AUTOSAR XML (schema 4-0-3)
package /AUTOSAR_NvM/SwComponentTypes
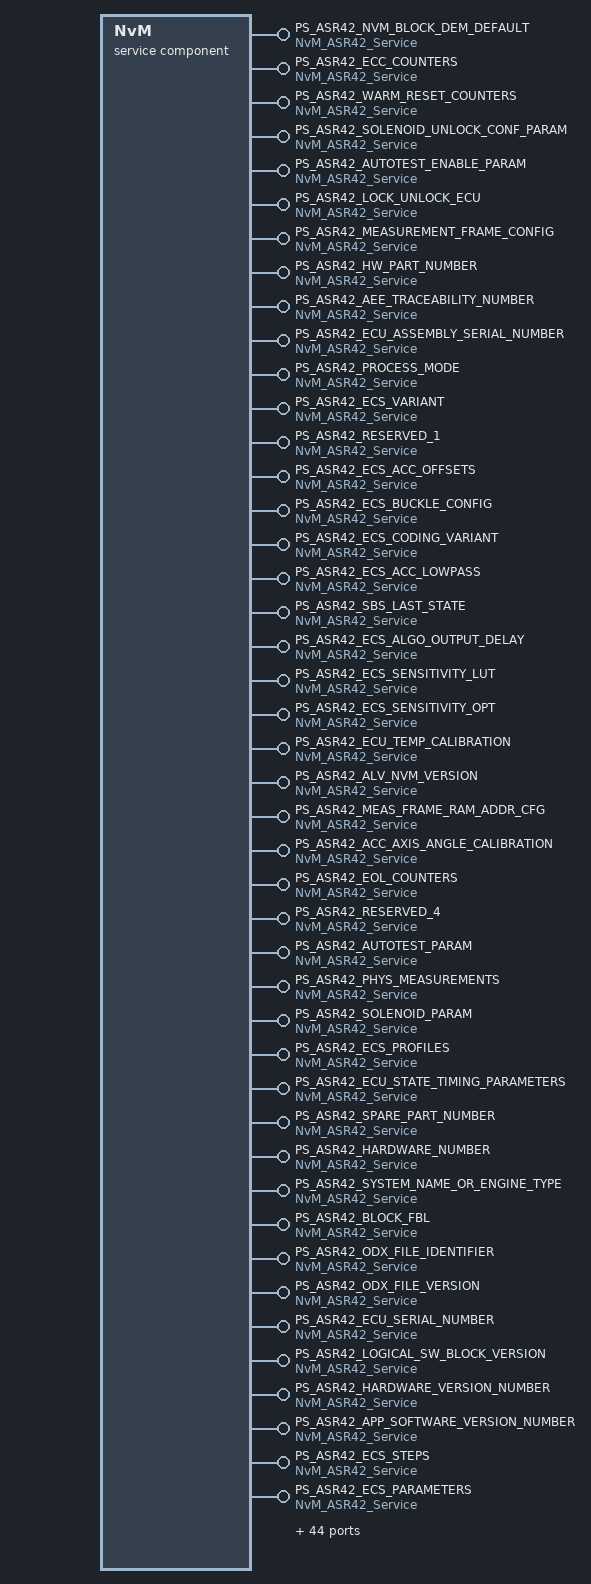
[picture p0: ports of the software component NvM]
  service sw component type NvM
    88 x provide port:
      PS_ASR42_NVM_BLOCK_DEM_DEFAULT: provided-interface=NvM_ASR42_Service
      PS_ASR42_ECC_COUNTERS: provided-interface=NvM_ASR42_Service
      PS_ASR42_WARM_RESET_COUNTERS: provided-interface=NvM_ASR42_Service
      PS_ASR42_SOLENOID_UNLOCK_CONF_PARAM: provided-interface=NvM_ASR42_Service
      PS_ASR42_AUTOTEST_ENABLE_PARAM: provided-interface=NvM_ASR42_Service
      PS_ASR42_LOCK_UNLOCK_ECU: provided-interface=NvM_ASR42_Service
      PS_ASR42_MEASUREMENT_FRAME_CONFIG: provided-interface=NvM_ASR42_Service
      PS_ASR42_HW_PART_NUMBER: provided-interface=NvM_ASR42_Service
      PS_ASR42_AEE_TRACEABILITY_NUMBER: provided-interface=NvM_ASR42_Service
      PS_ASR42_ECU_ASSEMBLY_SERIAL_NUMBER: provided-interface=NvM_ASR42_Service
      PS_ASR42_PROCESS_MODE: provided-interface=NvM_ASR42_Service
      PS_ASR42_ECS_VARIANT: provided-interface=NvM_ASR42_Service
      PS_ASR42_RESERVED_1: provided-interface=NvM_ASR42_Service
      PS_ASR42_ECS_ACC_OFFSETS: provided-interface=NvM_ASR42_Service
      PS_ASR42_ECS_BUCKLE_CONFIG: provided-interface=NvM_ASR42_Service
      PS_ASR42_ECS_CODING_VARIANT: provided-interface=NvM_ASR42_Service
      PS_ASR42_ECS_ACC_LOWPASS: provided-interface=NvM_ASR42_Service
      PS_ASR42_SBS_LAST_STATE: provided-interface=NvM_ASR42_Service
      PS_ASR42_ECS_ALGO_OUTPUT_DELAY: provided-interface=NvM_ASR42_Service
      PS_ASR42_ECS_SENSITIVITY_LUT: provided-interface=NvM_ASR42_Service
      PS_ASR42_ECS_SENSITIVITY_OPT: provided-interface=NvM_ASR42_Service
      PS_ASR42_ECU_TEMP_CALIBRATION: provided-interface=NvM_ASR42_Service
      PS_ASR42_ALV_NVM_VERSION: provided-interface=NvM_ASR42_Service
      PS_ASR42_MEAS_FRAME_RAM_ADDR_CFG: provided-interface=NvM_ASR42_Service
      PS_ASR42_ACC_AXIS_ANGLE_CALIBRATION: provided-interface=NvM_ASR42_Service
      PS_ASR42_EOL_COUNTERS: provided-interface=NvM_ASR42_Service
      PS_ASR42_RESERVED_4: provided-interface=NvM_ASR42_Service
      PS_ASR42_AUTOTEST_PARAM: provided-interface=NvM_ASR42_Service
      PS_ASR42_PHYS_MEASUREMENTS: provided-interface=NvM_ASR42_Service
      PS_ASR42_SOLENOID_PARAM: provided-interface=NvM_ASR42_Service
      PS_ASR42_ECS_PROFILES: provided-interface=NvM_ASR42_Service
      PS_ASR42_ECU_STATE_TIMING_PARAMETERS: provided-interface=NvM_ASR42_Service
      PS_ASR42_SPARE_PART_NUMBER: provided-interface=NvM_ASR42_Service
      PS_ASR42_HARDWARE_NUMBER: provided-interface=NvM_ASR42_Service
      PS_ASR42_SYSTEM_NAME_OR_ENGINE_TYPE: provided-interface=NvM_ASR42_Service
      PS_ASR42_BLOCK_FBL: provided-interface=NvM_ASR42_Service
      PS_ASR42_ODX_FILE_IDENTIFIER: provided-interface=NvM_ASR42_Service
      PS_ASR42_ODX_FILE_VERSION: provided-interface=NvM_ASR42_Service
      PS_ASR42_ECU_SERIAL_NUMBER: provided-interface=NvM_ASR42_Service
      PS_ASR42_LOGICAL_SW_BLOCK_VERSION: provided-interface=NvM_ASR42_Service
      PS_ASR42_HARDWARE_VERSION_NUMBER: provided-interface=NvM_ASR42_Service
      PS_ASR42_APP_SOFTWARE_VERSION_NUMBER: provided-interface=NvM_ASR42_Service
      PS_ASR42_ECS_STEPS: provided-interface=NvM_ASR42_Service
      PS_ASR42_ECS_PARAMETERS: provided-interface=NvM_ASR42_Service
      PS_NVM_BLOCK_DEM_DEFAULT: provided-interface=NvMService
      PS_ECC_COUNTERS: provided-interface=NvMService
      PS_WARM_RESET_COUNTERS: provided-interface=NvMService
      PS_SOLENOID_UNLOCK_CONF_PARAM: provided-interface=NvMService
      PS_AUTOTEST_ENABLE_PARAM: provided-interface=NvMService
      PS_LOCK_UNLOCK_ECU: provided-interface=NvMService
      PS_MEASUREMENT_FRAME_CONFIG: provided-interface=NvMService
      PS_HW_PART_NUMBER: provided-interface=NvMService
      PS_AEE_TRACEABILITY_NUMBER: provided-interface=NvMService
      PS_ECU_ASSEMBLY_SERIAL_NUMBER: provided-interface=NvMService
      PS_PROCESS_MODE: provided-interface=NvMService
      PS_ECS_VARIANT: provided-interface=NvMService
      PS_RESERVED_1: provided-interface=NvMService
      PS_ECS_ACC_OFFSETS: provided-interface=NvMService
      PS_ECS_BUCKLE_CONFIG: provided-interface=NvMService
      PS_ECS_CODING_VARIANT: provided-interface=NvMService
      PS_ECS_ACC_LOWPASS: provided-interface=NvMService
      PS_SBS_LAST_STATE: provided-interface=NvMService
      PS_ECS_ALGO_OUTPUT_DELAY: provided-interface=NvMService
      PS_ECS_SENSITIVITY_LUT: provided-interface=NvMService
      PS_ECS_SENSITIVITY_OPT: provided-interface=NvMService
      PS_ECU_TEMP_CALIBRATION: provided-interface=NvMService
      PS_ALV_NVM_VERSION: provided-interface=NvMService
      PS_MEAS_FRAME_RAM_ADDR_CFG: provided-interface=NvMService
      PS_ACC_AXIS_ANGLE_CALIBRATION: provided-interface=NvMService
      PS_EOL_COUNTERS: provided-interface=NvMService
      PS_RESERVED_4: provided-interface=NvMService
      PS_AUTOTEST_PARAM: provided-interface=NvMService
      PS_PHYS_MEASUREMENTS: provided-interface=NvMService
      PS_SOLENOID_PARAM: provided-interface=NvMService
      PS_ECS_PROFILES: provided-interface=NvMService
      PS_ECU_STATE_TIMING_PARAMETERS: provided-interface=NvMService
      PS_SPARE_PART_NUMBER: provided-interface=NvMService
      PS_HARDWARE_NUMBER: provided-interface=NvMService
      PS_SYSTEM_NAME_OR_ENGINE_TYPE: provided-interface=NvMService
      PS_BLOCK_FBL: provided-interface=NvMService
      PS_ODX_FILE_IDENTIFIER: provided-interface=NvMService
      PS_ODX_FILE_VERSION: provided-interface=NvMService
      PS_ECU_SERIAL_NUMBER: provided-interface=NvMService
      PS_LOGICAL_SW_BLOCK_VERSION: provided-interface=NvMService
      PS_HARDWARE_VERSION_NUMBER: provided-interface=NvMService
      PS_APP_SOFTWARE_VERSION_NUMBER: provided-interface=NvMService
      PS_ECS_STEPS: provided-interface=NvMService
      PS_ECS_PARAMETERS: provided-interface=NvMService
    behavior NvMIntBeh: handle-termination-and-restart=NO-SUPPORT
      1056 x operation invoked event:
        EV_ASR42_GetErrorStatus_NVM_BLOCK_DEM_DEFAULT: start-on-event=RE_ASR42_GetErrorStatus, operation=PS_ASR42_NVM_BLOCK_DEM_DEFAULT.GetErrorStatus
        EV_ASR42_SetDataIndex_NVM_BLOCK_DEM_DEFAULT: start-on-event=RE_ASR42_SetDataIndex, operation=PS_ASR42_NVM_BLOCK_DEM_DEFAULT.SetDataIndex
        EV_ASR42_GetDataIndex_NVM_BLOCK_DEM_DEFAULT: start-on-event=RE_ASR42_GetDataIndex, operation=PS_ASR42_NVM_BLOCK_DEM_DEFAULT.GetDataIndex
        EV_ASR42_SetRamBlockStatus_NVM_BLOCK_DEM_DEFAULT: start-on-event=RE_ASR42_SetRamBlockStatus, operation=PS_ASR42_NVM_BLOCK_DEM_DEFAULT.SetRamBlockStatus
        EV_ASR42_ReadBlock_NVM_BLOCK_DEM_DEFAULT: start-on-event=RE_ASR42_ReadBlock, operation=PS_ASR42_NVM_BLOCK_DEM_DEFAULT.ReadBlock
        EV_ASR42_ReadPRAMBlock_NVM_BLOCK_DEM_DEFAULT: start-on-event=RE_ASR42_ReadPRAMBlock, operation=PS_ASR42_NVM_BLOCK_DEM_DEFAULT.ReadPRAMBlock
        EV_ASR42_WriteBlock_NVM_BLOCK_DEM_DEFAULT: start-on-event=RE_ASR42_WriteBlock, operation=PS_ASR42_NVM_BLOCK_DEM_DEFAULT.WriteBlock
        EV_ASR42_WritePRAMBlock_NVM_BLOCK_DEM_DEFAULT: start-on-event=RE_ASR42_WritePRAMBlock, operation=PS_ASR42_NVM_BLOCK_DEM_DEFAULT.WritePRAMBlock
        EV_ASR42_RestoreBlockDefaults_NVM_BLOCK_DEM_DEFAULT: start-on-event=RE_ASR42_RestoreBlockDefaults, operation=PS_ASR42_NVM_BLOCK_DEM_DEFAULT.RestoreBlockDefaults
        EV_ASR42_RestorePRAMBlockDefaults_NVM_BLOCK_DEM_DEFAULT: start-on-event=RE_ASR42_RestorePRAMBlockDefaults, operation=PS_ASR42_NVM_BLOCK_DEM_DEFAULT.RestorePRAMBlockDefaults
        EV_ASR42_EraseBlock_NVM_BLOCK_DEM_DEFAULT: start-on-event=RE_ASR42_EraseBlock, operation=PS_ASR42_NVM_BLOCK_DEM_DEFAULT.EraseBlock
        EV_ASR42_InvalidateNvBlock_NVM_BLOCK_DEM_DEFAULT: start-on-event=RE_ASR42_InvalidateNvBlock, operation=PS_ASR42_NVM_BLOCK_DEM_DEFAULT.InvalidateNvBlock
        EV_ASR42_GetErrorStatus_ECC_COUNTERS: start-on-event=RE_ASR42_GetErrorStatus, operation=PS_ASR42_ECC_COUNTERS.GetErrorStatus
        EV_ASR42_SetDataIndex_ECC_COUNTERS: start-on-event=RE_ASR42_SetDataIndex, operation=PS_ASR42_ECC_COUNTERS.SetDataIndex
        EV_ASR42_GetDataIndex_ECC_COUNTERS: start-on-event=RE_ASR42_GetDataIndex, operation=PS_ASR42_ECC_COUNTERS.GetDataIndex
        EV_ASR42_SetRamBlockStatus_ECC_COUNTERS: start-on-event=RE_ASR42_SetRamBlockStatus, operation=PS_ASR42_ECC_COUNTERS.SetRamBlockStatus
        EV_ASR42_ReadBlock_ECC_COUNTERS: start-on-event=RE_ASR42_ReadBlock, operation=PS_ASR42_ECC_COUNTERS.ReadBlock
        EV_ASR42_ReadPRAMBlock_ECC_COUNTERS: start-on-event=RE_ASR42_ReadPRAMBlock, operation=PS_ASR42_ECC_COUNTERS.ReadPRAMBlock
        EV_ASR42_WriteBlock_ECC_COUNTERS: start-on-event=RE_ASR42_WriteBlock, operation=PS_ASR42_ECC_COUNTERS.WriteBlock
        EV_ASR42_WritePRAMBlock_ECC_COUNTERS: start-on-event=RE_ASR42_WritePRAMBlock, operation=PS_ASR42_ECC_COUNTERS.WritePRAMBlock
        EV_ASR42_RestoreBlockDefaults_ECC_COUNTERS: start-on-event=RE_ASR42_RestoreBlockDefaults, operation=PS_ASR42_ECC_COUNTERS.RestoreBlockDefaults
        EV_ASR42_RestorePRAMBlockDefaults_ECC_COUNTERS: start-on-event=RE_ASR42_RestorePRAMBlockDefaults, operation=PS_ASR42_ECC_COUNTERS.RestorePRAMBlockDefaults
        EV_ASR42_EraseBlock_ECC_COUNTERS: start-on-event=RE_ASR42_EraseBlock, operation=PS_ASR42_ECC_COUNTERS.EraseBlock
        EV_ASR42_InvalidateNvBlock_ECC_COUNTERS: start-on-event=RE_ASR42_InvalidateNvBlock, operation=PS_ASR42_ECC_COUNTERS.InvalidateNvBlock
        EV_ASR42_GetErrorStatus_WARM_RESET_COUNTERS: start-on-event=RE_ASR42_GetErrorStatus, operation=PS_ASR42_WARM_RESET_COUNTERS.GetErrorStatus
        EV_ASR42_SetDataIndex_WARM_RESET_COUNTERS: start-on-event=RE_ASR42_SetDataIndex, operation=PS_ASR42_WARM_RESET_COUNTERS.SetDataIndex
        EV_ASR42_GetDataIndex_WARM_RESET_COUNTERS: start-on-event=RE_ASR42_GetDataIndex, operation=PS_ASR42_WARM_RESET_COUNTERS.GetDataIndex
        EV_ASR42_SetRamBlockStatus_WARM_RESET_COUNTERS: start-on-event=RE_ASR42_SetRamBlockStatus, operation=PS_ASR42_WARM_RESET_COUNTERS.SetRamBlockStatus
        EV_ASR42_ReadBlock_WARM_RESET_COUNTERS: start-on-event=RE_ASR42_ReadBlock, operation=PS_ASR42_WARM_RESET_COUNTERS.ReadBlock
        EV_ASR42_ReadPRAMBlock_WARM_RESET_COUNTERS: start-on-event=RE_ASR42_ReadPRAMBlock, operation=PS_ASR42_WARM_RESET_COUNTERS.ReadPRAMBlock
        EV_ASR42_WriteBlock_WARM_RESET_COUNTERS: start-on-event=RE_ASR42_WriteBlock, operation=PS_ASR42_WARM_RESET_COUNTERS.WriteBlock
        EV_ASR42_WritePRAMBlock_WARM_RESET_COUNTERS: start-on-event=RE_ASR42_WritePRAMBlock, operation=PS_ASR42_WARM_RESET_COUNTERS.WritePRAMBlock
        EV_ASR42_RestoreBlockDefaults_WARM_RESET_COUNTERS: start-on-event=RE_ASR42_RestoreBlockDefaults, operation=PS_ASR42_WARM_RESET_COUNTERS.RestoreBlockDefaults
        EV_ASR42_RestorePRAMBlockDefaults_WARM_RESET_COUNTERS: start-on-event=RE_ASR42_RestorePRAMBlockDefaults, operation=PS_ASR42_WARM_RESET_COUNTERS.RestorePRAMBlockDefaults
        EV_ASR42_EraseBlock_WARM_RESET_COUNTERS: start-on-event=RE_ASR42_EraseBlock, operation=PS_ASR42_WARM_RESET_COUNTERS.EraseBlock
        EV_ASR42_InvalidateNvBlock_WARM_RESET_COUNTERS: start-on-event=RE_ASR42_InvalidateNvBlock, operation=PS_ASR42_WARM_RESET_COUNTERS.InvalidateNvBlock
        EV_ASR42_GetErrorStatus_SOLENOID_UNLOCK_CONF_PARAM: start-on-event=RE_ASR42_GetErrorStatus, operation=PS_ASR42_SOLENOID_UNLOCK_CONF_PARAM.GetErrorStatus
        EV_ASR42_SetDataIndex_SOLENOID_UNLOCK_CONF_PARAM: start-on-event=RE_ASR42_SetDataIndex, operation=PS_ASR42_SOLENOID_UNLOCK_CONF_PARAM.SetDataIndex
        EV_ASR42_GetDataIndex_SOLENOID_UNLOCK_CONF_PARAM: start-on-event=RE_ASR42_GetDataIndex, operation=PS_ASR42_SOLENOID_UNLOCK_CONF_PARAM.GetDataIndex
        EV_ASR42_SetRamBlockStatus_SOLENOID_UNLOCK_CONF_PARAM: start-on-event=RE_ASR42_SetRamBlockStatus, operation=PS_ASR42_SOLENOID_UNLOCK_CONF_PARAM.SetRamBlockStatus
        EV_ASR42_ReadBlock_SOLENOID_UNLOCK_CONF_PARAM: start-on-event=RE_ASR42_ReadBlock, operation=PS_ASR42_SOLENOID_UNLOCK_CONF_PARAM.ReadBlock
        EV_ASR42_ReadPRAMBlock_SOLENOID_UNLOCK_CONF_PARAM: start-on-event=RE_ASR42_ReadPRAMBlock, operation=PS_ASR42_SOLENOID_UNLOCK_CONF_PARAM.ReadPRAMBlock
        EV_ASR42_WriteBlock_SOLENOID_UNLOCK_CONF_PARAM: start-on-event=RE_ASR42_WriteBlock, operation=PS_ASR42_SOLENOID_UNLOCK_CONF_PARAM.WriteBlock
        EV_ASR42_WritePRAMBlock_SOLENOID_UNLOCK_CONF_PARAM: start-on-event=RE_ASR42_WritePRAMBlock, operation=PS_ASR42_SOLENOID_UNLOCK_CONF_PARAM.WritePRAMBlock
        EV_ASR42_RestoreBlockDefaults_SOLENOID_UNLOCK_CONF_PARAM: start-on-event=RE_ASR42_RestoreBlockDefaults, operation=PS_ASR42_SOLENOID_UNLOCK_CONF_PARAM.RestoreBlockDefaults
        EV_ASR42_RestorePRAMBlockDefaults_SOLENOID_UNLOCK_CONF_PARAM: start-on-event=RE_ASR42_RestorePRAMBlockDefaults, operation=PS_ASR42_SOLENOID_UNLOCK_CONF_PARAM.RestorePRAMBlockDefaults
        EV_ASR42_EraseBlock_SOLENOID_UNLOCK_CONF_PARAM: start-on-event=RE_ASR42_EraseBlock, operation=PS_ASR42_SOLENOID_UNLOCK_CONF_PARAM.EraseBlock
        EV_ASR42_InvalidateNvBlock_SOLENOID_UNLOCK_CONF_PARAM: start-on-event=RE_ASR42_InvalidateNvBlock, operation=PS_ASR42_SOLENOID_UNLOCK_CONF_PARAM.InvalidateNvBlock
        EV_ASR42_GetErrorStatus_AUTOTEST_ENABLE_PARAM: start-on-event=RE_ASR42_GetErrorStatus, operation=PS_ASR42_AUTOTEST_ENABLE_PARAM.GetErrorStatus
        EV_ASR42_SetDataIndex_AUTOTEST_ENABLE_PARAM: start-on-event=RE_ASR42_SetDataIndex, operation=PS_ASR42_AUTOTEST_ENABLE_PARAM.SetDataIndex
        EV_ASR42_GetDataIndex_AUTOTEST_ENABLE_PARAM: start-on-event=RE_ASR42_GetDataIndex, operation=PS_ASR42_AUTOTEST_ENABLE_PARAM.GetDataIndex
        EV_ASR42_SetRamBlockStatus_AUTOTEST_ENABLE_PARAM: start-on-event=RE_ASR42_SetRamBlockStatus, operation=PS_ASR42_AUTOTEST_ENABLE_PARAM.SetRamBlockStatus
        EV_ASR42_ReadBlock_AUTOTEST_ENABLE_PARAM: start-on-event=RE_ASR42_ReadBlock, operation=PS_ASR42_AUTOTEST_ENABLE_PARAM.ReadBlock
        EV_ASR42_ReadPRAMBlock_AUTOTEST_ENABLE_PARAM: start-on-event=RE_ASR42_ReadPRAMBlock, operation=PS_ASR42_AUTOTEST_ENABLE_PARAM.ReadPRAMBlock
        EV_ASR42_WriteBlock_AUTOTEST_ENABLE_PARAM: start-on-event=RE_ASR42_WriteBlock, operation=PS_ASR42_AUTOTEST_ENABLE_PARAM.WriteBlock
        EV_ASR42_WritePRAMBlock_AUTOTEST_ENABLE_PARAM: start-on-event=RE_ASR42_WritePRAMBlock, operation=PS_ASR42_AUTOTEST_ENABLE_PARAM.WritePRAMBlock
        EV_ASR42_RestoreBlockDefaults_AUTOTEST_ENABLE_PARAM: start-on-event=RE_ASR42_RestoreBlockDefaults, operation=PS_ASR42_AUTOTEST_ENABLE_PARAM.RestoreBlockDefaults
        EV_ASR42_RestorePRAMBlockDefaults_AUTOTEST_ENABLE_PARAM: start-on-event=RE_ASR42_RestorePRAMBlockDefaults, operation=PS_ASR42_AUTOTEST_ENABLE_PARAM.RestorePRAMBlockDefaults
        EV_ASR42_EraseBlock_AUTOTEST_ENABLE_PARAM: start-on-event=RE_ASR42_EraseBlock, operation=PS_ASR42_AUTOTEST_ENABLE_PARAM.EraseBlock
        EV_ASR42_InvalidateNvBlock_AUTOTEST_ENABLE_PARAM: start-on-event=RE_ASR42_InvalidateNvBlock, operation=PS_ASR42_AUTOTEST_ENABLE_PARAM.InvalidateNvBlock
        EV_ASR42_GetErrorStatus_LOCK_UNLOCK_ECU: start-on-event=RE_ASR42_GetErrorStatus, operation=PS_ASR42_LOCK_UNLOCK_ECU.GetErrorStatus
        EV_ASR42_SetDataIndex_LOCK_UNLOCK_ECU: start-on-event=RE_ASR42_SetDataIndex, operation=PS_ASR42_LOCK_UNLOCK_ECU.SetDataIndex
        EV_ASR42_GetDataIndex_LOCK_UNLOCK_ECU: start-on-event=RE_ASR42_GetDataIndex, operation=PS_ASR42_LOCK_UNLOCK_ECU.GetDataIndex
        EV_ASR42_SetRamBlockStatus_LOCK_UNLOCK_ECU: start-on-event=RE_ASR42_SetRamBlockStatus, operation=PS_ASR42_LOCK_UNLOCK_ECU.SetRamBlockStatus
        EV_ASR42_ReadBlock_LOCK_UNLOCK_ECU: start-on-event=RE_ASR42_ReadBlock, operation=PS_ASR42_LOCK_UNLOCK_ECU.ReadBlock
        EV_ASR42_ReadPRAMBlock_LOCK_UNLOCK_ECU: start-on-event=RE_ASR42_ReadPRAMBlock, operation=PS_ASR42_LOCK_UNLOCK_ECU.ReadPRAMBlock
        EV_ASR42_WriteBlock_LOCK_UNLOCK_ECU: start-on-event=RE_ASR42_WriteBlock, operation=PS_ASR42_LOCK_UNLOCK_ECU.WriteBlock
        EV_ASR42_WritePRAMBlock_LOCK_UNLOCK_ECU: start-on-event=RE_ASR42_WritePRAMBlock, operation=PS_ASR42_LOCK_UNLOCK_ECU.WritePRAMBlock
        EV_ASR42_RestoreBlockDefaults_LOCK_UNLOCK_ECU: start-on-event=RE_ASR42_RestoreBlockDefaults, operation=PS_ASR42_LOCK_UNLOCK_ECU.RestoreBlockDefaults
        EV_ASR42_RestorePRAMBlockDefaults_LOCK_UNLOCK_ECU: start-on-event=RE_ASR42_RestorePRAMBlockDefaults, operation=PS_ASR42_LOCK_UNLOCK_ECU.RestorePRAMBlockDefaults
        EV_ASR42_EraseBlock_LOCK_UNLOCK_ECU: start-on-event=RE_ASR42_EraseBlock, operation=PS_ASR42_LOCK_UNLOCK_ECU.EraseBlock
        EV_ASR42_InvalidateNvBlock_LOCK_UNLOCK_ECU: start-on-event=RE_ASR42_InvalidateNvBlock, operation=PS_ASR42_LOCK_UNLOCK_ECU.InvalidateNvBlock
        EV_ASR42_GetErrorStatus_MEASUREMENT_FRAME_CONFIG: start-on-event=RE_ASR42_GetErrorStatus, operation=PS_ASR42_MEASUREMENT_FRAME_CONFIG.GetErrorStatus
        EV_ASR42_SetDataIndex_MEASUREMENT_FRAME_CONFIG: start-on-event=RE_ASR42_SetDataIndex, operation=PS_ASR42_MEASUREMENT_FRAME_CONFIG.SetDataIndex
        EV_ASR42_GetDataIndex_MEASUREMENT_FRAME_CONFIG: start-on-event=RE_ASR42_GetDataIndex, operation=PS_ASR42_MEASUREMENT_FRAME_CONFIG.GetDataIndex
        EV_ASR42_SetRamBlockStatus_MEASUREMENT_FRAME_CONFIG: start-on-event=RE_ASR42_SetRamBlockStatus, operation=PS_ASR42_MEASUREMENT_FRAME_CONFIG.SetRamBlockStatus
        EV_ASR42_ReadBlock_MEASUREMENT_FRAME_CONFIG: start-on-event=RE_ASR42_ReadBlock, operation=PS_ASR42_MEASUREMENT_FRAME_CONFIG.ReadBlock
        EV_ASR42_ReadPRAMBlock_MEASUREMENT_FRAME_CONFIG: start-on-event=RE_ASR42_ReadPRAMBlock, operation=PS_ASR42_MEASUREMENT_FRAME_CONFIG.ReadPRAMBlock
        EV_ASR42_WriteBlock_MEASUREMENT_FRAME_CONFIG: start-on-event=RE_ASR42_WriteBlock, operation=PS_ASR42_MEASUREMENT_FRAME_CONFIG.WriteBlock
        EV_ASR42_WritePRAMBlock_MEASUREMENT_FRAME_CONFIG: start-on-event=RE_ASR42_WritePRAMBlock, operation=PS_ASR42_MEASUREMENT_FRAME_CONFIG.WritePRAMBlock
        EV_ASR42_RestoreBlockDefaults_MEASUREMENT_FRAME_CONFIG: start-on-event=RE_ASR42_RestoreBlockDefaults, operation=PS_ASR42_MEASUREMENT_FRAME_CONFIG.RestoreBlockDefaults
        EV_ASR42_RestorePRAMBlockDefaults_MEASUREMENT_FRAME_CONFIG: start-on-event=RE_ASR42_RestorePRAMBlockDefaults, operation=PS_ASR42_MEASUREMENT_FRAME_CONFIG.RestorePRAMBlockDefaults
        EV_ASR42_EraseBlock_MEASUREMENT_FRAME_CONFIG: start-on-event=RE_ASR42_EraseBlock, operation=PS_ASR42_MEASUREMENT_FRAME_CONFIG.EraseBlock
        EV_ASR42_InvalidateNvBlock_MEASUREMENT_FRAME_CONFIG: start-on-event=RE_ASR42_InvalidateNvBlock, operation=PS_ASR42_MEASUREMENT_FRAME_CONFIG.InvalidateNvBlock
        EV_ASR42_GetErrorStatus_HW_PART_NUMBER: start-on-event=RE_ASR42_GetErrorStatus, operation=PS_ASR42_HW_PART_NUMBER.GetErrorStatus
        EV_ASR42_SetDataIndex_HW_PART_NUMBER: start-on-event=RE_ASR42_SetDataIndex, operation=PS_ASR42_HW_PART_NUMBER.SetDataIndex
        EV_ASR42_GetDataIndex_HW_PART_NUMBER: start-on-event=RE_ASR42_GetDataIndex, operation=PS_ASR42_HW_PART_NUMBER.GetDataIndex
        EV_ASR42_SetRamBlockStatus_HW_PART_NUMBER: start-on-event=RE_ASR42_SetRamBlockStatus, operation=PS_ASR42_HW_PART_NUMBER.SetRamBlockStatus
        EV_ASR42_ReadBlock_HW_PART_NUMBER: start-on-event=RE_ASR42_ReadBlock, operation=PS_ASR42_HW_PART_NUMBER.ReadBlock
        EV_ASR42_ReadPRAMBlock_HW_PART_NUMBER: start-on-event=RE_ASR42_ReadPRAMBlock, operation=PS_ASR42_HW_PART_NUMBER.ReadPRAMBlock
        EV_ASR42_WriteBlock_HW_PART_NUMBER: start-on-event=RE_ASR42_WriteBlock, operation=PS_ASR42_HW_PART_NUMBER.WriteBlock
        EV_ASR42_WritePRAMBlock_HW_PART_NUMBER: start-on-event=RE_ASR42_WritePRAMBlock, operation=PS_ASR42_HW_PART_NUMBER.WritePRAMBlock
        EV_ASR42_RestoreBlockDefaults_HW_PART_NUMBER: start-on-event=RE_ASR42_RestoreBlockDefaults, operation=PS_ASR42_HW_PART_NUMBER.RestoreBlockDefaults
        EV_ASR42_RestorePRAMBlockDefaults_HW_PART_NUMBER: start-on-event=RE_ASR42_RestorePRAMBlockDefaults, operation=PS_ASR42_HW_PART_NUMBER.RestorePRAMBlockDefaults
        EV_ASR42_EraseBlock_HW_PART_NUMBER: start-on-event=RE_ASR42_EraseBlock, operation=PS_ASR42_HW_PART_NUMBER.EraseBlock
        EV_ASR42_InvalidateNvBlock_HW_PART_NUMBER: start-on-event=RE_ASR42_InvalidateNvBlock, operation=PS_ASR42_HW_PART_NUMBER.InvalidateNvBlock
        EV_ASR42_GetErrorStatus_AEE_TRACEABILITY_NUMBER: start-on-event=RE_ASR42_GetErrorStatus, operation=PS_ASR42_AEE_TRACEABILITY_NUMBER.GetErrorStatus
        EV_ASR42_SetDataIndex_AEE_TRACEABILITY_NUMBER: start-on-event=RE_ASR42_SetDataIndex, operation=PS_ASR42_AEE_TRACEABILITY_NUMBER.SetDataIndex
        EV_ASR42_GetDataIndex_AEE_TRACEABILITY_NUMBER: start-on-event=RE_ASR42_GetDataIndex, operation=PS_ASR42_AEE_TRACEABILITY_NUMBER.GetDataIndex
        EV_ASR42_SetRamBlockStatus_AEE_TRACEABILITY_NUMBER: start-on-event=RE_ASR42_SetRamBlockStatus, operation=PS_ASR42_AEE_TRACEABILITY_NUMBER.SetRamBlockStatus
        EV_ASR42_ReadBlock_AEE_TRACEABILITY_NUMBER: start-on-event=RE_ASR42_ReadBlock, operation=PS_ASR42_AEE_TRACEABILITY_NUMBER.ReadBlock
        EV_ASR42_ReadPRAMBlock_AEE_TRACEABILITY_NUMBER: start-on-event=RE_ASR42_ReadPRAMBlock, operation=PS_ASR42_AEE_TRACEABILITY_NUMBER.ReadPRAMBlock
        EV_ASR42_WriteBlock_AEE_TRACEABILITY_NUMBER: start-on-event=RE_ASR42_WriteBlock, operation=PS_ASR42_AEE_TRACEABILITY_NUMBER.WriteBlock
        EV_ASR42_WritePRAMBlock_AEE_TRACEABILITY_NUMBER: start-on-event=RE_ASR42_WritePRAMBlock, operation=PS_ASR42_AEE_TRACEABILITY_NUMBER.WritePRAMBlock
        EV_ASR42_RestoreBlockDefaults_AEE_TRACEABILITY_NUMBER: start-on-event=RE_ASR42_RestoreBlockDefaults, operation=PS_ASR42_AEE_TRACEABILITY_NUMBER.RestoreBlockDefaults
        EV_ASR42_RestorePRAMBlockDefaults_AEE_TRACEABILITY_NUMBER: start-on-event=RE_ASR42_RestorePRAMBlockDefaults, operation=PS_ASR42_AEE_TRACEABILITY_NUMBER.RestorePRAMBlockDefaults
        EV_ASR42_EraseBlock_AEE_TRACEABILITY_NUMBER: start-on-event=RE_ASR42_EraseBlock, operation=PS_ASR42_AEE_TRACEABILITY_NUMBER.EraseBlock
        EV_ASR42_InvalidateNvBlock_AEE_TRACEABILITY_NUMBER: start-on-event=RE_ASR42_InvalidateNvBlock, operation=PS_ASR42_AEE_TRACEABILITY_NUMBER.InvalidateNvBlock
        EV_ASR42_GetErrorStatus_ECU_ASSEMBLY_SERIAL_NUMBER: start-on-event=RE_ASR42_GetErrorStatus, operation=PS_ASR42_ECU_ASSEMBLY_SERIAL_NUMBER.GetErrorStatus
        EV_ASR42_SetDataIndex_ECU_ASSEMBLY_SERIAL_NUMBER: start-on-event=RE_ASR42_SetDataIndex, operation=PS_ASR42_ECU_ASSEMBLY_SERIAL_NUMBER.SetDataIndex
        EV_ASR42_GetDataIndex_ECU_ASSEMBLY_SERIAL_NUMBER: start-on-event=RE_ASR42_GetDataIndex, operation=PS_ASR42_ECU_ASSEMBLY_SERIAL_NUMBER.GetDataIndex
        EV_ASR42_SetRamBlockStatus_ECU_ASSEMBLY_SERIAL_NUMBER: start-on-event=RE_ASR42_SetRamBlockStatus, operation=PS_ASR42_ECU_ASSEMBLY_SERIAL_NUMBER.SetRamBlockStatus
        EV_ASR42_ReadBlock_ECU_ASSEMBLY_SERIAL_NUMBER: start-on-event=RE_ASR42_ReadBlock, operation=PS_ASR42_ECU_ASSEMBLY_SERIAL_NUMBER.ReadBlock
        EV_ASR42_ReadPRAMBlock_ECU_ASSEMBLY_SERIAL_NUMBER: start-on-event=RE_ASR42_ReadPRAMBlock, operation=PS_ASR42_ECU_ASSEMBLY_SERIAL_NUMBER.ReadPRAMBlock
        EV_ASR42_WriteBlock_ECU_ASSEMBLY_SERIAL_NUMBER: start-on-event=RE_ASR42_WriteBlock, operation=PS_ASR42_ECU_ASSEMBLY_SERIAL_NUMBER.WriteBlock
        EV_ASR42_WritePRAMBlock_ECU_ASSEMBLY_SERIAL_NUMBER: start-on-event=RE_ASR42_WritePRAMBlock, operation=PS_ASR42_ECU_ASSEMBLY_SERIAL_NUMBER.WritePRAMBlock
        EV_ASR42_RestoreBlockDefaults_ECU_ASSEMBLY_SERIAL_NUMBER: start-on-event=RE_ASR42_RestoreBlockDefaults, operation=PS_ASR42_ECU_ASSEMBLY_SERIAL_NUMBER.RestoreBlockDefaults
        EV_ASR42_RestorePRAMBlockDefaults_ECU_ASSEMBLY_SERIAL_NUMBER: start-on-event=RE_ASR42_RestorePRAMBlockDefaults, operation=PS_ASR42_ECU_ASSEMBLY_SERIAL_NUMBER.RestorePRAMBlockDefaults
        EV_ASR42_EraseBlock_ECU_ASSEMBLY_SERIAL_NUMBER: start-on-event=RE_ASR42_EraseBlock, operation=PS_ASR42_ECU_ASSEMBLY_SERIAL_NUMBER.EraseBlock
        EV_ASR42_InvalidateNvBlock_ECU_ASSEMBLY_SERIAL_NUMBER: start-on-event=RE_ASR42_InvalidateNvBlock, operation=PS_ASR42_ECU_ASSEMBLY_SERIAL_NUMBER.InvalidateNvBlock
        EV_ASR42_GetErrorStatus_PROCESS_MODE: start-on-event=RE_ASR42_GetErrorStatus, operation=PS_ASR42_PROCESS_MODE.GetErrorStatus
        EV_ASR42_SetDataIndex_PROCESS_MODE: start-on-event=RE_ASR42_SetDataIndex, operation=PS_ASR42_PROCESS_MODE.SetDataIndex
        EV_ASR42_GetDataIndex_PROCESS_MODE: start-on-event=RE_ASR42_GetDataIndex, operation=PS_ASR42_PROCESS_MODE.GetDataIndex
        EV_ASR42_SetRamBlockStatus_PROCESS_MODE: start-on-event=RE_ASR42_SetRamBlockStatus, operation=PS_ASR42_PROCESS_MODE.SetRamBlockStatus
        EV_ASR42_ReadBlock_PROCESS_MODE: start-on-event=RE_ASR42_ReadBlock, operation=PS_ASR42_PROCESS_MODE.ReadBlock
        EV_ASR42_ReadPRAMBlock_PROCESS_MODE: start-on-event=RE_ASR42_ReadPRAMBlock, operation=PS_ASR42_PROCESS_MODE.ReadPRAMBlock
        EV_ASR42_WriteBlock_PROCESS_MODE: start-on-event=RE_ASR42_WriteBlock, operation=PS_ASR42_PROCESS_MODE.WriteBlock
        EV_ASR42_WritePRAMBlock_PROCESS_MODE: start-on-event=RE_ASR42_WritePRAMBlock, operation=PS_ASR42_PROCESS_MODE.WritePRAMBlock
        EV_ASR42_RestoreBlockDefaults_PROCESS_MODE: start-on-event=RE_ASR42_RestoreBlockDefaults, operation=PS_ASR42_PROCESS_MODE.RestoreBlockDefaults
        EV_ASR42_RestorePRAMBlockDefaults_PROCESS_MODE: start-on-event=RE_ASR42_RestorePRAMBlockDefaults, operation=PS_ASR42_PROCESS_MODE.RestorePRAMBlockDefaults
        EV_ASR42_EraseBlock_PROCESS_MODE: start-on-event=RE_ASR42_EraseBlock, operation=PS_ASR42_PROCESS_MODE.EraseBlock
        EV_ASR42_InvalidateNvBlock_PROCESS_MODE: start-on-event=RE_ASR42_InvalidateNvBlock, operation=PS_ASR42_PROCESS_MODE.InvalidateNvBlock
        EV_ASR42_GetErrorStatus_ECS_VARIANT: start-on-event=RE_ASR42_GetErrorStatus, operation=PS_ASR42_ECS_VARIANT.GetErrorStatus
        EV_ASR42_SetDataIndex_ECS_VARIANT: start-on-event=RE_ASR42_SetDataIndex, operation=PS_ASR42_ECS_VARIANT.SetDataIndex
        EV_ASR42_GetDataIndex_ECS_VARIANT: start-on-event=RE_ASR42_GetDataIndex, operation=PS_ASR42_ECS_VARIANT.GetDataIndex
        EV_ASR42_SetRamBlockStatus_ECS_VARIANT: start-on-event=RE_ASR42_SetRamBlockStatus, operation=PS_ASR42_ECS_VARIANT.SetRamBlockStatus
        EV_ASR42_ReadBlock_ECS_VARIANT: start-on-event=RE_ASR42_ReadBlock, operation=PS_ASR42_ECS_VARIANT.ReadBlock
        EV_ASR42_ReadPRAMBlock_ECS_VARIANT: start-on-event=RE_ASR42_ReadPRAMBlock, operation=PS_ASR42_ECS_VARIANT.ReadPRAMBlock
        EV_ASR42_WriteBlock_ECS_VARIANT: start-on-event=RE_ASR42_WriteBlock, operation=PS_ASR42_ECS_VARIANT.WriteBlock
        EV_ASR42_WritePRAMBlock_ECS_VARIANT: start-on-event=RE_ASR42_WritePRAMBlock, operation=PS_ASR42_ECS_VARIANT.WritePRAMBlock
        EV_ASR42_RestoreBlockDefaults_ECS_VARIANT: start-on-event=RE_ASR42_RestoreBlockDefaults, operation=PS_ASR42_ECS_VARIANT.RestoreBlockDefaults
        EV_ASR42_RestorePRAMBlockDefaults_ECS_VARIANT: start-on-event=RE_ASR42_RestorePRAMBlockDefaults, operation=PS_ASR42_ECS_VARIANT.RestorePRAMBlockDefaults
        EV_ASR42_EraseBlock_ECS_VARIANT: start-on-event=RE_ASR42_EraseBlock, operation=PS_ASR42_ECS_VARIANT.EraseBlock
        EV_ASR42_InvalidateNvBlock_ECS_VARIANT: start-on-event=RE_ASR42_InvalidateNvBlock, operation=PS_ASR42_ECS_VARIANT.InvalidateNvBlock
        EV_ASR42_GetErrorStatus_RESERVED_1: start-on-event=RE_ASR42_GetErrorStatus, operation=PS_ASR42_RESERVED_1.GetErrorStatus
        EV_ASR42_SetDataIndex_RESERVED_1: start-on-event=RE_ASR42_SetDataIndex, operation=PS_ASR42_RESERVED_1.SetDataIndex
        EV_ASR42_GetDataIndex_RESERVED_1: start-on-event=RE_ASR42_GetDataIndex, operation=PS_ASR42_RESERVED_1.GetDataIndex
        EV_ASR42_SetRamBlockStatus_RESERVED_1: start-on-event=RE_ASR42_SetRamBlockStatus, operation=PS_ASR42_RESERVED_1.SetRamBlockStatus
        EV_ASR42_ReadBlock_RESERVED_1: start-on-event=RE_ASR42_ReadBlock, operation=PS_ASR42_RESERVED_1.ReadBlock
        EV_ASR42_ReadPRAMBlock_RESERVED_1: start-on-event=RE_ASR42_ReadPRAMBlock, operation=PS_ASR42_RESERVED_1.ReadPRAMBlock
        EV_ASR42_WriteBlock_RESERVED_1: start-on-event=RE_ASR42_WriteBlock, operation=PS_ASR42_RESERVED_1.WriteBlock
        EV_ASR42_WritePRAMBlock_RESERVED_1: start-on-event=RE_ASR42_WritePRAMBlock, operation=PS_ASR42_RESERVED_1.WritePRAMBlock
        EV_ASR42_RestoreBlockDefaults_RESERVED_1: start-on-event=RE_ASR42_RestoreBlockDefaults, operation=PS_ASR42_RESERVED_1.RestoreBlockDefaults
        EV_ASR42_RestorePRAMBlockDefaults_RESERVED_1: start-on-event=RE_ASR42_RestorePRAMBlockDefaults, operation=PS_ASR42_RESERVED_1.RestorePRAMBlockDefaults
        EV_ASR42_EraseBlock_RESERVED_1: start-on-event=RE_ASR42_EraseBlock, operation=PS_ASR42_RESERVED_1.EraseBlock
        EV_ASR42_InvalidateNvBlock_RESERVED_1: start-on-event=RE_ASR42_InvalidateNvBlock, operation=PS_ASR42_RESERVED_1.InvalidateNvBlock
        EV_ASR42_GetErrorStatus_ECS_ACC_OFFSETS: start-on-event=RE_ASR42_GetErrorStatus, operation=PS_ASR42_ECS_ACC_OFFSETS.GetErrorStatus
        EV_ASR42_SetDataIndex_ECS_ACC_OFFSETS: start-on-event=RE_ASR42_SetDataIndex, operation=PS_ASR42_ECS_ACC_OFFSETS.SetDataIndex
        EV_ASR42_GetDataIndex_ECS_ACC_OFFSETS: start-on-event=RE_ASR42_GetDataIndex, operation=PS_ASR42_ECS_ACC_OFFSETS.GetDataIndex
        EV_ASR42_SetRamBlockStatus_ECS_ACC_OFFSETS: start-on-event=RE_ASR42_SetRamBlockStatus, operation=PS_ASR42_ECS_ACC_OFFSETS.SetRamBlockStatus
        EV_ASR42_ReadBlock_ECS_ACC_OFFSETS: start-on-event=RE_ASR42_ReadBlock, operation=PS_ASR42_ECS_ACC_OFFSETS.ReadBlock
        EV_ASR42_ReadPRAMBlock_ECS_ACC_OFFSETS: start-on-event=RE_ASR42_ReadPRAMBlock, operation=PS_ASR42_ECS_ACC_OFFSETS.ReadPRAMBlock
        EV_ASR42_WriteBlock_ECS_ACC_OFFSETS: start-on-event=RE_ASR42_WriteBlock, operation=PS_ASR42_ECS_ACC_OFFSETS.WriteBlock
        EV_ASR42_WritePRAMBlock_ECS_ACC_OFFSETS: start-on-event=RE_ASR42_WritePRAMBlock, operation=PS_ASR42_ECS_ACC_OFFSETS.WritePRAMBlock
        EV_ASR42_RestoreBlockDefaults_ECS_ACC_OFFSETS: start-on-event=RE_ASR42_RestoreBlockDefaults, operation=PS_ASR42_ECS_ACC_OFFSETS.RestoreBlockDefaults
        EV_ASR42_RestorePRAMBlockDefaults_ECS_ACC_OFFSETS: start-on-event=RE_ASR42_RestorePRAMBlockDefaults, operation=PS_ASR42_ECS_ACC_OFFSETS.RestorePRAMBlockDefaults
        EV_ASR42_EraseBlock_ECS_ACC_OFFSETS: start-on-event=RE_ASR42_EraseBlock, operation=PS_ASR42_ECS_ACC_OFFSETS.EraseBlock
        EV_ASR42_InvalidateNvBlock_ECS_ACC_OFFSETS: start-on-event=RE_ASR42_InvalidateNvBlock, operation=PS_ASR42_ECS_ACC_OFFSETS.InvalidateNvBlock
        EV_ASR42_GetErrorStatus_ECS_BUCKLE_CONFIG: start-on-event=RE_ASR42_GetErrorStatus, operation=PS_ASR42_ECS_BUCKLE_CONFIG.GetErrorStatus
        EV_ASR42_SetDataIndex_ECS_BUCKLE_CONFIG: start-on-event=RE_ASR42_SetDataIndex, operation=PS_ASR42_ECS_BUCKLE_CONFIG.SetDataIndex
        EV_ASR42_GetDataIndex_ECS_BUCKLE_CONFIG: start-on-event=RE_ASR42_GetDataIndex, operation=PS_ASR42_ECS_BUCKLE_CONFIG.GetDataIndex
        EV_ASR42_SetRamBlockStatus_ECS_BUCKLE_CONFIG: start-on-event=RE_ASR42_SetRamBlockStatus, operation=PS_ASR42_ECS_BUCKLE_CONFIG.SetRamBlockStatus
        EV_ASR42_ReadBlock_ECS_BUCKLE_CONFIG: start-on-event=RE_ASR42_ReadBlock, operation=PS_ASR42_ECS_BUCKLE_CONFIG.ReadBlock
        EV_ASR42_ReadPRAMBlock_ECS_BUCKLE_CONFIG: start-on-event=RE_ASR42_ReadPRAMBlock, operation=PS_ASR42_ECS_BUCKLE_CONFIG.ReadPRAMBlock
        EV_ASR42_WriteBlock_ECS_BUCKLE_CONFIG: start-on-event=RE_ASR42_WriteBlock, operation=PS_ASR42_ECS_BUCKLE_CONFIG.WriteBlock
        EV_ASR42_WritePRAMBlock_ECS_BUCKLE_CONFIG: start-on-event=RE_ASR42_WritePRAMBlock, operation=PS_ASR42_ECS_BUCKLE_CONFIG.WritePRAMBlock
        EV_ASR42_RestoreBlockDefaults_ECS_BUCKLE_CONFIG: start-on-event=RE_ASR42_RestoreBlockDefaults, operation=PS_ASR42_ECS_BUCKLE_CONFIG.RestoreBlockDefaults
        EV_ASR42_RestorePRAMBlockDefaults_ECS_BUCKLE_CONFIG: start-on-event=RE_ASR42_RestorePRAMBlockDefaults, operation=PS_ASR42_ECS_BUCKLE_CONFIG.RestorePRAMBlockDefaults
        EV_ASR42_EraseBlock_ECS_BUCKLE_CONFIG: start-on-event=RE_ASR42_EraseBlock, operation=PS_ASR42_ECS_BUCKLE_CONFIG.EraseBlock
        EV_ASR42_InvalidateNvBlock_ECS_BUCKLE_CONFIG: start-on-event=RE_ASR42_InvalidateNvBlock, operation=PS_ASR42_ECS_BUCKLE_CONFIG.InvalidateNvBlock
        EV_ASR42_GetErrorStatus_ECS_CODING_VARIANT: start-on-event=RE_ASR42_GetErrorStatus, operation=PS_ASR42_ECS_CODING_VARIANT.GetErrorStatus
        EV_ASR42_SetDataIndex_ECS_CODING_VARIANT: start-on-event=RE_ASR42_SetDataIndex, operation=PS_ASR42_ECS_CODING_VARIANT.SetDataIndex
        EV_ASR42_GetDataIndex_ECS_CODING_VARIANT: start-on-event=RE_ASR42_GetDataIndex, operation=PS_ASR42_ECS_CODING_VARIANT.GetDataIndex
        EV_ASR42_SetRamBlockStatus_ECS_CODING_VARIANT: start-on-event=RE_ASR42_SetRamBlockStatus, operation=PS_ASR42_ECS_CODING_VARIANT.SetRamBlockStatus
        EV_ASR42_ReadBlock_ECS_CODING_VARIANT: start-on-event=RE_ASR42_ReadBlock, operation=PS_ASR42_ECS_CODING_VARIANT.ReadBlock
        EV_ASR42_ReadPRAMBlock_ECS_CODING_VARIANT: start-on-event=RE_ASR42_ReadPRAMBlock, operation=PS_ASR42_ECS_CODING_VARIANT.ReadPRAMBlock
        EV_ASR42_WriteBlock_ECS_CODING_VARIANT: start-on-event=RE_ASR42_WriteBlock, operation=PS_ASR42_ECS_CODING_VARIANT.WriteBlock
        EV_ASR42_WritePRAMBlock_ECS_CODING_VARIANT: start-on-event=RE_ASR42_WritePRAMBlock, operation=PS_ASR42_ECS_CODING_VARIANT.WritePRAMBlock
        EV_ASR42_RestoreBlockDefaults_ECS_CODING_VARIANT: start-on-event=RE_ASR42_RestoreBlockDefaults, operation=PS_ASR42_ECS_CODING_VARIANT.RestoreBlockDefaults
        EV_ASR42_RestorePRAMBlockDefaults_ECS_CODING_VARIANT: start-on-event=RE_ASR42_RestorePRAMBlockDefaults, operation=PS_ASR42_ECS_CODING_VARIANT.RestorePRAMBlockDefaults
        EV_ASR42_EraseBlock_ECS_CODING_VARIANT: start-on-event=RE_ASR42_EraseBlock, operation=PS_ASR42_ECS_CODING_VARIANT.EraseBlock
        EV_ASR42_InvalidateNvBlock_ECS_CODING_VARIANT: start-on-event=RE_ASR42_InvalidateNvBlock, operation=PS_ASR42_ECS_CODING_VARIANT.InvalidateNvBlock
        EV_ASR42_GetErrorStatus_ECS_ACC_LOWPASS: start-on-event=RE_ASR42_GetErrorStatus, operation=PS_ASR42_ECS_ACC_LOWPASS.GetErrorStatus
        EV_ASR42_SetDataIndex_ECS_ACC_LOWPASS: start-on-event=RE_ASR42_SetDataIndex, operation=PS_ASR42_ECS_ACC_LOWPASS.SetDataIndex
        EV_ASR42_GetDataIndex_ECS_ACC_LOWPASS: start-on-event=RE_ASR42_GetDataIndex, operation=PS_ASR42_ECS_ACC_LOWPASS.GetDataIndex
        EV_ASR42_SetRamBlockStatus_ECS_ACC_LOWPASS: start-on-event=RE_ASR42_SetRamBlockStatus, operation=PS_ASR42_ECS_ACC_LOWPASS.SetRamBlockStatus
        EV_ASR42_ReadBlock_ECS_ACC_LOWPASS: start-on-event=RE_ASR42_ReadBlock, operation=PS_ASR42_ECS_ACC_LOWPASS.ReadBlock
        EV_ASR42_ReadPRAMBlock_ECS_ACC_LOWPASS: start-on-event=RE_ASR42_ReadPRAMBlock, operation=PS_ASR42_ECS_ACC_LOWPASS.ReadPRAMBlock
        EV_ASR42_WriteBlock_ECS_ACC_LOWPASS: start-on-event=RE_ASR42_WriteBlock, operation=PS_ASR42_ECS_ACC_LOWPASS.WriteBlock
        EV_ASR42_WritePRAMBlock_ECS_ACC_LOWPASS: start-on-event=RE_ASR42_WritePRAMBlock, operation=PS_ASR42_ECS_ACC_LOWPASS.WritePRAMBlock
        EV_ASR42_RestoreBlockDefaults_ECS_ACC_LOWPASS: start-on-event=RE_ASR42_RestoreBlockDefaults, operation=PS_ASR42_ECS_ACC_LOWPASS.RestoreBlockDefaults
        EV_ASR42_RestorePRAMBlockDefaults_ECS_ACC_LOWPASS: start-on-event=RE_ASR42_RestorePRAMBlockDefaults, operation=PS_ASR42_ECS_ACC_LOWPASS.RestorePRAMBlockDefaults
        EV_ASR42_EraseBlock_ECS_ACC_LOWPASS: start-on-event=RE_ASR42_EraseBlock, operation=PS_ASR42_ECS_ACC_LOWPASS.EraseBlock
        EV_ASR42_InvalidateNvBlock_ECS_ACC_LOWPASS: start-on-event=RE_ASR42_InvalidateNvBlock, operation=PS_ASR42_ECS_ACC_LOWPASS.InvalidateNvBlock
        EV_ASR42_GetErrorStatus_SBS_LAST_STATE: start-on-event=RE_ASR42_GetErrorStatus, operation=PS_ASR42_SBS_LAST_STATE.GetErrorStatus
        EV_ASR42_SetDataIndex_SBS_LAST_STATE: start-on-event=RE_ASR42_SetDataIndex, operation=PS_ASR42_SBS_LAST_STATE.SetDataIndex
        EV_ASR42_GetDataIndex_SBS_LAST_STATE: start-on-event=RE_ASR42_GetDataIndex, operation=PS_ASR42_SBS_LAST_STATE.GetDataIndex
        EV_ASR42_SetRamBlockStatus_SBS_LAST_STATE: start-on-event=RE_ASR42_SetRamBlockStatus, operation=PS_ASR42_SBS_LAST_STATE.SetRamBlockStatus
        EV_ASR42_ReadBlock_SBS_LAST_STATE: start-on-event=RE_ASR42_ReadBlock, operation=PS_ASR42_SBS_LAST_STATE.ReadBlock
        EV_ASR42_ReadPRAMBlock_SBS_LAST_STATE: start-on-event=RE_ASR42_ReadPRAMBlock, operation=PS_ASR42_SBS_LAST_STATE.ReadPRAMBlock
        EV_ASR42_WriteBlock_SBS_LAST_STATE: start-on-event=RE_ASR42_WriteBlock, operation=PS_ASR42_SBS_LAST_STATE.WriteBlock
        EV_ASR42_WritePRAMBlock_SBS_LAST_STATE: start-on-event=RE_ASR42_WritePRAMBlock, operation=PS_ASR42_SBS_LAST_STATE.WritePRAMBlock
        EV_ASR42_RestoreBlockDefaults_SBS_LAST_STATE: start-on-event=RE_ASR42_RestoreBlockDefaults, operation=PS_ASR42_SBS_LAST_STATE.RestoreBlockDefaults
        EV_ASR42_RestorePRAMBlockDefaults_SBS_LAST_STATE: start-on-event=RE_ASR42_RestorePRAMBlockDefaults, operation=PS_ASR42_SBS_LAST_STATE.RestorePRAMBlockDefaults
        EV_ASR42_EraseBlock_SBS_LAST_STATE: start-on-event=RE_ASR42_EraseBlock, operation=PS_ASR42_SBS_LAST_STATE.EraseBlock
        EV_ASR42_InvalidateNvBlock_SBS_LAST_STATE: start-on-event=RE_ASR42_InvalidateNvBlock, operation=PS_ASR42_SBS_LAST_STATE.InvalidateNvBlock
        EV_ASR42_GetErrorStatus_ECS_ALGO_OUTPUT_DELAY: start-on-event=RE_ASR42_GetErrorStatus, operation=PS_ASR42_ECS_ALGO_OUTPUT_DELAY.GetErrorStatus
        EV_ASR42_SetDataIndex_ECS_ALGO_OUTPUT_DELAY: start-on-event=RE_ASR42_SetDataIndex, operation=PS_ASR42_ECS_ALGO_OUTPUT_DELAY.SetDataIndex
        EV_ASR42_GetDataIndex_ECS_ALGO_OUTPUT_DELAY: start-on-event=RE_ASR42_GetDataIndex, operation=PS_ASR42_ECS_ALGO_OUTPUT_DELAY.GetDataIndex
        EV_ASR42_SetRamBlockStatus_ECS_ALGO_OUTPUT_DELAY: start-on-event=RE_ASR42_SetRamBlockStatus, operation=PS_ASR42_ECS_ALGO_OUTPUT_DELAY.SetRamBlockStatus
        EV_ASR42_ReadBlock_ECS_ALGO_OUTPUT_DELAY: start-on-event=RE_ASR42_ReadBlock, operation=PS_ASR42_ECS_ALGO_OUTPUT_DELAY.ReadBlock
        EV_ASR42_ReadPRAMBlock_ECS_ALGO_OUTPUT_DELAY: start-on-event=RE_ASR42_ReadPRAMBlock, operation=PS_ASR42_ECS_ALGO_OUTPUT_DELAY.ReadPRAMBlock
        EV_ASR42_WriteBlock_ECS_ALGO_OUTPUT_DELAY: start-on-event=RE_ASR42_WriteBlock, operation=PS_ASR42_ECS_ALGO_OUTPUT_DELAY.WriteBlock
        EV_ASR42_WritePRAMBlock_ECS_ALGO_OUTPUT_DELAY: start-on-event=RE_ASR42_WritePRAMBlock, operation=PS_ASR42_ECS_ALGO_OUTPUT_DELAY.WritePRAMBlock
        EV_ASR42_RestoreBlockDefaults_ECS_ALGO_OUTPUT_DELAY: start-on-event=RE_ASR42_RestoreBlockDefaults, operation=PS_ASR42_ECS_ALGO_OUTPUT_DELAY.RestoreBlockDefaults
        EV_ASR42_RestorePRAMBlockDefaults_ECS_ALGO_OUTPUT_DELAY: start-on-event=RE_ASR42_RestorePRAMBlockDefaults, operation=PS_ASR42_ECS_ALGO_OUTPUT_DELAY.RestorePRAMBlockDefaults
        EV_ASR42_EraseBlock_ECS_ALGO_OUTPUT_DELAY: start-on-event=RE_ASR42_EraseBlock, operation=PS_ASR42_ECS_ALGO_OUTPUT_DELAY.EraseBlock
        EV_ASR42_InvalidateNvBlock_ECS_ALGO_OUTPUT_DELAY: start-on-event=RE_ASR42_InvalidateNvBlock, operation=PS_ASR42_ECS_ALGO_OUTPUT_DELAY.InvalidateNvBlock
        EV_ASR42_GetErrorStatus_ECS_SENSITIVITY_LUT: start-on-event=RE_ASR42_GetErrorStatus, operation=PS_ASR42_ECS_SENSITIVITY_LUT.GetErrorStatus
        EV_ASR42_SetDataIndex_ECS_SENSITIVITY_LUT: start-on-event=RE_ASR42_SetDataIndex, operation=PS_ASR42_ECS_SENSITIVITY_LUT.SetDataIndex
        EV_ASR42_GetDataIndex_ECS_SENSITIVITY_LUT: start-on-event=RE_ASR42_GetDataIndex, operation=PS_ASR42_ECS_SENSITIVITY_LUT.GetDataIndex
        EV_ASR42_SetRamBlockStatus_ECS_SENSITIVITY_LUT: start-on-event=RE_ASR42_SetRamBlockStatus, operation=PS_ASR42_ECS_SENSITIVITY_LUT.SetRamBlockStatus
        EV_ASR42_ReadBlock_ECS_SENSITIVITY_LUT: start-on-event=RE_ASR42_ReadBlock, operation=PS_ASR42_ECS_SENSITIVITY_LUT.ReadBlock
        EV_ASR42_ReadPRAMBlock_ECS_SENSITIVITY_LUT: start-on-event=RE_ASR42_ReadPRAMBlock, operation=PS_ASR42_ECS_SENSITIVITY_LUT.ReadPRAMBlock
        EV_ASR42_WriteBlock_ECS_SENSITIVITY_LUT: start-on-event=RE_ASR42_WriteBlock, operation=PS_ASR42_ECS_SENSITIVITY_LUT.WriteBlock
        EV_ASR42_WritePRAMBlock_ECS_SENSITIVITY_LUT: start-on-event=RE_ASR42_WritePRAMBlock, operation=PS_ASR42_ECS_SENSITIVITY_LUT.WritePRAMBlock
        EV_ASR42_RestoreBlockDefaults_ECS_SENSITIVITY_LUT: start-on-event=RE_ASR42_RestoreBlockDefaults, operation=PS_ASR42_ECS_SENSITIVITY_LUT.RestoreBlockDefaults
        EV_ASR42_RestorePRAMBlockDefaults_ECS_SENSITIVITY_LUT: start-on-event=RE_ASR42_RestorePRAMBlockDefaults, operation=PS_ASR42_ECS_SENSITIVITY_LUT.RestorePRAMBlockDefaults
        EV_ASR42_EraseBlock_ECS_SENSITIVITY_LUT: start-on-event=RE_ASR42_EraseBlock, operation=PS_ASR42_ECS_SENSITIVITY_LUT.EraseBlock
        EV_ASR42_InvalidateNvBlock_ECS_SENSITIVITY_LUT: start-on-event=RE_ASR42_InvalidateNvBlock, operation=PS_ASR42_ECS_SENSITIVITY_LUT.InvalidateNvBlock
        EV_ASR42_GetErrorStatus_ECS_SENSITIVITY_OPT: start-on-event=RE_ASR42_GetErrorStatus, operation=PS_ASR42_ECS_SENSITIVITY_OPT.GetErrorStatus
        EV_ASR42_SetDataIndex_ECS_SENSITIVITY_OPT: start-on-event=RE_ASR42_SetDataIndex, operation=PS_ASR42_ECS_SENSITIVITY_OPT.SetDataIndex
        EV_ASR42_GetDataIndex_ECS_SENSITIVITY_OPT: start-on-event=RE_ASR42_GetDataIndex, operation=PS_ASR42_ECS_SENSITIVITY_OPT.GetDataIndex
        EV_ASR42_SetRamBlockStatus_ECS_SENSITIVITY_OPT: start-on-event=RE_ASR42_SetRamBlockStatus, operation=PS_ASR42_ECS_SENSITIVITY_OPT.SetRamBlockStatus
        EV_ASR42_ReadBlock_ECS_SENSITIVITY_OPT: start-on-event=RE_ASR42_ReadBlock, operation=PS_ASR42_ECS_SENSITIVITY_OPT.ReadBlock
        EV_ASR42_ReadPRAMBlock_ECS_SENSITIVITY_OPT: start-on-event=RE_ASR42_ReadPRAMBlock, operation=PS_ASR42_ECS_SENSITIVITY_OPT.ReadPRAMBlock
        EV_ASR42_WriteBlock_ECS_SENSITIVITY_OPT: start-on-event=RE_ASR42_WriteBlock, operation=PS_ASR42_ECS_SENSITIVITY_OPT.WriteBlock
        EV_ASR42_WritePRAMBlock_ECS_SENSITIVITY_OPT: start-on-event=RE_ASR42_WritePRAMBlock, operation=PS_ASR42_ECS_SENSITIVITY_OPT.WritePRAMBlock
        EV_ASR42_RestoreBlockDefaults_ECS_SENSITIVITY_OPT: start-on-event=RE_ASR42_RestoreBlockDefaults, operation=PS_ASR42_ECS_SENSITIVITY_OPT.RestoreBlockDefaults
        EV_ASR42_RestorePRAMBlockDefaults_ECS_SENSITIVITY_OPT: start-on-event=RE_ASR42_RestorePRAMBlockDefaults, operation=PS_ASR42_ECS_SENSITIVITY_OPT.RestorePRAMBlockDefaults
        EV_ASR42_EraseBlock_ECS_SENSITIVITY_OPT: start-on-event=RE_ASR42_EraseBlock, operation=PS_ASR42_ECS_SENSITIVITY_OPT.EraseBlock
        EV_ASR42_InvalidateNvBlock_ECS_SENSITIVITY_OPT: start-on-event=RE_ASR42_InvalidateNvBlock, operation=PS_ASR42_ECS_SENSITIVITY_OPT.InvalidateNvBlock
        EV_ASR42_GetErrorStatus_ECU_TEMP_CALIBRATION: start-on-event=RE_ASR42_GetErrorStatus, operation=PS_ASR42_ECU_TEMP_CALIBRATION.GetErrorStatus
        EV_ASR42_SetDataIndex_ECU_TEMP_CALIBRATION: start-on-event=RE_ASR42_SetDataIndex, operation=PS_ASR42_ECU_TEMP_CALIBRATION.SetDataIndex
        EV_ASR42_GetDataIndex_ECU_TEMP_CALIBRATION: start-on-event=RE_ASR42_GetDataIndex, operation=PS_ASR42_ECU_TEMP_CALIBRATION.GetDataIndex
        EV_ASR42_SetRamBlockStatus_ECU_TEMP_CALIBRATION: start-on-event=RE_ASR42_SetRamBlockStatus, operation=PS_ASR42_ECU_TEMP_CALIBRATION.SetRamBlockStatus
        EV_ASR42_ReadBlock_ECU_TEMP_CALIBRATION: start-on-event=RE_ASR42_ReadBlock, operation=PS_ASR42_ECU_TEMP_CALIBRATION.ReadBlock
        EV_ASR42_ReadPRAMBlock_ECU_TEMP_CALIBRATION: start-on-event=RE_ASR42_ReadPRAMBlock, operation=PS_ASR42_ECU_TEMP_CALIBRATION.ReadPRAMBlock
        EV_ASR42_WriteBlock_ECU_TEMP_CALIBRATION: start-on-event=RE_ASR42_WriteBlock, operation=PS_ASR42_ECU_TEMP_CALIBRATION.WriteBlock
        EV_ASR42_WritePRAMBlock_ECU_TEMP_CALIBRATION: start-on-event=RE_ASR42_WritePRAMBlock, operation=PS_ASR42_ECU_TEMP_CALIBRATION.WritePRAMBlock
        EV_ASR42_RestoreBlockDefaults_ECU_TEMP_CALIBRATION: start-on-event=RE_ASR42_RestoreBlockDefaults, operation=PS_ASR42_ECU_TEMP_CALIBRATION.RestoreBlockDefaults
        EV_ASR42_RestorePRAMBlockDefaults_ECU_TEMP_CALIBRATION: start-on-event=RE_ASR42_RestorePRAMBlockDefaults, operation=PS_ASR42_ECU_TEMP_CALIBRATION.RestorePRAMBlockDefaults
        EV_ASR42_EraseBlock_ECU_TEMP_CALIBRATION: start-on-event=RE_ASR42_EraseBlock, operation=PS_ASR42_ECU_TEMP_CALIBRATION.EraseBlock
        EV_ASR42_InvalidateNvBlock_ECU_TEMP_CALIBRATION: start-on-event=RE_ASR42_InvalidateNvBlock, operation=PS_ASR42_ECU_TEMP_CALIBRATION.InvalidateNvBlock
        EV_ASR42_GetErrorStatus_ALV_NVM_VERSION: start-on-event=RE_ASR42_GetErrorStatus, operation=PS_ASR42_ALV_NVM_VERSION.GetErrorStatus
        EV_ASR42_SetDataIndex_ALV_NVM_VERSION: start-on-event=RE_ASR42_SetDataIndex, operation=PS_ASR42_ALV_NVM_VERSION.SetDataIndex
        EV_ASR42_GetDataIndex_ALV_NVM_VERSION: start-on-event=RE_ASR42_GetDataIndex, operation=PS_ASR42_ALV_NVM_VERSION.GetDataIndex
        EV_ASR42_SetRamBlockStatus_ALV_NVM_VERSION: start-on-event=RE_ASR42_SetRamBlockStatus, operation=PS_ASR42_ALV_NVM_VERSION.SetRamBlockStatus
        EV_ASR42_ReadBlock_ALV_NVM_VERSION: start-on-event=RE_ASR42_ReadBlock, operation=PS_ASR42_ALV_NVM_VERSION.ReadBlock
        EV_ASR42_ReadPRAMBlock_ALV_NVM_VERSION: start-on-event=RE_ASR42_ReadPRAMBlock, operation=PS_ASR42_ALV_NVM_VERSION.ReadPRAMBlock
        EV_ASR42_WriteBlock_ALV_NVM_VERSION: start-on-event=RE_ASR42_WriteBlock, operation=PS_ASR42_ALV_NVM_VERSION.WriteBlock
        EV_ASR42_WritePRAMBlock_ALV_NVM_VERSION: start-on-event=RE_ASR42_WritePRAMBlock, operation=PS_ASR42_ALV_NVM_VERSION.WritePRAMBlock
        EV_ASR42_RestoreBlockDefaults_ALV_NVM_VERSION: start-on-event=RE_ASR42_RestoreBlockDefaults, operation=PS_ASR42_ALV_NVM_VERSION.RestoreBlockDefaults
        EV_ASR42_RestorePRAMBlockDefaults_ALV_NVM_VERSION: start-on-event=RE_ASR42_RestorePRAMBlockDefaults, operation=PS_ASR42_ALV_NVM_VERSION.RestorePRAMBlockDefaults
        EV_ASR42_EraseBlock_ALV_NVM_VERSION: start-on-event=RE_ASR42_EraseBlock, operation=PS_ASR42_ALV_NVM_VERSION.EraseBlock
        EV_ASR42_InvalidateNvBlock_ALV_NVM_VERSION: start-on-event=RE_ASR42_InvalidateNvBlock, operation=PS_ASR42_ALV_NVM_VERSION.InvalidateNvBlock
        EV_ASR42_GetErrorStatus_MEAS_FRAME_RAM_ADDR_CFG: start-on-event=RE_ASR42_GetErrorStatus, operation=PS_ASR42_MEAS_FRAME_RAM_ADDR_CFG.GetErrorStatus
        EV_ASR42_SetDataIndex_MEAS_FRAME_RAM_ADDR_CFG: start-on-event=RE_ASR42_SetDataIndex, operation=PS_ASR42_MEAS_FRAME_RAM_ADDR_CFG.SetDataIndex
        EV_ASR42_GetDataIndex_MEAS_FRAME_RAM_ADDR_CFG: start-on-event=RE_ASR42_GetDataIndex, operation=PS_ASR42_MEAS_FRAME_RAM_ADDR_CFG.GetDataIndex
        EV_ASR42_SetRamBlockStatus_MEAS_FRAME_RAM_ADDR_CFG: start-on-event=RE_ASR42_SetRamBlockStatus, operation=PS_ASR42_MEAS_FRAME_RAM_ADDR_CFG.SetRamBlockStatus
        EV_ASR42_ReadBlock_MEAS_FRAME_RAM_ADDR_CFG: start-on-event=RE_ASR42_ReadBlock, operation=PS_ASR42_MEAS_FRAME_RAM_ADDR_CFG.ReadBlock
        EV_ASR42_ReadPRAMBlock_MEAS_FRAME_RAM_ADDR_CFG: start-on-event=RE_ASR42_ReadPRAMBlock, operation=PS_ASR42_MEAS_FRAME_RAM_ADDR_CFG.ReadPRAMBlock
        EV_ASR42_WriteBlock_MEAS_FRAME_RAM_ADDR_CFG: start-on-event=RE_ASR42_WriteBlock, operation=PS_ASR42_MEAS_FRAME_RAM_ADDR_CFG.WriteBlock
        EV_ASR42_WritePRAMBlock_MEAS_FRAME_RAM_ADDR_CFG: start-on-event=RE_ASR42_WritePRAMBlock, operation=PS_ASR42_MEAS_FRAME_RAM_ADDR_CFG.WritePRAMBlock
        EV_ASR42_RestoreBlockDefaults_MEAS_FRAME_RAM_ADDR_CFG: start-on-event=RE_ASR42_RestoreBlockDefaults, operation=PS_ASR42_MEAS_FRAME_RAM_ADDR_CFG.RestoreBlockDefaults
        EV_ASR42_RestorePRAMBlockDefaults_MEAS_FRAME_RAM_ADDR_CFG: start-on-event=RE_ASR42_RestorePRAMBlockDefaults, operation=PS_ASR42_MEAS_FRAME_RAM_ADDR_CFG.RestorePRAMBlockDefaults
        EV_ASR42_EraseBlock_MEAS_FRAME_RAM_ADDR_CFG: start-on-event=RE_ASR42_EraseBlock, operation=PS_ASR42_MEAS_FRAME_RAM_ADDR_CFG.EraseBlock
        EV_ASR42_InvalidateNvBlock_MEAS_FRAME_RAM_ADDR_CFG: start-on-event=RE_ASR42_InvalidateNvBlock, operation=PS_ASR42_MEAS_FRAME_RAM_ADDR_CFG.InvalidateNvBlock
        EV_ASR42_GetErrorStatus_ACC_AXIS_ANGLE_CALIBRATION: start-on-event=RE_ASR42_GetErrorStatus, operation=PS_ASR42_ACC_AXIS_ANGLE_CALIBRATION.GetErrorStatus
        EV_ASR42_SetDataIndex_ACC_AXIS_ANGLE_CALIBRATION: start-on-event=RE_ASR42_SetDataIndex, operation=PS_ASR42_ACC_AXIS_ANGLE_CALIBRATION.SetDataIndex
        EV_ASR42_GetDataIndex_ACC_AXIS_ANGLE_CALIBRATION: start-on-event=RE_ASR42_GetDataIndex, operation=PS_ASR42_ACC_AXIS_ANGLE_CALIBRATION.GetDataIndex
        EV_ASR42_SetRamBlockStatus_ACC_AXIS_ANGLE_CALIBRATION: start-on-event=RE_ASR42_SetRamBlockStatus, operation=PS_ASR42_ACC_AXIS_ANGLE_CALIBRATION.SetRamBlockStatus
        EV_ASR42_ReadBlock_ACC_AXIS_ANGLE_CALIBRATION: start-on-event=RE_ASR42_ReadBlock, operation=PS_ASR42_ACC_AXIS_ANGLE_CALIBRATION.ReadBlock
        EV_ASR42_ReadPRAMBlock_ACC_AXIS_ANGLE_CALIBRATION: start-on-event=RE_ASR42_ReadPRAMBlock, operation=PS_ASR42_ACC_AXIS_ANGLE_CALIBRATION.ReadPRAMBlock
        EV_ASR42_WriteBlock_ACC_AXIS_ANGLE_CALIBRATION: start-on-event=RE_ASR42_WriteBlock, operation=PS_ASR42_ACC_AXIS_ANGLE_CALIBRATION.WriteBlock
        EV_ASR42_WritePRAMBlock_ACC_AXIS_ANGLE_CALIBRATION: start-on-event=RE_ASR42_WritePRAMBlock, operation=PS_ASR42_ACC_AXIS_ANGLE_CALIBRATION.WritePRAMBlock
        EV_ASR42_RestoreBlockDefaults_ACC_AXIS_ANGLE_CALIBRATION: start-on-event=RE_ASR42_RestoreBlockDefaults, operation=PS_ASR42_ACC_AXIS_ANGLE_CALIBRATION.RestoreBlockDefaults
        EV_ASR42_RestorePRAMBlockDefaults_ACC_AXIS_ANGLE_CALIBRATION: start-on-event=RE_ASR42_RestorePRAMBlockDefaults, operation=PS_ASR42_ACC_AXIS_ANGLE_CALIBRATION.RestorePRAMBlockDefaults
        EV_ASR42_EraseBlock_ACC_AXIS_ANGLE_CALIBRATION: start-on-event=RE_ASR42_EraseBlock, operation=PS_ASR42_ACC_AXIS_ANGLE_CALIBRATION.EraseBlock
        EV_ASR42_InvalidateNvBlock_ACC_AXIS_ANGLE_CALIBRATION: start-on-event=RE_ASR42_InvalidateNvBlock, operation=PS_ASR42_ACC_AXIS_ANGLE_CALIBRATION.InvalidateNvBlock
        EV_ASR42_GetErrorStatus_EOL_COUNTERS: start-on-event=RE_ASR42_GetErrorStatus, operation=PS_ASR42_EOL_COUNTERS.GetErrorStatus
        EV_ASR42_SetDataIndex_EOL_COUNTERS: start-on-event=RE_ASR42_SetDataIndex, operation=PS_ASR42_EOL_COUNTERS.SetDataIndex
        EV_ASR42_GetDataIndex_EOL_COUNTERS: start-on-event=RE_ASR42_GetDataIndex, operation=PS_ASR42_EOL_COUNTERS.GetDataIndex
        EV_ASR42_SetRamBlockStatus_EOL_COUNTERS: start-on-event=RE_ASR42_SetRamBlockStatus, operation=PS_ASR42_EOL_COUNTERS.SetRamBlockStatus
        EV_ASR42_ReadBlock_EOL_COUNTERS: start-on-event=RE_ASR42_ReadBlock, operation=PS_ASR42_EOL_COUNTERS.ReadBlock
        EV_ASR42_ReadPRAMBlock_EOL_COUNTERS: start-on-event=RE_ASR42_ReadPRAMBlock, operation=PS_ASR42_EOL_COUNTERS.ReadPRAMBlock
        EV_ASR42_WriteBlock_EOL_COUNTERS: start-on-event=RE_ASR42_WriteBlock, operation=PS_ASR42_EOL_COUNTERS.WriteBlock
        EV_ASR42_WritePRAMBlock_EOL_COUNTERS: start-on-event=RE_ASR42_WritePRAMBlock, operation=PS_ASR42_EOL_COUNTERS.WritePRAMBlock
        EV_ASR42_RestoreBlockDefaults_EOL_COUNTERS: start-on-event=RE_ASR42_RestoreBlockDefaults, operation=PS_ASR42_EOL_COUNTERS.RestoreBlockDefaults
        EV_ASR42_RestorePRAMBlockDefaults_EOL_COUNTERS: start-on-event=RE_ASR42_RestorePRAMBlockDefaults, operation=PS_ASR42_EOL_COUNTERS.RestorePRAMBlockDefaults
        EV_ASR42_EraseBlock_EOL_COUNTERS: start-on-event=RE_ASR42_EraseBlock, operation=PS_ASR42_EOL_COUNTERS.EraseBlock
        EV_ASR42_InvalidateNvBlock_EOL_COUNTERS: start-on-event=RE_ASR42_InvalidateNvBlock, operation=PS_ASR42_EOL_COUNTERS.InvalidateNvBlock
        EV_ASR42_GetErrorStatus_RESERVED_4: start-on-event=RE_ASR42_GetErrorStatus, operation=PS_ASR42_RESERVED_4.GetErrorStatus
        EV_ASR42_SetDataIndex_RESERVED_4: start-on-event=RE_ASR42_SetDataIndex, operation=PS_ASR42_RESERVED_4.SetDataIndex
        EV_ASR42_GetDataIndex_RESERVED_4: start-on-event=RE_ASR42_GetDataIndex, operation=PS_ASR42_RESERVED_4.GetDataIndex
        EV_ASR42_SetRamBlockStatus_RESERVED_4: start-on-event=RE_ASR42_SetRamBlockStatus, operation=PS_ASR42_RESERVED_4.SetRamBlockStatus
        EV_ASR42_ReadBlock_RESERVED_4: start-on-event=RE_ASR42_ReadBlock, operation=PS_ASR42_RESERVED_4.ReadBlock
        EV_ASR42_ReadPRAMBlock_RESERVED_4: start-on-event=RE_ASR42_ReadPRAMBlock, operation=PS_ASR42_RESERVED_4.ReadPRAMBlock
        EV_ASR42_WriteBlock_RESERVED_4: start-on-event=RE_ASR42_WriteBlock, operation=PS_ASR42_RESERVED_4.WriteBlock
        EV_ASR42_WritePRAMBlock_RESERVED_4: start-on-event=RE_ASR42_WritePRAMBlock, operation=PS_ASR42_RESERVED_4.WritePRAMBlock
        EV_ASR42_RestoreBlockDefaults_RESERVED_4: start-on-event=RE_ASR42_RestoreBlockDefaults, operation=PS_ASR42_RESERVED_4.RestoreBlockDefaults
        EV_ASR42_RestorePRAMBlockDefaults_RESERVED_4: start-on-event=RE_ASR42_RestorePRAMBlockDefaults, operation=PS_ASR42_RESERVED_4.RestorePRAMBlockDefaults
        EV_ASR42_EraseBlock_RESERVED_4: start-on-event=RE_ASR42_EraseBlock, operation=PS_ASR42_RESERVED_4.EraseBlock
        EV_ASR42_InvalidateNvBlock_RESERVED_4: start-on-event=RE_ASR42_InvalidateNvBlock, operation=PS_ASR42_RESERVED_4.InvalidateNvBlock
        EV_ASR42_GetErrorStatus_AUTOTEST_PARAM: start-on-event=RE_ASR42_GetErrorStatus, operation=PS_ASR42_AUTOTEST_PARAM.GetErrorStatus
        EV_ASR42_SetDataIndex_AUTOTEST_PARAM: start-on-event=RE_ASR42_SetDataIndex, operation=PS_ASR42_AUTOTEST_PARAM.SetDataIndex
        EV_ASR42_GetDataIndex_AUTOTEST_PARAM: start-on-event=RE_ASR42_GetDataIndex, operation=PS_ASR42_AUTOTEST_PARAM.GetDataIndex
        EV_ASR42_SetRamBlockStatus_AUTOTEST_PARAM: start-on-event=RE_ASR42_SetRamBlockStatus, operation=PS_ASR42_AUTOTEST_PARAM.SetRamBlockStatus
        EV_ASR42_ReadBlock_AUTOTEST_PARAM: start-on-event=RE_ASR42_ReadBlock, operation=PS_ASR42_AUTOTEST_PARAM.ReadBlock
        EV_ASR42_ReadPRAMBlock_AUTOTEST_PARAM: start-on-event=RE_ASR42_ReadPRAMBlock, operation=PS_ASR42_AUTOTEST_PARAM.ReadPRAMBlock
        EV_ASR42_WriteBlock_AUTOTEST_PARAM: start-on-event=RE_ASR42_WriteBlock, operation=PS_ASR42_AUTOTEST_PARAM.WriteBlock
        EV_ASR42_WritePRAMBlock_AUTOTEST_PARAM: start-on-event=RE_ASR42_WritePRAMBlock, operation=PS_ASR42_AUTOTEST_PARAM.WritePRAMBlock
        EV_ASR42_RestoreBlockDefaults_AUTOTEST_PARAM: start-on-event=RE_ASR42_RestoreBlockDefaults, operation=PS_ASR42_AUTOTEST_PARAM.RestoreBlockDefaults
        EV_ASR42_RestorePRAMBlockDefaults_AUTOTEST_PARAM: start-on-event=RE_ASR42_RestorePRAMBlockDefaults, operation=PS_ASR42_AUTOTEST_PARAM.RestorePRAMBlockDefaults
        EV_ASR42_EraseBlock_AUTOTEST_PARAM: start-on-event=RE_ASR42_EraseBlock, operation=PS_ASR42_AUTOTEST_PARAM.EraseBlock
        EV_ASR42_InvalidateNvBlock_AUTOTEST_PARAM: start-on-event=RE_ASR42_InvalidateNvBlock, operation=PS_ASR42_AUTOTEST_PARAM.InvalidateNvBlock
        EV_ASR42_GetErrorStatus_PHYS_MEASUREMENTS: start-on-event=RE_ASR42_GetErrorStatus, operation=PS_ASR42_PHYS_MEASUREMENTS.GetErrorStatus
        EV_ASR42_SetDataIndex_PHYS_MEASUREMENTS: start-on-event=RE_ASR42_SetDataIndex, operation=PS_ASR42_PHYS_MEASUREMENTS.SetDataIndex
        EV_ASR42_GetDataIndex_PHYS_MEASUREMENTS: start-on-event=RE_ASR42_GetDataIndex, operation=PS_ASR42_PHYS_MEASUREMENTS.GetDataIndex
        EV_ASR42_SetRamBlockStatus_PHYS_MEASUREMENTS: start-on-event=RE_ASR42_SetRamBlockStatus, operation=PS_ASR42_PHYS_MEASUREMENTS.SetRamBlockStatus
        EV_ASR42_ReadBlock_PHYS_MEASUREMENTS: start-on-event=RE_ASR42_ReadBlock, operation=PS_ASR42_PHYS_MEASUREMENTS.ReadBlock
        EV_ASR42_ReadPRAMBlock_PHYS_MEASUREMENTS: start-on-event=RE_ASR42_ReadPRAMBlock, operation=PS_ASR42_PHYS_MEASUREMENTS.ReadPRAMBlock
        EV_ASR42_WriteBlock_PHYS_MEASUREMENTS: start-on-event=RE_ASR42_WriteBlock, operation=PS_ASR42_PHYS_MEASUREMENTS.WriteBlock
        EV_ASR42_WritePRAMBlock_PHYS_MEASUREMENTS: start-on-event=RE_ASR42_WritePRAMBlock, operation=PS_ASR42_PHYS_MEASUREMENTS.WritePRAMBlock
        EV_ASR42_RestoreBlockDefaults_PHYS_MEASUREMENTS: start-on-event=RE_ASR42_RestoreBlockDefaults, operation=PS_ASR42_PHYS_MEASUREMENTS.RestoreBlockDefaults
        EV_ASR42_RestorePRAMBlockDefaults_PHYS_MEASUREMENTS: start-on-event=RE_ASR42_RestorePRAMBlockDefaults, operation=PS_ASR42_PHYS_MEASUREMENTS.RestorePRAMBlockDefaults
        EV_ASR42_EraseBlock_PHYS_MEASUREMENTS: start-on-event=RE_ASR42_EraseBlock, operation=PS_ASR42_PHYS_MEASUREMENTS.EraseBlock
        EV_ASR42_InvalidateNvBlock_PHYS_MEASUREMENTS: start-on-event=RE_ASR42_InvalidateNvBlock, operation=PS_ASR42_PHYS_MEASUREMENTS.InvalidateNvBlock
        EV_ASR42_GetErrorStatus_SOLENOID_PARAM: start-on-event=RE_ASR42_GetErrorStatus, operation=PS_ASR42_SOLENOID_PARAM.GetErrorStatus
        EV_ASR42_SetDataIndex_SOLENOID_PARAM: start-on-event=RE_ASR42_SetDataIndex, operation=PS_ASR42_SOLENOID_PARAM.SetDataIndex
        EV_ASR42_GetDataIndex_SOLENOID_PARAM: start-on-event=RE_ASR42_GetDataIndex, operation=PS_ASR42_SOLENOID_PARAM.GetDataIndex
        EV_ASR42_SetRamBlockStatus_SOLENOID_PARAM: start-on-event=RE_ASR42_SetRamBlockStatus, operation=PS_ASR42_SOLENOID_PARAM.SetRamBlockStatus
        EV_ASR42_ReadBlock_SOLENOID_PARAM: start-on-event=RE_ASR42_ReadBlock, operation=PS_ASR42_SOLENOID_PARAM.ReadBlock
        EV_ASR42_ReadPRAMBlock_SOLENOID_PARAM: start-on-event=RE_ASR42_ReadPRAMBlock, operation=PS_ASR42_SOLENOID_PARAM.ReadPRAMBlock
        EV_ASR42_WriteBlock_SOLENOID_PARAM: start-on-event=RE_ASR42_WriteBlock, operation=PS_ASR42_SOLENOID_PARAM.WriteBlock
        EV_ASR42_WritePRAMBlock_SOLENOID_PARAM: start-on-event=RE_ASR42_WritePRAMBlock, operation=PS_ASR42_SOLENOID_PARAM.WritePRAMBlock
        EV_ASR42_RestoreBlockDefaults_SOLENOID_PARAM: start-on-event=RE_ASR42_RestoreBlockDefaults, operation=PS_ASR42_SOLENOID_PARAM.RestoreBlockDefaults
        EV_ASR42_RestorePRAMBlockDefaults_SOLENOID_PARAM: start-on-event=RE_ASR42_RestorePRAMBlockDefaults, operation=PS_ASR42_SOLENOID_PARAM.RestorePRAMBlockDefaults
        EV_ASR42_EraseBlock_SOLENOID_PARAM: start-on-event=RE_ASR42_EraseBlock, operation=PS_ASR42_SOLENOID_PARAM.EraseBlock
        EV_ASR42_InvalidateNvBlock_SOLENOID_PARAM: start-on-event=RE_ASR42_InvalidateNvBlock, operation=PS_ASR42_SOLENOID_PARAM.InvalidateNvBlock
        EV_ASR42_GetErrorStatus_ECS_PROFILES: start-on-event=RE_ASR42_GetErrorStatus, operation=PS_ASR42_ECS_PROFILES.GetErrorStatus
        EV_ASR42_SetDataIndex_ECS_PROFILES: start-on-event=RE_ASR42_SetDataIndex, operation=PS_ASR42_ECS_PROFILES.SetDataIndex
        EV_ASR42_GetDataIndex_ECS_PROFILES: start-on-event=RE_ASR42_GetDataIndex, operation=PS_ASR42_ECS_PROFILES.GetDataIndex
        EV_ASR42_SetRamBlockStatus_ECS_PROFILES: start-on-event=RE_ASR42_SetRamBlockStatus, operation=PS_ASR42_ECS_PROFILES.SetRamBlockStatus
        EV_ASR42_ReadBlock_ECS_PROFILES: start-on-event=RE_ASR42_ReadBlock, operation=PS_ASR42_ECS_PROFILES.ReadBlock
        EV_ASR42_ReadPRAMBlock_ECS_PROFILES: start-on-event=RE_ASR42_ReadPRAMBlock, operation=PS_ASR42_ECS_PROFILES.ReadPRAMBlock
        EV_ASR42_WriteBlock_ECS_PROFILES: start-on-event=RE_ASR42_WriteBlock, operation=PS_ASR42_ECS_PROFILES.WriteBlock
        EV_ASR42_WritePRAMBlock_ECS_PROFILES: start-on-event=RE_ASR42_WritePRAMBlock, operation=PS_ASR42_ECS_PROFILES.WritePRAMBlock
        EV_ASR42_RestoreBlockDefaults_ECS_PROFILES: start-on-event=RE_ASR42_RestoreBlockDefaults, operation=PS_ASR42_ECS_PROFILES.RestoreBlockDefaults
        EV_ASR42_RestorePRAMBlockDefaults_ECS_PROFILES: start-on-event=RE_ASR42_RestorePRAMBlockDefaults, operation=PS_ASR42_ECS_PROFILES.RestorePRAMBlockDefaults
        EV_ASR42_EraseBlock_ECS_PROFILES: start-on-event=RE_ASR42_EraseBlock, operation=PS_ASR42_ECS_PROFILES.EraseBlock
        EV_ASR42_InvalidateNvBlock_ECS_PROFILES: start-on-event=RE_ASR42_InvalidateNvBlock, operation=PS_ASR42_ECS_PROFILES.InvalidateNvBlock
        EV_ASR42_GetErrorStatus_ECU_STATE_TIMING_PARAMETERS: start-on-event=RE_ASR42_GetErrorStatus, operation=PS_ASR42_ECU_STATE_TIMING_PARAMETERS.GetErrorStatus
        EV_ASR42_SetDataIndex_ECU_STATE_TIMING_PARAMETERS: start-on-event=RE_ASR42_SetDataIndex, operation=PS_ASR42_ECU_STATE_TIMING_PARAMETERS.SetDataIndex
        EV_ASR42_GetDataIndex_ECU_STATE_TIMING_PARAMETERS: start-on-event=RE_ASR42_GetDataIndex, operation=PS_ASR42_ECU_STATE_TIMING_PARAMETERS.GetDataIndex
        EV_ASR42_SetRamBlockStatus_ECU_STATE_TIMING_PARAMETERS: start-on-event=RE_ASR42_SetRamBlockStatus, operation=PS_ASR42_ECU_STATE_TIMING_PARAMETERS.SetRamBlockStatus
        EV_ASR42_ReadBlock_ECU_STATE_TIMING_PARAMETERS: start-on-event=RE_ASR42_ReadBlock, operation=PS_ASR42_ECU_STATE_TIMING_PARAMETERS.ReadBlock
        EV_ASR42_ReadPRAMBlock_ECU_STATE_TIMING_PARAMETERS: start-on-event=RE_ASR42_ReadPRAMBlock, operation=PS_ASR42_ECU_STATE_TIMING_PARAMETERS.ReadPRAMBlock
        EV_ASR42_WriteBlock_ECU_STATE_TIMING_PARAMETERS: start-on-event=RE_ASR42_WriteBlock, operation=PS_ASR42_ECU_STATE_TIMING_PARAMETERS.WriteBlock
        EV_ASR42_WritePRAMBlock_ECU_STATE_TIMING_PARAMETERS: start-on-event=RE_ASR42_WritePRAMBlock, operation=PS_ASR42_ECU_STATE_TIMING_PARAMETERS.WritePRAMBlock
        EV_ASR42_RestoreBlockDefaults_ECU_STATE_TIMING_PARAMETERS: start-on-event=RE_ASR42_RestoreBlockDefaults, operation=PS_ASR42_ECU_STATE_TIMING_PARAMETERS.RestoreBlockDefaults
        EV_ASR42_RestorePRAMBlockDefaults_ECU_STATE_TIMING_PARAMETERS: start-on-event=RE_ASR42_RestorePRAMBlockDefaults, operation=PS_ASR42_ECU_STATE_TIMING_PARAMETERS.RestorePRAMBlockDefaults
        EV_ASR42_EraseBlock_ECU_STATE_TIMING_PARAMETERS: start-on-event=RE_ASR42_EraseBlock, operation=PS_ASR42_ECU_STATE_TIMING_PARAMETERS.EraseBlock
        EV_ASR42_InvalidateNvBlock_ECU_STATE_TIMING_PARAMETERS: start-on-event=RE_ASR42_InvalidateNvBlock, operation=PS_ASR42_ECU_STATE_TIMING_PARAMETERS.InvalidateNvBlock
        EV_ASR42_GetErrorStatus_SPARE_PART_NUMBER: start-on-event=RE_ASR42_GetErrorStatus, operation=PS_ASR42_SPARE_PART_NUMBER.GetErrorStatus
        EV_ASR42_SetDataIndex_SPARE_PART_NUMBER: start-on-event=RE_ASR42_SetDataIndex, operation=PS_ASR42_SPARE_PART_NUMBER.SetDataIndex
        EV_ASR42_GetDataIndex_SPARE_PART_NUMBER: start-on-event=RE_ASR42_GetDataIndex, operation=PS_ASR42_SPARE_PART_NUMBER.GetDataIndex
        EV_ASR42_SetRamBlockStatus_SPARE_PART_NUMBER: start-on-event=RE_ASR42_SetRamBlockStatus, operation=PS_ASR42_SPARE_PART_NUMBER.SetRamBlockStatus
        EV_ASR42_ReadBlock_SPARE_PART_NUMBER: start-on-event=RE_ASR42_ReadBlock, operation=PS_ASR42_SPARE_PART_NUMBER.ReadBlock
        EV_ASR42_ReadPRAMBlock_SPARE_PART_NUMBER: start-on-event=RE_ASR42_ReadPRAMBlock, operation=PS_ASR42_SPARE_PART_NUMBER.ReadPRAMBlock
        EV_ASR42_WriteBlock_SPARE_PART_NUMBER: start-on-event=RE_ASR42_WriteBlock, operation=PS_ASR42_SPARE_PART_NUMBER.WriteBlock
        EV_ASR42_WritePRAMBlock_SPARE_PART_NUMBER: start-on-event=RE_ASR42_WritePRAMBlock, operation=PS_ASR42_SPARE_PART_NUMBER.WritePRAMBlock
        EV_ASR42_RestoreBlockDefaults_SPARE_PART_NUMBER: start-on-event=RE_ASR42_RestoreBlockDefaults, operation=PS_ASR42_SPARE_PART_NUMBER.RestoreBlockDefaults
        EV_ASR42_RestorePRAMBlockDefaults_SPARE_PART_NUMBER: start-on-event=RE_ASR42_RestorePRAMBlockDefaults, operation=PS_ASR42_SPARE_PART_NUMBER.RestorePRAMBlockDefaults
        EV_ASR42_EraseBlock_SPARE_PART_NUMBER: start-on-event=RE_ASR42_EraseBlock, operation=PS_ASR42_SPARE_PART_NUMBER.EraseBlock
        EV_ASR42_InvalidateNvBlock_SPARE_PART_NUMBER: start-on-event=RE_ASR42_InvalidateNvBlock, operation=PS_ASR42_SPARE_PART_NUMBER.InvalidateNvBlock
        EV_ASR42_GetErrorStatus_HARDWARE_NUMBER: start-on-event=RE_ASR42_GetErrorStatus, operation=PS_ASR42_HARDWARE_NUMBER.GetErrorStatus
        EV_ASR42_SetDataIndex_HARDWARE_NUMBER: start-on-event=RE_ASR42_SetDataIndex, operation=PS_ASR42_HARDWARE_NUMBER.SetDataIndex
        EV_ASR42_GetDataIndex_HARDWARE_NUMBER: start-on-event=RE_ASR42_GetDataIndex, operation=PS_ASR42_HARDWARE_NUMBER.GetDataIndex
        EV_ASR42_SetRamBlockStatus_HARDWARE_NUMBER: start-on-event=RE_ASR42_SetRamBlockStatus, operation=PS_ASR42_HARDWARE_NUMBER.SetRamBlockStatus
        EV_ASR42_ReadBlock_HARDWARE_NUMBER: start-on-event=RE_ASR42_ReadBlock, operation=PS_ASR42_HARDWARE_NUMBER.ReadBlock
        EV_ASR42_ReadPRAMBlock_HARDWARE_NUMBER: start-on-event=RE_ASR42_ReadPRAMBlock, operation=PS_ASR42_HARDWARE_NUMBER.ReadPRAMBlock
        EV_ASR42_WriteBlock_HARDWARE_NUMBER: start-on-event=RE_ASR42_WriteBlock, operation=PS_ASR42_HARDWARE_NUMBER.WriteBlock
        EV_ASR42_WritePRAMBlock_HARDWARE_NUMBER: start-on-event=RE_ASR42_WritePRAMBlock, operation=PS_ASR42_HARDWARE_NUMBER.WritePRAMBlock
        EV_ASR42_RestoreBlockDefaults_HARDWARE_NUMBER: start-on-event=RE_ASR42_RestoreBlockDefaults, operation=PS_ASR42_HARDWARE_NUMBER.RestoreBlockDefaults
        EV_ASR42_RestorePRAMBlockDefaults_HARDWARE_NUMBER: start-on-event=RE_ASR42_RestorePRAMBlockDefaults, operation=PS_ASR42_HARDWARE_NUMBER.RestorePRAMBlockDefaults
        EV_ASR42_EraseBlock_HARDWARE_NUMBER: start-on-event=RE_ASR42_EraseBlock, operation=PS_ASR42_HARDWARE_NUMBER.EraseBlock
        EV_ASR42_InvalidateNvBlock_HARDWARE_NUMBER: start-on-event=RE_ASR42_InvalidateNvBlock, operation=PS_ASR42_HARDWARE_NUMBER.InvalidateNvBlock
        EV_ASR42_GetErrorStatus_SYSTEM_NAME_OR_ENGINE_TYPE: start-on-event=RE_ASR42_GetErrorStatus, operation=PS_ASR42_SYSTEM_NAME_OR_ENGINE_TYPE.GetErrorStatus
        EV_ASR42_SetDataIndex_SYSTEM_NAME_OR_ENGINE_TYPE: start-on-event=RE_ASR42_SetDataIndex, operation=PS_ASR42_SYSTEM_NAME_OR_ENGINE_TYPE.SetDataIndex
        EV_ASR42_GetDataIndex_SYSTEM_NAME_OR_ENGINE_TYPE: start-on-event=RE_ASR42_GetDataIndex, operation=PS_ASR42_SYSTEM_NAME_OR_ENGINE_TYPE.GetDataIndex
        EV_ASR42_SetRamBlockStatus_SYSTEM_NAME_OR_ENGINE_TYPE: start-on-event=RE_ASR42_SetRamBlockStatus, operation=PS_ASR42_SYSTEM_NAME_OR_ENGINE_TYPE.SetRamBlockStatus
        EV_ASR42_ReadBlock_SYSTEM_NAME_OR_ENGINE_TYPE: start-on-event=RE_ASR42_ReadBlock, operation=PS_ASR42_SYSTEM_NAME_OR_ENGINE_TYPE.ReadBlock
        EV_ASR42_ReadPRAMBlock_SYSTEM_NAME_OR_ENGINE_TYPE: start-on-event=RE_ASR42_ReadPRAMBlock, operation=PS_ASR42_SYSTEM_NAME_OR_ENGINE_TYPE.ReadPRAMBlock
        EV_ASR42_WriteBlock_SYSTEM_NAME_OR_ENGINE_TYPE: start-on-event=RE_ASR42_WriteBlock, operation=PS_ASR42_SYSTEM_NAME_OR_ENGINE_TYPE.WriteBlock
        EV_ASR42_WritePRAMBlock_SYSTEM_NAME_OR_ENGINE_TYPE: start-on-event=RE_ASR42_WritePRAMBlock, operation=PS_ASR42_SYSTEM_NAME_OR_ENGINE_TYPE.WritePRAMBlock
        EV_ASR42_RestoreBlockDefaults_SYSTEM_NAME_OR_ENGINE_TYPE: start-on-event=RE_ASR42_RestoreBlockDefaults, operation=PS_ASR42_SYSTEM_NAME_OR_ENGINE_TYPE.RestoreBlockDefaults
        EV_ASR42_RestorePRAMBlockDefaults_SYSTEM_NAME_OR_ENGINE_TYPE: start-on-event=RE_ASR42_RestorePRAMBlockDefaults, operation=PS_ASR42_SYSTEM_NAME_OR_ENGINE_TYPE.RestorePRAMBlockDefaults
        EV_ASR42_EraseBlock_SYSTEM_NAME_OR_ENGINE_TYPE: start-on-event=RE_ASR42_EraseBlock, operation=PS_ASR42_SYSTEM_NAME_OR_ENGINE_TYPE.EraseBlock
        EV_ASR42_InvalidateNvBlock_SYSTEM_NAME_OR_ENGINE_TYPE: start-on-event=RE_ASR42_InvalidateNvBlock, operation=PS_ASR42_SYSTEM_NAME_OR_ENGINE_TYPE.InvalidateNvBlock
        EV_ASR42_GetErrorStatus_BLOCK_FBL: start-on-event=RE_ASR42_GetErrorStatus, operation=PS_ASR42_BLOCK_FBL.GetErrorStatus
        EV_ASR42_SetDataIndex_BLOCK_FBL: start-on-event=RE_ASR42_SetDataIndex, operation=PS_ASR42_BLOCK_FBL.SetDataIndex
        EV_ASR42_GetDataIndex_BLOCK_FBL: start-on-event=RE_ASR42_GetDataIndex, operation=PS_ASR42_BLOCK_FBL.GetDataIndex
        EV_ASR42_SetRamBlockStatus_BLOCK_FBL: start-on-event=RE_ASR42_SetRamBlockStatus, operation=PS_ASR42_BLOCK_FBL.SetRamBlockStatus
        EV_ASR42_ReadBlock_BLOCK_FBL: start-on-event=RE_ASR42_ReadBlock, operation=PS_ASR42_BLOCK_FBL.ReadBlock
        EV_ASR42_ReadPRAMBlock_BLOCK_FBL: start-on-event=RE_ASR42_ReadPRAMBlock, operation=PS_ASR42_BLOCK_FBL.ReadPRAMBlock
        EV_ASR42_WriteBlock_BLOCK_FBL: start-on-event=RE_ASR42_WriteBlock, operation=PS_ASR42_BLOCK_FBL.WriteBlock
        EV_ASR42_WritePRAMBlock_BLOCK_FBL: start-on-event=RE_ASR42_WritePRAMBlock, operation=PS_ASR42_BLOCK_FBL.WritePRAMBlock
        EV_ASR42_RestoreBlockDefaults_BLOCK_FBL: start-on-event=RE_ASR42_RestoreBlockDefaults, operation=PS_ASR42_BLOCK_FBL.RestoreBlockDefaults
        EV_ASR42_RestorePRAMBlockDefaults_BLOCK_FBL: start-on-event=RE_ASR42_RestorePRAMBlockDefaults, operation=PS_ASR42_BLOCK_FBL.RestorePRAMBlockDefaults
        EV_ASR42_EraseBlock_BLOCK_FBL: start-on-event=RE_ASR42_EraseBlock, operation=PS_ASR42_BLOCK_FBL.EraseBlock
        EV_ASR42_InvalidateNvBlock_BLOCK_FBL: start-on-event=RE_ASR42_InvalidateNvBlock, operation=PS_ASR42_BLOCK_FBL.InvalidateNvBlock
        EV_ASR42_GetErrorStatus_ODX_FILE_IDENTIFIER: start-on-event=RE_ASR42_GetErrorStatus, operation=PS_ASR42_ODX_FILE_IDENTIFIER.GetErrorStatus
        EV_ASR42_SetDataIndex_ODX_FILE_IDENTIFIER: start-on-event=RE_ASR42_SetDataIndex, operation=PS_ASR42_ODX_FILE_IDENTIFIER.SetDataIndex
        EV_ASR42_GetDataIndex_ODX_FILE_IDENTIFIER: start-on-event=RE_ASR42_GetDataIndex, operation=PS_ASR42_ODX_FILE_IDENTIFIER.GetDataIndex
        EV_ASR42_SetRamBlockStatus_ODX_FILE_IDENTIFIER: start-on-event=RE_ASR42_SetRamBlockStatus, operation=PS_ASR42_ODX_FILE_IDENTIFIER.SetRamBlockStatus
        EV_ASR42_ReadBlock_ODX_FILE_IDENTIFIER: start-on-event=RE_ASR42_ReadBlock, operation=PS_ASR42_ODX_FILE_IDENTIFIER.ReadBlock
        EV_ASR42_ReadPRAMBlock_ODX_FILE_IDENTIFIER: start-on-event=RE_ASR42_ReadPRAMBlock, operation=PS_ASR42_ODX_FILE_IDENTIFIER.ReadPRAMBlock
        EV_ASR42_WriteBlock_ODX_FILE_IDENTIFIER: start-on-event=RE_ASR42_WriteBlock, operation=PS_ASR42_ODX_FILE_IDENTIFIER.WriteBlock
        EV_ASR42_WritePRAMBlock_ODX_FILE_IDENTIFIER: start-on-event=RE_ASR42_WritePRAMBlock, operation=PS_ASR42_ODX_FILE_IDENTIFIER.WritePRAMBlock
        EV_ASR42_RestoreBlockDefaults_ODX_FILE_IDENTIFIER: start-on-event=RE_ASR42_RestoreBlockDefaults, operation=PS_ASR42_ODX_FILE_IDENTIFIER.RestoreBlockDefaults
        EV_ASR42_RestorePRAMBlockDefaults_ODX_FILE_IDENTIFIER: start-on-event=RE_ASR42_RestorePRAMBlockDefaults, operation=PS_ASR42_ODX_FILE_IDENTIFIER.RestorePRAMBlockDefaults
        EV_ASR42_EraseBlock_ODX_FILE_IDENTIFIER: start-on-event=RE_ASR42_EraseBlock, operation=PS_ASR42_ODX_FILE_IDENTIFIER.EraseBlock
        EV_ASR42_InvalidateNvBlock_ODX_FILE_IDENTIFIER: start-on-event=RE_ASR42_InvalidateNvBlock, operation=PS_ASR42_ODX_FILE_IDENTIFIER.InvalidateNvBlock
        EV_ASR42_GetErrorStatus_ODX_FILE_VERSION: start-on-event=RE_ASR42_GetErrorStatus, operation=PS_ASR42_ODX_FILE_VERSION.GetErrorStatus
        EV_ASR42_SetDataIndex_ODX_FILE_VERSION: start-on-event=RE_ASR42_SetDataIndex, operation=PS_ASR42_ODX_FILE_VERSION.SetDataIndex
        EV_ASR42_GetDataIndex_ODX_FILE_VERSION: start-on-event=RE_ASR42_GetDataIndex, operation=PS_ASR42_ODX_FILE_VERSION.GetDataIndex
        EV_ASR42_SetRamBlockStatus_ODX_FILE_VERSION: start-on-event=RE_ASR42_SetRamBlockStatus, operation=PS_ASR42_ODX_FILE_VERSION.SetRamBlockStatus
        EV_ASR42_ReadBlock_ODX_FILE_VERSION: start-on-event=RE_ASR42_ReadBlock, operation=PS_ASR42_ODX_FILE_VERSION.ReadBlock
        EV_ASR42_ReadPRAMBlock_ODX_FILE_VERSION: start-on-event=RE_ASR42_ReadPRAMBlock, operation=PS_ASR42_ODX_FILE_VERSION.ReadPRAMBlock
        EV_ASR42_WriteBlock_ODX_FILE_VERSION: start-on-event=RE_ASR42_WriteBlock, operation=PS_ASR42_ODX_FILE_VERSION.WriteBlock
        EV_ASR42_WritePRAMBlock_ODX_FILE_VERSION: start-on-event=RE_ASR42_WritePRAMBlock, operation=PS_ASR42_ODX_FILE_VERSION.WritePRAMBlock
        EV_ASR42_RestoreBlockDefaults_ODX_FILE_VERSION: start-on-event=RE_ASR42_RestoreBlockDefaults, operation=PS_ASR42_ODX_FILE_VERSION.RestoreBlockDefaults
        EV_ASR42_RestorePRAMBlockDefaults_ODX_FILE_VERSION: start-on-event=RE_ASR42_RestorePRAMBlockDefaults, operation=PS_ASR42_ODX_FILE_VERSION.RestorePRAMBlockDefaults
        EV_ASR42_EraseBlock_ODX_FILE_VERSION: start-on-event=RE_ASR42_EraseBlock, operation=PS_ASR42_ODX_FILE_VERSION.EraseBlock
        EV_ASR42_InvalidateNvBlock_ODX_FILE_VERSION: start-on-event=RE_ASR42_InvalidateNvBlock, operation=PS_ASR42_ODX_FILE_VERSION.InvalidateNvBlock
        EV_ASR42_GetErrorStatus_ECU_SERIAL_NUMBER: start-on-event=RE_ASR42_GetErrorStatus, operation=PS_ASR42_ECU_SERIAL_NUMBER.GetErrorStatus
        EV_ASR42_SetDataIndex_ECU_SERIAL_NUMBER: start-on-event=RE_ASR42_SetDataIndex, operation=PS_ASR42_ECU_SERIAL_NUMBER.SetDataIndex
        EV_ASR42_GetDataIndex_ECU_SERIAL_NUMBER: start-on-event=RE_ASR42_GetDataIndex, operation=PS_ASR42_ECU_SERIAL_NUMBER.GetDataIndex
        EV_ASR42_SetRamBlockStatus_ECU_SERIAL_NUMBER: start-on-event=RE_ASR42_SetRamBlockStatus, operation=PS_ASR42_ECU_SERIAL_NUMBER.SetRamBlockStatus
        EV_ASR42_ReadBlock_ECU_SERIAL_NUMBER: start-on-event=RE_ASR42_ReadBlock, operation=PS_ASR42_ECU_SERIAL_NUMBER.ReadBlock
        EV_ASR42_ReadPRAMBlock_ECU_SERIAL_NUMBER: start-on-event=RE_ASR42_ReadPRAMBlock, operation=PS_ASR42_ECU_SERIAL_NUMBER.ReadPRAMBlock
        EV_ASR42_WriteBlock_ECU_SERIAL_NUMBER: start-on-event=RE_ASR42_WriteBlock, operation=PS_ASR42_ECU_SERIAL_NUMBER.WriteBlock
        EV_ASR42_WritePRAMBlock_ECU_SERIAL_NUMBER: start-on-event=RE_ASR42_WritePRAMBlock, operation=PS_ASR42_ECU_SERIAL_NUMBER.WritePRAMBlock
        EV_ASR42_RestoreBlockDefaults_ECU_SERIAL_NUMBER: start-on-event=RE_ASR42_RestoreBlockDefaults, operation=PS_ASR42_ECU_SERIAL_NUMBER.RestoreBlockDefaults
        EV_ASR42_RestorePRAMBlockDefaults_ECU_SERIAL_NUMBER: start-on-event=RE_ASR42_RestorePRAMBlockDefaults, operation=PS_ASR42_ECU_SERIAL_NUMBER.RestorePRAMBlockDefaults
        EV_ASR42_EraseBlock_ECU_SERIAL_NUMBER: start-on-event=RE_ASR42_EraseBlock, operation=PS_ASR42_ECU_SERIAL_NUMBER.EraseBlock
        EV_ASR42_InvalidateNvBlock_ECU_SERIAL_NUMBER: start-on-event=RE_ASR42_InvalidateNvBlock, operation=PS_ASR42_ECU_SERIAL_NUMBER.InvalidateNvBlock
        EV_ASR42_GetErrorStatus_LOGICAL_SW_BLOCK_VERSION: start-on-event=RE_ASR42_GetErrorStatus, operation=PS_ASR42_LOGICAL_SW_BLOCK_VERSION.GetErrorStatus
        EV_ASR42_SetDataIndex_LOGICAL_SW_BLOCK_VERSION: start-on-event=RE_ASR42_SetDataIndex, operation=PS_ASR42_LOGICAL_SW_BLOCK_VERSION.SetDataIndex
        EV_ASR42_GetDataIndex_LOGICAL_SW_BLOCK_VERSION: start-on-event=RE_ASR42_GetDataIndex, operation=PS_ASR42_LOGICAL_SW_BLOCK_VERSION.GetDataIndex
        EV_ASR42_SetRamBlockStatus_LOGICAL_SW_BLOCK_VERSION: start-on-event=RE_ASR42_SetRamBlockStatus, operation=PS_ASR42_LOGICAL_SW_BLOCK_VERSION.SetRamBlockStatus
        EV_ASR42_ReadBlock_LOGICAL_SW_BLOCK_VERSION: start-on-event=RE_ASR42_ReadBlock, operation=PS_ASR42_LOGICAL_SW_BLOCK_VERSION.ReadBlock
        EV_ASR42_ReadPRAMBlock_LOGICAL_SW_BLOCK_VERSION: start-on-event=RE_ASR42_ReadPRAMBlock, operation=PS_ASR42_LOGICAL_SW_BLOCK_VERSION.ReadPRAMBlock
        EV_ASR42_WriteBlock_LOGICAL_SW_BLOCK_VERSION: start-on-event=RE_ASR42_WriteBlock, operation=PS_ASR42_LOGICAL_SW_BLOCK_VERSION.WriteBlock
        EV_ASR42_WritePRAMBlock_LOGICAL_SW_BLOCK_VERSION: start-on-event=RE_ASR42_WritePRAMBlock, operation=PS_ASR42_LOGICAL_SW_BLOCK_VERSION.WritePRAMBlock
        EV_ASR42_RestoreBlockDefaults_LOGICAL_SW_BLOCK_VERSION: start-on-event=RE_ASR42_RestoreBlockDefaults, operation=PS_ASR42_LOGICAL_SW_BLOCK_VERSION.RestoreBlockDefaults
        EV_ASR42_RestorePRAMBlockDefaults_LOGICAL_SW_BLOCK_VERSION: start-on-event=RE_ASR42_RestorePRAMBlockDefaults, operation=PS_ASR42_LOGICAL_SW_BLOCK_VERSION.RestorePRAMBlockDefaults
        EV_ASR42_EraseBlock_LOGICAL_SW_BLOCK_VERSION: start-on-event=RE_ASR42_EraseBlock, operation=PS_ASR42_LOGICAL_SW_BLOCK_VERSION.EraseBlock
        EV_ASR42_InvalidateNvBlock_LOGICAL_SW_BLOCK_VERSION: start-on-event=RE_ASR42_InvalidateNvBlock, operation=PS_ASR42_LOGICAL_SW_BLOCK_VERSION.InvalidateNvBlock
        EV_ASR42_GetErrorStatus_HARDWARE_VERSION_NUMBER: start-on-event=RE_ASR42_GetErrorStatus, operation=PS_ASR42_HARDWARE_VERSION_NUMBER.GetErrorStatus
        EV_ASR42_SetDataIndex_HARDWARE_VERSION_NUMBER: start-on-event=RE_ASR42_SetDataIndex, operation=PS_ASR42_HARDWARE_VERSION_NUMBER.SetDataIndex
        EV_ASR42_GetDataIndex_HARDWARE_VERSION_NUMBER: start-on-event=RE_ASR42_GetDataIndex, operation=PS_ASR42_HARDWARE_VERSION_NUMBER.GetDataIndex
        EV_ASR42_SetRamBlockStatus_HARDWARE_VERSION_NUMBER: start-on-event=RE_ASR42_SetRamBlockStatus, operation=PS_ASR42_HARDWARE_VERSION_NUMBER.SetRamBlockStatus
        EV_ASR42_ReadBlock_HARDWARE_VERSION_NUMBER: start-on-event=RE_ASR42_ReadBlock, operation=PS_ASR42_HARDWARE_VERSION_NUMBER.ReadBlock
        EV_ASR42_ReadPRAMBlock_HARDWARE_VERSION_NUMBER: start-on-event=RE_ASR42_ReadPRAMBlock, operation=PS_ASR42_HARDWARE_VERSION_NUMBER.ReadPRAMBlock
        EV_ASR42_WriteBlock_HARDWARE_VERSION_NUMBER: start-on-event=RE_ASR42_WriteBlock, operation=PS_ASR42_HARDWARE_VERSION_NUMBER.WriteBlock
        EV_ASR42_WritePRAMBlock_HARDWARE_VERSION_NUMBER: start-on-event=RE_ASR42_WritePRAMBlock, operation=PS_ASR42_HARDWARE_VERSION_NUMBER.WritePRAMBlock
        EV_ASR42_RestoreBlockDefaults_HARDWARE_VERSION_NUMBER: start-on-event=RE_ASR42_RestoreBlockDefaults, operation=PS_ASR42_HARDWARE_VERSION_NUMBER.RestoreBlockDefaults
        EV_ASR42_RestorePRAMBlockDefaults_HARDWARE_VERSION_NUMBER: start-on-event=RE_ASR42_RestorePRAMBlockDefaults, operation=PS_ASR42_HARDWARE_VERSION_NUMBER.RestorePRAMBlockDefaults
        EV_ASR42_EraseBlock_HARDWARE_VERSION_NUMBER: start-on-event=RE_ASR42_EraseBlock, operation=PS_ASR42_HARDWARE_VERSION_NUMBER.EraseBlock
        EV_ASR42_InvalidateNvBlock_HARDWARE_VERSION_NUMBER: start-on-event=RE_ASR42_InvalidateNvBlock, operation=PS_ASR42_HARDWARE_VERSION_NUMBER.InvalidateNvBlock
        EV_ASR42_GetErrorStatus_APP_SOFTWARE_VERSION_NUMBER: start-on-event=RE_ASR42_GetErrorStatus, operation=PS_ASR42_APP_SOFTWARE_VERSION_NUMBER.GetErrorStatus
        EV_ASR42_SetDataIndex_APP_SOFTWARE_VERSION_NUMBER: start-on-event=RE_ASR42_SetDataIndex, operation=PS_ASR42_APP_SOFTWARE_VERSION_NUMBER.SetDataIndex
        EV_ASR42_GetDataIndex_APP_SOFTWARE_VERSION_NUMBER: start-on-event=RE_ASR42_GetDataIndex, operation=PS_ASR42_APP_SOFTWARE_VERSION_NUMBER.GetDataIndex
        EV_ASR42_SetRamBlockStatus_APP_SOFTWARE_VERSION_NUMBER: start-on-event=RE_ASR42_SetRamBlockStatus, operation=PS_ASR42_APP_SOFTWARE_VERSION_NUMBER.SetRamBlockStatus
        EV_ASR42_ReadBlock_APP_SOFTWARE_VERSION_NUMBER: start-on-event=RE_ASR42_ReadBlock, operation=PS_ASR42_APP_SOFTWARE_VERSION_NUMBER.ReadBlock
        EV_ASR42_ReadPRAMBlock_APP_SOFTWARE_VERSION_NUMBER: start-on-event=RE_ASR42_ReadPRAMBlock, operation=PS_ASR42_APP_SOFTWARE_VERSION_NUMBER.ReadPRAMBlock
        EV_ASR42_WriteBlock_APP_SOFTWARE_VERSION_NUMBER: start-on-event=RE_ASR42_WriteBlock, operation=PS_ASR42_APP_SOFTWARE_VERSION_NUMBER.WriteBlock
        EV_ASR42_WritePRAMBlock_APP_SOFTWARE_VERSION_NUMBER: start-on-event=RE_ASR42_WritePRAMBlock, operation=PS_ASR42_APP_SOFTWARE_VERSION_NUMBER.WritePRAMBlock
        EV_ASR42_RestoreBlockDefaults_APP_SOFTWARE_VERSION_NUMBER: start-on-event=RE_ASR42_RestoreBlockDefaults, operation=PS_ASR42_APP_SOFTWARE_VERSION_NUMBER.RestoreBlockDefaults
        EV_ASR42_RestorePRAMBlockDefaults_APP_SOFTWARE_VERSION_NUMBER: start-on-event=RE_ASR42_RestorePRAMBlockDefaults, operation=PS_ASR42_APP_SOFTWARE_VERSION_NUMBER.RestorePRAMBlockDefaults
        EV_ASR42_EraseBlock_APP_SOFTWARE_VERSION_NUMBER: start-on-event=RE_ASR42_EraseBlock, operation=PS_ASR42_APP_SOFTWARE_VERSION_NUMBER.EraseBlock
        EV_ASR42_InvalidateNvBlock_APP_SOFTWARE_VERSION_NUMBER: start-on-event=RE_ASR42_InvalidateNvBlock, operation=PS_ASR42_APP_SOFTWARE_VERSION_NUMBER.InvalidateNvBlock
        EV_ASR42_GetErrorStatus_ECS_STEPS: start-on-event=RE_ASR42_GetErrorStatus, operation=PS_ASR42_ECS_STEPS.GetErrorStatus
        EV_ASR42_SetDataIndex_ECS_STEPS: start-on-event=RE_ASR42_SetDataIndex, operation=PS_ASR42_ECS_STEPS.SetDataIndex
        EV_ASR42_GetDataIndex_ECS_STEPS: start-on-event=RE_ASR42_GetDataIndex, operation=PS_ASR42_ECS_STEPS.GetDataIndex
        EV_ASR42_SetRamBlockStatus_ECS_STEPS: start-on-event=RE_ASR42_SetRamBlockStatus, operation=PS_ASR42_ECS_STEPS.SetRamBlockStatus
        EV_ASR42_ReadBlock_ECS_STEPS: start-on-event=RE_ASR42_ReadBlock, operation=PS_ASR42_ECS_STEPS.ReadBlock
        EV_ASR42_ReadPRAMBlock_ECS_STEPS: start-on-event=RE_ASR42_ReadPRAMBlock, operation=PS_ASR42_ECS_STEPS.ReadPRAMBlock
        EV_ASR42_WriteBlock_ECS_STEPS: start-on-event=RE_ASR42_WriteBlock, operation=PS_ASR42_ECS_STEPS.WriteBlock
        EV_ASR42_WritePRAMBlock_ECS_STEPS: start-on-event=RE_ASR42_WritePRAMBlock, operation=PS_ASR42_ECS_STEPS.WritePRAMBlock
        EV_ASR42_RestoreBlockDefaults_ECS_STEPS: start-on-event=RE_ASR42_RestoreBlockDefaults, operation=PS_ASR42_ECS_STEPS.RestoreBlockDefaults
        EV_ASR42_RestorePRAMBlockDefaults_ECS_STEPS: start-on-event=RE_ASR42_RestorePRAMBlockDefaults, operation=PS_ASR42_ECS_STEPS.RestorePRAMBlockDefaults
        EV_ASR42_EraseBlock_ECS_STEPS: start-on-event=RE_ASR42_EraseBlock, operation=PS_ASR42_ECS_STEPS.EraseBlock
        EV_ASR42_InvalidateNvBlock_ECS_STEPS: start-on-event=RE_ASR42_InvalidateNvBlock, operation=PS_ASR42_ECS_STEPS.InvalidateNvBlock
        EV_ASR42_GetErrorStatus_ECS_PARAMETERS: start-on-event=RE_ASR42_GetErrorStatus, operation=PS_ASR42_ECS_PARAMETERS.GetErrorStatus
        EV_ASR42_SetDataIndex_ECS_PARAMETERS: start-on-event=RE_ASR42_SetDataIndex, operation=PS_ASR42_ECS_PARAMETERS.SetDataIndex
        EV_ASR42_GetDataIndex_ECS_PARAMETERS: start-on-event=RE_ASR42_GetDataIndex, operation=PS_ASR42_ECS_PARAMETERS.GetDataIndex
        EV_ASR42_SetRamBlockStatus_ECS_PARAMETERS: start-on-event=RE_ASR42_SetRamBlockStatus, operation=PS_ASR42_ECS_PARAMETERS.SetRamBlockStatus
        EV_ASR42_ReadBlock_ECS_PARAMETERS: start-on-event=RE_ASR42_ReadBlock, operation=PS_ASR42_ECS_PARAMETERS.ReadBlock
        EV_ASR42_ReadPRAMBlock_ECS_PARAMETERS: start-on-event=RE_ASR42_ReadPRAMBlock, operation=PS_ASR42_ECS_PARAMETERS.ReadPRAMBlock
        EV_ASR42_WriteBlock_ECS_PARAMETERS: start-on-event=RE_ASR42_WriteBlock, operation=PS_ASR42_ECS_PARAMETERS.WriteBlock
        EV_ASR42_WritePRAMBlock_ECS_PARAMETERS: start-on-event=RE_ASR42_WritePRAMBlock, operation=PS_ASR42_ECS_PARAMETERS.WritePRAMBlock
        EV_ASR42_RestoreBlockDefaults_ECS_PARAMETERS: start-on-event=RE_ASR42_RestoreBlockDefaults, operation=PS_ASR42_ECS_PARAMETERS.RestoreBlockDefaults
        EV_ASR42_RestorePRAMBlockDefaults_ECS_PARAMETERS: start-on-event=RE_ASR42_RestorePRAMBlockDefaults, operation=PS_ASR42_ECS_PARAMETERS.RestorePRAMBlockDefaults
        EV_ASR42_EraseBlock_ECS_PARAMETERS: start-on-event=RE_ASR42_EraseBlock, operation=PS_ASR42_ECS_PARAMETERS.EraseBlock
        EV_ASR42_InvalidateNvBlock_ECS_PARAMETERS: start-on-event=RE_ASR42_InvalidateNvBlock, operation=PS_ASR42_ECS_PARAMETERS.InvalidateNvBlock
        EV_GetErrorStatus_NVM_BLOCK_DEM_DEFAULT: start-on-event=RE_GetErrorStatus, operation=PS_NVM_BLOCK_DEM_DEFAULT.GetErrorStatus
        EV_SetDataIndex_NVM_BLOCK_DEM_DEFAULT: start-on-event=RE_SetDataIndex, operation=PS_NVM_BLOCK_DEM_DEFAULT.SetDataIndex
        EV_GetDataIndex_NVM_BLOCK_DEM_DEFAULT: start-on-event=RE_GetDataIndex, operation=PS_NVM_BLOCK_DEM_DEFAULT.GetDataIndex
        EV_SetRamBlockStatus_NVM_BLOCK_DEM_DEFAULT: start-on-event=RE_SetRamBlockStatus, operation=PS_NVM_BLOCK_DEM_DEFAULT.SetRamBlockStatus
        EV_ReadBlock_NVM_BLOCK_DEM_DEFAULT: start-on-event=RE_ReadBlock, operation=PS_NVM_BLOCK_DEM_DEFAULT.ReadBlock
        EV_ReadPRAMBlock_NVM_BLOCK_DEM_DEFAULT: start-on-event=RE_ReadPRAMBlock, operation=PS_NVM_BLOCK_DEM_DEFAULT.ReadPRAMBlock
        EV_WriteBlock_NVM_BLOCK_DEM_DEFAULT: start-on-event=RE_WriteBlock, operation=PS_NVM_BLOCK_DEM_DEFAULT.WriteBlock
        EV_WritePRAMBlock_NVM_BLOCK_DEM_DEFAULT: start-on-event=RE_WritePRAMBlock, operation=PS_NVM_BLOCK_DEM_DEFAULT.WritePRAMBlock
        EV_RestoreBlockDefaults_NVM_BLOCK_DEM_DEFAULT: start-on-event=RE_RestoreBlockDefaults, operation=PS_NVM_BLOCK_DEM_DEFAULT.RestoreBlockDefaults
        EV_RestorePRAMBlockDefaults_NVM_BLOCK_DEM_DEFAULT: start-on-event=RE_RestorePRAMBlockDefaults, operation=PS_NVM_BLOCK_DEM_DEFAULT.RestorePRAMBlockDefaults
        EV_EraseBlock_NVM_BLOCK_DEM_DEFAULT: start-on-event=RE_EraseBlock, operation=PS_NVM_BLOCK_DEM_DEFAULT.EraseBlock
        EV_InvalidateNvBlock_NVM_BLOCK_DEM_DEFAULT: start-on-event=RE_InvalidateNvBlock, operation=PS_NVM_BLOCK_DEM_DEFAULT.InvalidateNvBlock
        EV_GetErrorStatus_ECC_COUNTERS: start-on-event=RE_GetErrorStatus, operation=PS_ECC_COUNTERS.GetErrorStatus
        EV_SetDataIndex_ECC_COUNTERS: start-on-event=RE_SetDataIndex, operation=PS_ECC_COUNTERS.SetDataIndex
        EV_GetDataIndex_ECC_COUNTERS: start-on-event=RE_GetDataIndex, operation=PS_ECC_COUNTERS.GetDataIndex
        EV_SetRamBlockStatus_ECC_COUNTERS: start-on-event=RE_SetRamBlockStatus, operation=PS_ECC_COUNTERS.SetRamBlockStatus
        EV_ReadBlock_ECC_COUNTERS: start-on-event=RE_ReadBlock, operation=PS_ECC_COUNTERS.ReadBlock
        EV_ReadPRAMBlock_ECC_COUNTERS: start-on-event=RE_ReadPRAMBlock, operation=PS_ECC_COUNTERS.ReadPRAMBlock
        EV_WriteBlock_ECC_COUNTERS: start-on-event=RE_WriteBlock, operation=PS_ECC_COUNTERS.WriteBlock
        EV_WritePRAMBlock_ECC_COUNTERS: start-on-event=RE_WritePRAMBlock, operation=PS_ECC_COUNTERS.WritePRAMBlock
        EV_RestoreBlockDefaults_ECC_COUNTERS: start-on-event=RE_RestoreBlockDefaults, operation=PS_ECC_COUNTERS.RestoreBlockDefaults
        EV_RestorePRAMBlockDefaults_ECC_COUNTERS: start-on-event=RE_RestorePRAMBlockDefaults, operation=PS_ECC_COUNTERS.RestorePRAMBlockDefaults
        EV_EraseBlock_ECC_COUNTERS: start-on-event=RE_EraseBlock, operation=PS_ECC_COUNTERS.EraseBlock
        EV_InvalidateNvBlock_ECC_COUNTERS: start-on-event=RE_InvalidateNvBlock, operation=PS_ECC_COUNTERS.InvalidateNvBlock
        EV_GetErrorStatus_WARM_RESET_COUNTERS: start-on-event=RE_GetErrorStatus, operation=PS_WARM_RESET_COUNTERS.GetErrorStatus
        EV_SetDataIndex_WARM_RESET_COUNTERS: start-on-event=RE_SetDataIndex, operation=PS_WARM_RESET_COUNTERS.SetDataIndex
        EV_GetDataIndex_WARM_RESET_COUNTERS: start-on-event=RE_GetDataIndex, operation=PS_WARM_RESET_COUNTERS.GetDataIndex
        EV_SetRamBlockStatus_WARM_RESET_COUNTERS: start-on-event=RE_SetRamBlockStatus, operation=PS_WARM_RESET_COUNTERS.SetRamBlockStatus
        EV_ReadBlock_WARM_RESET_COUNTERS: start-on-event=RE_ReadBlock, operation=PS_WARM_RESET_COUNTERS.ReadBlock
        EV_ReadPRAMBlock_WARM_RESET_COUNTERS: start-on-event=RE_ReadPRAMBlock, operation=PS_WARM_RESET_COUNTERS.ReadPRAMBlock
        EV_WriteBlock_WARM_RESET_COUNTERS: start-on-event=RE_WriteBlock, operation=PS_WARM_RESET_COUNTERS.WriteBlock
        EV_WritePRAMBlock_WARM_RESET_COUNTERS: start-on-event=RE_WritePRAMBlock, operation=PS_WARM_RESET_COUNTERS.WritePRAMBlock
        EV_RestoreBlockDefaults_WARM_RESET_COUNTERS: start-on-event=RE_RestoreBlockDefaults, operation=PS_WARM_RESET_COUNTERS.RestoreBlockDefaults
        EV_RestorePRAMBlockDefaults_WARM_RESET_COUNTERS: start-on-event=RE_RestorePRAMBlockDefaults, operation=PS_WARM_RESET_COUNTERS.RestorePRAMBlockDefaults
        EV_EraseBlock_WARM_RESET_COUNTERS: start-on-event=RE_EraseBlock, operation=PS_WARM_RESET_COUNTERS.EraseBlock
        EV_InvalidateNvBlock_WARM_RESET_COUNTERS: start-on-event=RE_InvalidateNvBlock, operation=PS_WARM_RESET_COUNTERS.InvalidateNvBlock
        EV_GetErrorStatus_SOLENOID_UNLOCK_CONF_PARAM: start-on-event=RE_GetErrorStatus, operation=PS_SOLENOID_UNLOCK_CONF_PARAM.GetErrorStatus
        EV_SetDataIndex_SOLENOID_UNLOCK_CONF_PARAM: start-on-event=RE_SetDataIndex, operation=PS_SOLENOID_UNLOCK_CONF_PARAM.SetDataIndex
        EV_GetDataIndex_SOLENOID_UNLOCK_CONF_PARAM: start-on-event=RE_GetDataIndex, operation=PS_SOLENOID_UNLOCK_CONF_PARAM.GetDataIndex
        EV_SetRamBlockStatus_SOLENOID_UNLOCK_CONF_PARAM: start-on-event=RE_SetRamBlockStatus, operation=PS_SOLENOID_UNLOCK_CONF_PARAM.SetRamBlockStatus
        EV_ReadBlock_SOLENOID_UNLOCK_CONF_PARAM: start-on-event=RE_ReadBlock, operation=PS_SOLENOID_UNLOCK_CONF_PARAM.ReadBlock
        EV_ReadPRAMBlock_SOLENOID_UNLOCK_CONF_PARAM: start-on-event=RE_ReadPRAMBlock, operation=PS_SOLENOID_UNLOCK_CONF_PARAM.ReadPRAMBlock
        EV_WriteBlock_SOLENOID_UNLOCK_CONF_PARAM: start-on-event=RE_WriteBlock, operation=PS_SOLENOID_UNLOCK_CONF_PARAM.WriteBlock
        EV_WritePRAMBlock_SOLENOID_UNLOCK_CONF_PARAM: start-on-event=RE_WritePRAMBlock, operation=PS_SOLENOID_UNLOCK_CONF_PARAM.WritePRAMBlock
        EV_RestoreBlockDefaults_SOLENOID_UNLOCK_CONF_PARAM: start-on-event=RE_RestoreBlockDefaults, operation=PS_SOLENOID_UNLOCK_CONF_PARAM.RestoreBlockDefaults
        EV_RestorePRAMBlockDefaults_SOLENOID_UNLOCK_CONF_PARAM: start-on-event=RE_RestorePRAMBlockDefaults, operation=PS_SOLENOID_UNLOCK_CONF_PARAM.RestorePRAMBlockDefaults
        EV_EraseBlock_SOLENOID_UNLOCK_CONF_PARAM: start-on-event=RE_EraseBlock, operation=PS_SOLENOID_UNLOCK_CONF_PARAM.EraseBlock
        EV_InvalidateNvBlock_SOLENOID_UNLOCK_CONF_PARAM: start-on-event=RE_InvalidateNvBlock, operation=PS_SOLENOID_UNLOCK_CONF_PARAM.InvalidateNvBlock
        EV_GetErrorStatus_AUTOTEST_ENABLE_PARAM: start-on-event=RE_GetErrorStatus, operation=PS_AUTOTEST_ENABLE_PARAM.GetErrorStatus
        EV_SetDataIndex_AUTOTEST_ENABLE_PARAM: start-on-event=RE_SetDataIndex, operation=PS_AUTOTEST_ENABLE_PARAM.SetDataIndex
        EV_GetDataIndex_AUTOTEST_ENABLE_PARAM: start-on-event=RE_GetDataIndex, operation=PS_AUTOTEST_ENABLE_PARAM.GetDataIndex
        EV_SetRamBlockStatus_AUTOTEST_ENABLE_PARAM: start-on-event=RE_SetRamBlockStatus, operation=PS_AUTOTEST_ENABLE_PARAM.SetRamBlockStatus
        EV_ReadBlock_AUTOTEST_ENABLE_PARAM: start-on-event=RE_ReadBlock, operation=PS_AUTOTEST_ENABLE_PARAM.ReadBlock
        EV_ReadPRAMBlock_AUTOTEST_ENABLE_PARAM: start-on-event=RE_ReadPRAMBlock, operation=PS_AUTOTEST_ENABLE_PARAM.ReadPRAMBlock
        EV_WriteBlock_AUTOTEST_ENABLE_PARAM: start-on-event=RE_WriteBlock, operation=PS_AUTOTEST_ENABLE_PARAM.WriteBlock
        EV_WritePRAMBlock_AUTOTEST_ENABLE_PARAM: start-on-event=RE_WritePRAMBlock, operation=PS_AUTOTEST_ENABLE_PARAM.WritePRAMBlock
        EV_RestoreBlockDefaults_AUTOTEST_ENABLE_PARAM: start-on-event=RE_RestoreBlockDefaults, operation=PS_AUTOTEST_ENABLE_PARAM.RestoreBlockDefaults
        EV_RestorePRAMBlockDefaults_AUTOTEST_ENABLE_PARAM: start-on-event=RE_RestorePRAMBlockDefaults, operation=PS_AUTOTEST_ENABLE_PARAM.RestorePRAMBlockDefaults
        EV_EraseBlock_AUTOTEST_ENABLE_PARAM: start-on-event=RE_EraseBlock, operation=PS_AUTOTEST_ENABLE_PARAM.EraseBlock
        EV_InvalidateNvBlock_AUTOTEST_ENABLE_PARAM: start-on-event=RE_InvalidateNvBlock, operation=PS_AUTOTEST_ENABLE_PARAM.InvalidateNvBlock
        EV_GetErrorStatus_LOCK_UNLOCK_ECU: start-on-event=RE_GetErrorStatus, operation=PS_LOCK_UNLOCK_ECU.GetErrorStatus
        EV_SetDataIndex_LOCK_UNLOCK_ECU: start-on-event=RE_SetDataIndex, operation=PS_LOCK_UNLOCK_ECU.SetDataIndex
        EV_GetDataIndex_LOCK_UNLOCK_ECU: start-on-event=RE_GetDataIndex, operation=PS_LOCK_UNLOCK_ECU.GetDataIndex
        EV_SetRamBlockStatus_LOCK_UNLOCK_ECU: start-on-event=RE_SetRamBlockStatus, operation=PS_LOCK_UNLOCK_ECU.SetRamBlockStatus
        EV_ReadBlock_LOCK_UNLOCK_ECU: start-on-event=RE_ReadBlock, operation=PS_LOCK_UNLOCK_ECU.ReadBlock
        EV_ReadPRAMBlock_LOCK_UNLOCK_ECU: start-on-event=RE_ReadPRAMBlock, operation=PS_LOCK_UNLOCK_ECU.ReadPRAMBlock
        EV_WriteBlock_LOCK_UNLOCK_ECU: start-on-event=RE_WriteBlock, operation=PS_LOCK_UNLOCK_ECU.WriteBlock
        EV_WritePRAMBlock_LOCK_UNLOCK_ECU: start-on-event=RE_WritePRAMBlock, operation=PS_LOCK_UNLOCK_ECU.WritePRAMBlock
        EV_RestoreBlockDefaults_LOCK_UNLOCK_ECU: start-on-event=RE_RestoreBlockDefaults, operation=PS_LOCK_UNLOCK_ECU.RestoreBlockDefaults
        EV_RestorePRAMBlockDefaults_LOCK_UNLOCK_ECU: start-on-event=RE_RestorePRAMBlockDefaults, operation=PS_LOCK_UNLOCK_ECU.RestorePRAMBlockDefaults
        EV_EraseBlock_LOCK_UNLOCK_ECU: start-on-event=RE_EraseBlock, operation=PS_LOCK_UNLOCK_ECU.EraseBlock
        EV_InvalidateNvBlock_LOCK_UNLOCK_ECU: start-on-event=RE_InvalidateNvBlock, operation=PS_LOCK_UNLOCK_ECU.InvalidateNvBlock
        EV_GetErrorStatus_MEASUREMENT_FRAME_CONFIG: start-on-event=RE_GetErrorStatus, operation=PS_MEASUREMENT_FRAME_CONFIG.GetErrorStatus
        EV_SetDataIndex_MEASUREMENT_FRAME_CONFIG: start-on-event=RE_SetDataIndex, operation=PS_MEASUREMENT_FRAME_CONFIG.SetDataIndex
        EV_GetDataIndex_MEASUREMENT_FRAME_CONFIG: start-on-event=RE_GetDataIndex, operation=PS_MEASUREMENT_FRAME_CONFIG.GetDataIndex
        EV_SetRamBlockStatus_MEASUREMENT_FRAME_CONFIG: start-on-event=RE_SetRamBlockStatus, operation=PS_MEASUREMENT_FRAME_CONFIG.SetRamBlockStatus
        EV_ReadBlock_MEASUREMENT_FRAME_CONFIG: start-on-event=RE_ReadBlock, operation=PS_MEASUREMENT_FRAME_CONFIG.ReadBlock
        EV_ReadPRAMBlock_MEASUREMENT_FRAME_CONFIG: start-on-event=RE_ReadPRAMBlock, operation=PS_MEASUREMENT_FRAME_CONFIG.ReadPRAMBlock
        EV_WriteBlock_MEASUREMENT_FRAME_CONFIG: start-on-event=RE_WriteBlock, operation=PS_MEASUREMENT_FRAME_CONFIG.WriteBlock
        EV_WritePRAMBlock_MEASUREMENT_FRAME_CONFIG: start-on-event=RE_WritePRAMBlock, operation=PS_MEASUREMENT_FRAME_CONFIG.WritePRAMBlock
        EV_RestoreBlockDefaults_MEASUREMENT_FRAME_CONFIG: start-on-event=RE_RestoreBlockDefaults, operation=PS_MEASUREMENT_FRAME_CONFIG.RestoreBlockDefaults
        EV_RestorePRAMBlockDefaults_MEASUREMENT_FRAME_CONFIG: start-on-event=RE_RestorePRAMBlockDefaults, operation=PS_MEASUREMENT_FRAME_CONFIG.RestorePRAMBlockDefaults
        EV_EraseBlock_MEASUREMENT_FRAME_CONFIG: start-on-event=RE_EraseBlock, operation=PS_MEASUREMENT_FRAME_CONFIG.EraseBlock
        EV_InvalidateNvBlock_MEASUREMENT_FRAME_CONFIG: start-on-event=RE_InvalidateNvBlock, operation=PS_MEASUREMENT_FRAME_CONFIG.InvalidateNvBlock
        EV_GetErrorStatus_HW_PART_NUMBER: start-on-event=RE_GetErrorStatus, operation=PS_HW_PART_NUMBER.GetErrorStatus
        EV_SetDataIndex_HW_PART_NUMBER: start-on-event=RE_SetDataIndex, operation=PS_HW_PART_NUMBER.SetDataIndex
        EV_GetDataIndex_HW_PART_NUMBER: start-on-event=RE_GetDataIndex, operation=PS_HW_PART_NUMBER.GetDataIndex
        EV_SetRamBlockStatus_HW_PART_NUMBER: start-on-event=RE_SetRamBlockStatus, operation=PS_HW_PART_NUMBER.SetRamBlockStatus
        EV_ReadBlock_HW_PART_NUMBER: start-on-event=RE_ReadBlock, operation=PS_HW_PART_NUMBER.ReadBlock
        EV_ReadPRAMBlock_HW_PART_NUMBER: start-on-event=RE_ReadPRAMBlock, operation=PS_HW_PART_NUMBER.ReadPRAMBlock
        EV_WriteBlock_HW_PART_NUMBER: start-on-event=RE_WriteBlock, operation=PS_HW_PART_NUMBER.WriteBlock
        EV_WritePRAMBlock_HW_PART_NUMBER: start-on-event=RE_WritePRAMBlock, operation=PS_HW_PART_NUMBER.WritePRAMBlock
        EV_RestoreBlockDefaults_HW_PART_NUMBER: start-on-event=RE_RestoreBlockDefaults, operation=PS_HW_PART_NUMBER.RestoreBlockDefaults
        EV_RestorePRAMBlockDefaults_HW_PART_NUMBER: start-on-event=RE_RestorePRAMBlockDefaults, operation=PS_HW_PART_NUMBER.RestorePRAMBlockDefaults
        EV_EraseBlock_HW_PART_NUMBER: start-on-event=RE_EraseBlock, operation=PS_HW_PART_NUMBER.EraseBlock
        EV_InvalidateNvBlock_HW_PART_NUMBER: start-on-event=RE_InvalidateNvBlock, operation=PS_HW_PART_NUMBER.InvalidateNvBlock
        EV_GetErrorStatus_AEE_TRACEABILITY_NUMBER: start-on-event=RE_GetErrorStatus, operation=PS_AEE_TRACEABILITY_NUMBER.GetErrorStatus
        EV_SetDataIndex_AEE_TRACEABILITY_NUMBER: start-on-event=RE_SetDataIndex, operation=PS_AEE_TRACEABILITY_NUMBER.SetDataIndex
        EV_GetDataIndex_AEE_TRACEABILITY_NUMBER: start-on-event=RE_GetDataIndex, operation=PS_AEE_TRACEABILITY_NUMBER.GetDataIndex
        EV_SetRamBlockStatus_AEE_TRACEABILITY_NUMBER: start-on-event=RE_SetRamBlockStatus, operation=PS_AEE_TRACEABILITY_NUMBER.SetRamBlockStatus
        EV_ReadBlock_AEE_TRACEABILITY_NUMBER: start-on-event=RE_ReadBlock, operation=PS_AEE_TRACEABILITY_NUMBER.ReadBlock
        EV_ReadPRAMBlock_AEE_TRACEABILITY_NUMBER: start-on-event=RE_ReadPRAMBlock, operation=PS_AEE_TRACEABILITY_NUMBER.ReadPRAMBlock
        EV_WriteBlock_AEE_TRACEABILITY_NUMBER: start-on-event=RE_WriteBlock, operation=PS_AEE_TRACEABILITY_NUMBER.WriteBlock
        EV_WritePRAMBlock_AEE_TRACEABILITY_NUMBER: start-on-event=RE_WritePRAMBlock, operation=PS_AEE_TRACEABILITY_NUMBER.WritePRAMBlock
        EV_RestoreBlockDefaults_AEE_TRACEABILITY_NUMBER: start-on-event=RE_RestoreBlockDefaults, operation=PS_AEE_TRACEABILITY_NUMBER.RestoreBlockDefaults
        EV_RestorePRAMBlockDefaults_AEE_TRACEABILITY_NUMBER: start-on-event=RE_RestorePRAMBlockDefaults, operation=PS_AEE_TRACEABILITY_NUMBER.RestorePRAMBlockDefaults
        EV_EraseBlock_AEE_TRACEABILITY_NUMBER: start-on-event=RE_EraseBlock, operation=PS_AEE_TRACEABILITY_NUMBER.EraseBlock
        EV_InvalidateNvBlock_AEE_TRACEABILITY_NUMBER: start-on-event=RE_InvalidateNvBlock, operation=PS_AEE_TRACEABILITY_NUMBER.InvalidateNvBlock
        EV_GetErrorStatus_ECU_ASSEMBLY_SERIAL_NUMBER: start-on-event=RE_GetErrorStatus, operation=PS_ECU_ASSEMBLY_SERIAL_NUMBER.GetErrorStatus
        EV_SetDataIndex_ECU_ASSEMBLY_SERIAL_NUMBER: start-on-event=RE_SetDataIndex, operation=PS_ECU_ASSEMBLY_SERIAL_NUMBER.SetDataIndex
        EV_GetDataIndex_ECU_ASSEMBLY_SERIAL_NUMBER: start-on-event=RE_GetDataIndex, operation=PS_ECU_ASSEMBLY_SERIAL_NUMBER.GetDataIndex
        EV_SetRamBlockStatus_ECU_ASSEMBLY_SERIAL_NUMBER: start-on-event=RE_SetRamBlockStatus, operation=PS_ECU_ASSEMBLY_SERIAL_NUMBER.SetRamBlockStatus
        EV_ReadBlock_ECU_ASSEMBLY_SERIAL_NUMBER: start-on-event=RE_ReadBlock, operation=PS_ECU_ASSEMBLY_SERIAL_NUMBER.ReadBlock
        EV_ReadPRAMBlock_ECU_ASSEMBLY_SERIAL_NUMBER: start-on-event=RE_ReadPRAMBlock, operation=PS_ECU_ASSEMBLY_SERIAL_NUMBER.ReadPRAMBlock
        EV_WriteBlock_ECU_ASSEMBLY_SERIAL_NUMBER: start-on-event=RE_WriteBlock, operation=PS_ECU_ASSEMBLY_SERIAL_NUMBER.WriteBlock
        EV_WritePRAMBlock_ECU_ASSEMBLY_SERIAL_NUMBER: start-on-event=RE_WritePRAMBlock, operation=PS_ECU_ASSEMBLY_SERIAL_NUMBER.WritePRAMBlock
        EV_RestoreBlockDefaults_ECU_ASSEMBLY_SERIAL_NUMBER: start-on-event=RE_RestoreBlockDefaults, operation=PS_ECU_ASSEMBLY_SERIAL_NUMBER.RestoreBlockDefaults
        EV_RestorePRAMBlockDefaults_ECU_ASSEMBLY_SERIAL_NUMBER: start-on-event=RE_RestorePRAMBlockDefaults, operation=PS_ECU_ASSEMBLY_SERIAL_NUMBER.RestorePRAMBlockDefaults
        EV_EraseBlock_ECU_ASSEMBLY_SERIAL_NUMBER: start-on-event=RE_EraseBlock, operation=PS_ECU_ASSEMBLY_SERIAL_NUMBER.EraseBlock
        EV_InvalidateNvBlock_ECU_ASSEMBLY_SERIAL_NUMBER: start-on-event=RE_InvalidateNvBlock, operation=PS_ECU_ASSEMBLY_SERIAL_NUMBER.InvalidateNvBlock
        EV_GetErrorStatus_PROCESS_MODE: start-on-event=RE_GetErrorStatus, operation=PS_PROCESS_MODE.GetErrorStatus
        EV_SetDataIndex_PROCESS_MODE: start-on-event=RE_SetDataIndex, operation=PS_PROCESS_MODE.SetDataIndex
        EV_GetDataIndex_PROCESS_MODE: start-on-event=RE_GetDataIndex, operation=PS_PROCESS_MODE.GetDataIndex
        EV_SetRamBlockStatus_PROCESS_MODE: start-on-event=RE_SetRamBlockStatus, operation=PS_PROCESS_MODE.SetRamBlockStatus
        EV_ReadBlock_PROCESS_MODE: start-on-event=RE_ReadBlock, operation=PS_PROCESS_MODE.ReadBlock
        EV_ReadPRAMBlock_PROCESS_MODE: start-on-event=RE_ReadPRAMBlock, operation=PS_PROCESS_MODE.ReadPRAMBlock
        EV_WriteBlock_PROCESS_MODE: start-on-event=RE_WriteBlock, operation=PS_PROCESS_MODE.WriteBlock
        EV_WritePRAMBlock_PROCESS_MODE: start-on-event=RE_WritePRAMBlock, operation=PS_PROCESS_MODE.WritePRAMBlock
        EV_RestoreBlockDefaults_PROCESS_MODE: start-on-event=RE_RestoreBlockDefaults, operation=PS_PROCESS_MODE.RestoreBlockDefaults
        EV_RestorePRAMBlockDefaults_PROCESS_MODE: start-on-event=RE_RestorePRAMBlockDefaults, operation=PS_PROCESS_MODE.RestorePRAMBlockDefaults
        EV_EraseBlock_PROCESS_MODE: start-on-event=RE_EraseBlock, operation=PS_PROCESS_MODE.EraseBlock
        EV_InvalidateNvBlock_PROCESS_MODE: start-on-event=RE_InvalidateNvBlock, operation=PS_PROCESS_MODE.InvalidateNvBlock
        EV_GetErrorStatus_ECS_VARIANT: start-on-event=RE_GetErrorStatus, operation=PS_ECS_VARIANT.GetErrorStatus
        EV_SetDataIndex_ECS_VARIANT: start-on-event=RE_SetDataIndex, operation=PS_ECS_VARIANT.SetDataIndex
        EV_GetDataIndex_ECS_VARIANT: start-on-event=RE_GetDataIndex, operation=PS_ECS_VARIANT.GetDataIndex
        EV_SetRamBlockStatus_ECS_VARIANT: start-on-event=RE_SetRamBlockStatus, operation=PS_ECS_VARIANT.SetRamBlockStatus
        EV_ReadBlock_ECS_VARIANT: start-on-event=RE_ReadBlock, operation=PS_ECS_VARIANT.ReadBlock
        EV_ReadPRAMBlock_ECS_VARIANT: start-on-event=RE_ReadPRAMBlock, operation=PS_ECS_VARIANT.ReadPRAMBlock
        EV_WriteBlock_ECS_VARIANT: start-on-event=RE_WriteBlock, operation=PS_ECS_VARIANT.WriteBlock
        EV_WritePRAMBlock_ECS_VARIANT: start-on-event=RE_WritePRAMBlock, operation=PS_ECS_VARIANT.WritePRAMBlock
        EV_RestoreBlockDefaults_ECS_VARIANT: start-on-event=RE_RestoreBlockDefaults, operation=PS_ECS_VARIANT.RestoreBlockDefaults
        EV_RestorePRAMBlockDefaults_ECS_VARIANT: start-on-event=RE_RestorePRAMBlockDefaults, operation=PS_ECS_VARIANT.RestorePRAMBlockDefaults
        EV_EraseBlock_ECS_VARIANT: start-on-event=RE_EraseBlock, operation=PS_ECS_VARIANT.EraseBlock
        EV_InvalidateNvBlock_ECS_VARIANT: start-on-event=RE_InvalidateNvBlock, operation=PS_ECS_VARIANT.InvalidateNvBlock
        EV_GetErrorStatus_RESERVED_1: start-on-event=RE_GetErrorStatus, operation=PS_RESERVED_1.GetErrorStatus
        EV_SetDataIndex_RESERVED_1: start-on-event=RE_SetDataIndex, operation=PS_RESERVED_1.SetDataIndex
        EV_GetDataIndex_RESERVED_1: start-on-event=RE_GetDataIndex, operation=PS_RESERVED_1.GetDataIndex
        EV_SetRamBlockStatus_RESERVED_1: start-on-event=RE_SetRamBlockStatus, operation=PS_RESERVED_1.SetRamBlockStatus
        EV_ReadBlock_RESERVED_1: start-on-event=RE_ReadBlock, operation=PS_RESERVED_1.ReadBlock
        EV_ReadPRAMBlock_RESERVED_1: start-on-event=RE_ReadPRAMBlock, operation=PS_RESERVED_1.ReadPRAMBlock
        EV_WriteBlock_RESERVED_1: start-on-event=RE_WriteBlock, operation=PS_RESERVED_1.WriteBlock
        EV_WritePRAMBlock_RESERVED_1: start-on-event=RE_WritePRAMBlock, operation=PS_RESERVED_1.WritePRAMBlock
        EV_RestoreBlockDefaults_RESERVED_1: start-on-event=RE_RestoreBlockDefaults, operation=PS_RESERVED_1.RestoreBlockDefaults
        EV_RestorePRAMBlockDefaults_RESERVED_1: start-on-event=RE_RestorePRAMBlockDefaults, operation=PS_RESERVED_1.RestorePRAMBlockDefaults
        EV_EraseBlock_RESERVED_1: start-on-event=RE_EraseBlock, operation=PS_RESERVED_1.EraseBlock
        EV_InvalidateNvBlock_RESERVED_1: start-on-event=RE_InvalidateNvBlock, operation=PS_RESERVED_1.InvalidateNvBlock
        EV_GetErrorStatus_ECS_ACC_OFFSETS: start-on-event=RE_GetErrorStatus, operation=PS_ECS_ACC_OFFSETS.GetErrorStatus
        EV_SetDataIndex_ECS_ACC_OFFSETS: start-on-event=RE_SetDataIndex, operation=PS_ECS_ACC_OFFSETS.SetDataIndex
        EV_GetDataIndex_ECS_ACC_OFFSETS: start-on-event=RE_GetDataIndex, operation=PS_ECS_ACC_OFFSETS.GetDataIndex
        EV_SetRamBlockStatus_ECS_ACC_OFFSETS: start-on-event=RE_SetRamBlockStatus, operation=PS_ECS_ACC_OFFSETS.SetRamBlockStatus
        EV_ReadBlock_ECS_ACC_OFFSETS: start-on-event=RE_ReadBlock, operation=PS_ECS_ACC_OFFSETS.ReadBlock
        EV_ReadPRAMBlock_ECS_ACC_OFFSETS: start-on-event=RE_ReadPRAMBlock, operation=PS_ECS_ACC_OFFSETS.ReadPRAMBlock
        EV_WriteBlock_ECS_ACC_OFFSETS: start-on-event=RE_WriteBlock, operation=PS_ECS_ACC_OFFSETS.WriteBlock
        EV_WritePRAMBlock_ECS_ACC_OFFSETS: start-on-event=RE_WritePRAMBlock, operation=PS_ECS_ACC_OFFSETS.WritePRAMBlock
        EV_RestoreBlockDefaults_ECS_ACC_OFFSETS: start-on-event=RE_RestoreBlockDefaults, operation=PS_ECS_ACC_OFFSETS.RestoreBlockDefaults
        EV_RestorePRAMBlockDefaults_ECS_ACC_OFFSETS: start-on-event=RE_RestorePRAMBlockDefaults, operation=PS_ECS_ACC_OFFSETS.RestorePRAMBlockDefaults
        EV_EraseBlock_ECS_ACC_OFFSETS: start-on-event=RE_EraseBlock, operation=PS_ECS_ACC_OFFSETS.EraseBlock
        EV_InvalidateNvBlock_ECS_ACC_OFFSETS: start-on-event=RE_InvalidateNvBlock, operation=PS_ECS_ACC_OFFSETS.InvalidateNvBlock
        EV_GetErrorStatus_ECS_BUCKLE_CONFIG: start-on-event=RE_GetErrorStatus, operation=PS_ECS_BUCKLE_CONFIG.GetErrorStatus
        EV_SetDataIndex_ECS_BUCKLE_CONFIG: start-on-event=RE_SetDataIndex, operation=PS_ECS_BUCKLE_CONFIG.SetDataIndex
        EV_GetDataIndex_ECS_BUCKLE_CONFIG: start-on-event=RE_GetDataIndex, operation=PS_ECS_BUCKLE_CONFIG.GetDataIndex
        EV_SetRamBlockStatus_ECS_BUCKLE_CONFIG: start-on-event=RE_SetRamBlockStatus, operation=PS_ECS_BUCKLE_CONFIG.SetRamBlockStatus
        EV_ReadBlock_ECS_BUCKLE_CONFIG: start-on-event=RE_ReadBlock, operation=PS_ECS_BUCKLE_CONFIG.ReadBlock
        EV_ReadPRAMBlock_ECS_BUCKLE_CONFIG: start-on-event=RE_ReadPRAMBlock, operation=PS_ECS_BUCKLE_CONFIG.ReadPRAMBlock
        EV_WriteBlock_ECS_BUCKLE_CONFIG: start-on-event=RE_WriteBlock, operation=PS_ECS_BUCKLE_CONFIG.WriteBlock
        EV_WritePRAMBlock_ECS_BUCKLE_CONFIG: start-on-event=RE_WritePRAMBlock, operation=PS_ECS_BUCKLE_CONFIG.WritePRAMBlock
        EV_RestoreBlockDefaults_ECS_BUCKLE_CONFIG: start-on-event=RE_RestoreBlockDefaults, operation=PS_ECS_BUCKLE_CONFIG.RestoreBlockDefaults
        EV_RestorePRAMBlockDefaults_ECS_BUCKLE_CONFIG: start-on-event=RE_RestorePRAMBlockDefaults, operation=PS_ECS_BUCKLE_CONFIG.RestorePRAMBlockDefaults
        EV_EraseBlock_ECS_BUCKLE_CONFIG: start-on-event=RE_EraseBlock, operation=PS_ECS_BUCKLE_CONFIG.EraseBlock
        EV_InvalidateNvBlock_ECS_BUCKLE_CONFIG: start-on-event=RE_InvalidateNvBlock, operation=PS_ECS_BUCKLE_CONFIG.InvalidateNvBlock
        EV_GetErrorStatus_ECS_CODING_VARIANT: start-on-event=RE_GetErrorStatus, operation=PS_ECS_CODING_VARIANT.GetErrorStatus
        EV_SetDataIndex_ECS_CODING_VARIANT: start-on-event=RE_SetDataIndex, operation=PS_ECS_CODING_VARIANT.SetDataIndex
        EV_GetDataIndex_ECS_CODING_VARIANT: start-on-event=RE_GetDataIndex, operation=PS_ECS_CODING_VARIANT.GetDataIndex
        EV_SetRamBlockStatus_ECS_CODING_VARIANT: start-on-event=RE_SetRamBlockStatus, operation=PS_ECS_CODING_VARIANT.SetRamBlockStatus
        EV_ReadBlock_ECS_CODING_VARIANT: start-on-event=RE_ReadBlock, operation=PS_ECS_CODING_VARIANT.ReadBlock
        EV_ReadPRAMBlock_ECS_CODING_VARIANT: start-on-event=RE_ReadPRAMBlock, operation=PS_ECS_CODING_VARIANT.ReadPRAMBlock
        EV_WriteBlock_ECS_CODING_VARIANT: start-on-event=RE_WriteBlock, operation=PS_ECS_CODING_VARIANT.WriteBlock
        EV_WritePRAMBlock_ECS_CODING_VARIANT: start-on-event=RE_WritePRAMBlock, operation=PS_ECS_CODING_VARIANT.WritePRAMBlock
        EV_RestoreBlockDefaults_ECS_CODING_VARIANT: start-on-event=RE_RestoreBlockDefaults, operation=PS_ECS_CODING_VARIANT.RestoreBlockDefaults
        EV_RestorePRAMBlockDefaults_ECS_CODING_VARIANT: start-on-event=RE_RestorePRAMBlockDefaults, operation=PS_ECS_CODING_VARIANT.RestorePRAMBlockDefaults
        EV_EraseBlock_ECS_CODING_VARIANT: start-on-event=RE_EraseBlock, operation=PS_ECS_CODING_VARIANT.EraseBlock
        EV_InvalidateNvBlock_ECS_CODING_VARIANT: start-on-event=RE_InvalidateNvBlock, operation=PS_ECS_CODING_VARIANT.InvalidateNvBlock
        EV_GetErrorStatus_ECS_ACC_LOWPASS: start-on-event=RE_GetErrorStatus, operation=PS_ECS_ACC_LOWPASS.GetErrorStatus
        EV_SetDataIndex_ECS_ACC_LOWPASS: start-on-event=RE_SetDataIndex, operation=PS_ECS_ACC_LOWPASS.SetDataIndex
        EV_GetDataIndex_ECS_ACC_LOWPASS: start-on-event=RE_GetDataIndex, operation=PS_ECS_ACC_LOWPASS.GetDataIndex
        EV_SetRamBlockStatus_ECS_ACC_LOWPASS: start-on-event=RE_SetRamBlockStatus, operation=PS_ECS_ACC_LOWPASS.SetRamBlockStatus
        EV_ReadBlock_ECS_ACC_LOWPASS: start-on-event=RE_ReadBlock, operation=PS_ECS_ACC_LOWPASS.ReadBlock
        EV_ReadPRAMBlock_ECS_ACC_LOWPASS: start-on-event=RE_ReadPRAMBlock, operation=PS_ECS_ACC_LOWPASS.ReadPRAMBlock
        EV_WriteBlock_ECS_ACC_LOWPASS: start-on-event=RE_WriteBlock, operation=PS_ECS_ACC_LOWPASS.WriteBlock
        EV_WritePRAMBlock_ECS_ACC_LOWPASS: start-on-event=RE_WritePRAMBlock, operation=PS_ECS_ACC_LOWPASS.WritePRAMBlock
        EV_RestoreBlockDefaults_ECS_ACC_LOWPASS: start-on-event=RE_RestoreBlockDefaults, operation=PS_ECS_ACC_LOWPASS.RestoreBlockDefaults
        EV_RestorePRAMBlockDefaults_ECS_ACC_LOWPASS: start-on-event=RE_RestorePRAMBlockDefaults, operation=PS_ECS_ACC_LOWPASS.RestorePRAMBlockDefaults
        EV_EraseBlock_ECS_ACC_LOWPASS: start-on-event=RE_EraseBlock, operation=PS_ECS_ACC_LOWPASS.EraseBlock
        EV_InvalidateNvBlock_ECS_ACC_LOWPASS: start-on-event=RE_InvalidateNvBlock, operation=PS_ECS_ACC_LOWPASS.InvalidateNvBlock
        EV_GetErrorStatus_SBS_LAST_STATE: start-on-event=RE_GetErrorStatus, operation=PS_SBS_LAST_STATE.GetErrorStatus
        EV_SetDataIndex_SBS_LAST_STATE: start-on-event=RE_SetDataIndex, operation=PS_SBS_LAST_STATE.SetDataIndex
        EV_GetDataIndex_SBS_LAST_STATE: start-on-event=RE_GetDataIndex, operation=PS_SBS_LAST_STATE.GetDataIndex
        EV_SetRamBlockStatus_SBS_LAST_STATE: start-on-event=RE_SetRamBlockStatus, operation=PS_SBS_LAST_STATE.SetRamBlockStatus
        EV_ReadBlock_SBS_LAST_STATE: start-on-event=RE_ReadBlock, operation=PS_SBS_LAST_STATE.ReadBlock
        EV_ReadPRAMBlock_SBS_LAST_STATE: start-on-event=RE_ReadPRAMBlock, operation=PS_SBS_LAST_STATE.ReadPRAMBlock
        EV_WriteBlock_SBS_LAST_STATE: start-on-event=RE_WriteBlock, operation=PS_SBS_LAST_STATE.WriteBlock
        EV_WritePRAMBlock_SBS_LAST_STATE: start-on-event=RE_WritePRAMBlock, operation=PS_SBS_LAST_STATE.WritePRAMBlock
        EV_RestoreBlockDefaults_SBS_LAST_STATE: start-on-event=RE_RestoreBlockDefaults, operation=PS_SBS_LAST_STATE.RestoreBlockDefaults
        EV_RestorePRAMBlockDefaults_SBS_LAST_STATE: start-on-event=RE_RestorePRAMBlockDefaults, operation=PS_SBS_LAST_STATE.RestorePRAMBlockDefaults
        EV_EraseBlock_SBS_LAST_STATE: start-on-event=RE_EraseBlock, operation=PS_SBS_LAST_STATE.EraseBlock
        EV_InvalidateNvBlock_SBS_LAST_STATE: start-on-event=RE_InvalidateNvBlock, operation=PS_SBS_LAST_STATE.InvalidateNvBlock
        EV_GetErrorStatus_ECS_ALGO_OUTPUT_DELAY: start-on-event=RE_GetErrorStatus, operation=PS_ECS_ALGO_OUTPUT_DELAY.GetErrorStatus
        EV_SetDataIndex_ECS_ALGO_OUTPUT_DELAY: start-on-event=RE_SetDataIndex, operation=PS_ECS_ALGO_OUTPUT_DELAY.SetDataIndex
        EV_GetDataIndex_ECS_ALGO_OUTPUT_DELAY: start-on-event=RE_GetDataIndex, operation=PS_ECS_ALGO_OUTPUT_DELAY.GetDataIndex
        EV_SetRamBlockStatus_ECS_ALGO_OUTPUT_DELAY: start-on-event=RE_SetRamBlockStatus, operation=PS_ECS_ALGO_OUTPUT_DELAY.SetRamBlockStatus
        EV_ReadBlock_ECS_ALGO_OUTPUT_DELAY: start-on-event=RE_ReadBlock, operation=PS_ECS_ALGO_OUTPUT_DELAY.ReadBlock
        EV_ReadPRAMBlock_ECS_ALGO_OUTPUT_DELAY: start-on-event=RE_ReadPRAMBlock, operation=PS_ECS_ALGO_OUTPUT_DELAY.ReadPRAMBlock
        EV_WriteBlock_ECS_ALGO_OUTPUT_DELAY: start-on-event=RE_WriteBlock, operation=PS_ECS_ALGO_OUTPUT_DELAY.WriteBlock
        EV_WritePRAMBlock_ECS_ALGO_OUTPUT_DELAY: start-on-event=RE_WritePRAMBlock, operation=PS_ECS_ALGO_OUTPUT_DELAY.WritePRAMBlock
        EV_RestoreBlockDefaults_ECS_ALGO_OUTPUT_DELAY: start-on-event=RE_RestoreBlockDefaults, operation=PS_ECS_ALGO_OUTPUT_DELAY.RestoreBlockDefaults
        EV_RestorePRAMBlockDefaults_ECS_ALGO_OUTPUT_DELAY: start-on-event=RE_RestorePRAMBlockDefaults, operation=PS_ECS_ALGO_OUTPUT_DELAY.RestorePRAMBlockDefaults
        EV_EraseBlock_ECS_ALGO_OUTPUT_DELAY: start-on-event=RE_EraseBlock, operation=PS_ECS_ALGO_OUTPUT_DELAY.EraseBlock
        EV_InvalidateNvBlock_ECS_ALGO_OUTPUT_DELAY: start-on-event=RE_InvalidateNvBlock, operation=PS_ECS_ALGO_OUTPUT_DELAY.InvalidateNvBlock
        EV_GetErrorStatus_ECS_SENSITIVITY_LUT: start-on-event=RE_GetErrorStatus, operation=PS_ECS_SENSITIVITY_LUT.GetErrorStatus
        EV_SetDataIndex_ECS_SENSITIVITY_LUT: start-on-event=RE_SetDataIndex, operation=PS_ECS_SENSITIVITY_LUT.SetDataIndex
        EV_GetDataIndex_ECS_SENSITIVITY_LUT: start-on-event=RE_GetDataIndex, operation=PS_ECS_SENSITIVITY_LUT.GetDataIndex
        EV_SetRamBlockStatus_ECS_SENSITIVITY_LUT: start-on-event=RE_SetRamBlockStatus, operation=PS_ECS_SENSITIVITY_LUT.SetRamBlockStatus
        EV_ReadBlock_ECS_SENSITIVITY_LUT: start-on-event=RE_ReadBlock, operation=PS_ECS_SENSITIVITY_LUT.ReadBlock
        EV_ReadPRAMBlock_ECS_SENSITIVITY_LUT: start-on-event=RE_ReadPRAMBlock, operation=PS_ECS_SENSITIVITY_LUT.ReadPRAMBlock
        EV_WriteBlock_ECS_SENSITIVITY_LUT: start-on-event=RE_WriteBlock, operation=PS_ECS_SENSITIVITY_LUT.WriteBlock
        EV_WritePRAMBlock_ECS_SENSITIVITY_LUT: start-on-event=RE_WritePRAMBlock, operation=PS_ECS_SENSITIVITY_LUT.WritePRAMBlock
        EV_RestoreBlockDefaults_ECS_SENSITIVITY_LUT: start-on-event=RE_RestoreBlockDefaults, operation=PS_ECS_SENSITIVITY_LUT.RestoreBlockDefaults
        EV_RestorePRAMBlockDefaults_ECS_SENSITIVITY_LUT: start-on-event=RE_RestorePRAMBlockDefaults, operation=PS_ECS_SENSITIVITY_LUT.RestorePRAMBlockDefaults
        EV_EraseBlock_ECS_SENSITIVITY_LUT: start-on-event=RE_EraseBlock, operation=PS_ECS_SENSITIVITY_LUT.EraseBlock
        EV_InvalidateNvBlock_ECS_SENSITIVITY_LUT: start-on-event=RE_InvalidateNvBlock, operation=PS_ECS_SENSITIVITY_LUT.InvalidateNvBlock
        EV_GetErrorStatus_ECS_SENSITIVITY_OPT: start-on-event=RE_GetErrorStatus, operation=PS_ECS_SENSITIVITY_OPT.GetErrorStatus
        EV_SetDataIndex_ECS_SENSITIVITY_OPT: start-on-event=RE_SetDataIndex, operation=PS_ECS_SENSITIVITY_OPT.SetDataIndex
        EV_GetDataIndex_ECS_SENSITIVITY_OPT: start-on-event=RE_GetDataIndex, operation=PS_ECS_SENSITIVITY_OPT.GetDataIndex
        EV_SetRamBlockStatus_ECS_SENSITIVITY_OPT: start-on-event=RE_SetRamBlockStatus, operation=PS_ECS_SENSITIVITY_OPT.SetRamBlockStatus
        EV_ReadBlock_ECS_SENSITIVITY_OPT: start-on-event=RE_ReadBlock, operation=PS_ECS_SENSITIVITY_OPT.ReadBlock
        EV_ReadPRAMBlock_ECS_SENSITIVITY_OPT: start-on-event=RE_ReadPRAMBlock, operation=PS_ECS_SENSITIVITY_OPT.ReadPRAMBlock
        EV_WriteBlock_ECS_SENSITIVITY_OPT: start-on-event=RE_WriteBlock, operation=PS_ECS_SENSITIVITY_OPT.WriteBlock
        EV_WritePRAMBlock_ECS_SENSITIVITY_OPT: start-on-event=RE_WritePRAMBlock, operation=PS_ECS_SENSITIVITY_OPT.WritePRAMBlock
        EV_RestoreBlockDefaults_ECS_SENSITIVITY_OPT: start-on-event=RE_RestoreBlockDefaults, operation=PS_ECS_SENSITIVITY_OPT.RestoreBlockDefaults
        EV_RestorePRAMBlockDefaults_ECS_SENSITIVITY_OPT: start-on-event=RE_RestorePRAMBlockDefaults, operation=PS_ECS_SENSITIVITY_OPT.RestorePRAMBlockDefaults
        EV_EraseBlock_ECS_SENSITIVITY_OPT: start-on-event=RE_EraseBlock, operation=PS_ECS_SENSITIVITY_OPT.EraseBlock
        EV_InvalidateNvBlock_ECS_SENSITIVITY_OPT: start-on-event=RE_InvalidateNvBlock, operation=PS_ECS_SENSITIVITY_OPT.InvalidateNvBlock
        EV_GetErrorStatus_ECU_TEMP_CALIBRATION: start-on-event=RE_GetErrorStatus, operation=PS_ECU_TEMP_CALIBRATION.GetErrorStatus
        EV_SetDataIndex_ECU_TEMP_CALIBRATION: start-on-event=RE_SetDataIndex, operation=PS_ECU_TEMP_CALIBRATION.SetDataIndex
        EV_GetDataIndex_ECU_TEMP_CALIBRATION: start-on-event=RE_GetDataIndex, operation=PS_ECU_TEMP_CALIBRATION.GetDataIndex
        EV_SetRamBlockStatus_ECU_TEMP_CALIBRATION: start-on-event=RE_SetRamBlockStatus, operation=PS_ECU_TEMP_CALIBRATION.SetRamBlockStatus
        EV_ReadBlock_ECU_TEMP_CALIBRATION: start-on-event=RE_ReadBlock, operation=PS_ECU_TEMP_CALIBRATION.ReadBlock
        EV_ReadPRAMBlock_ECU_TEMP_CALIBRATION: start-on-event=RE_ReadPRAMBlock, operation=PS_ECU_TEMP_CALIBRATION.ReadPRAMBlock
        EV_WriteBlock_ECU_TEMP_CALIBRATION: start-on-event=RE_WriteBlock, operation=PS_ECU_TEMP_CALIBRATION.WriteBlock
        EV_WritePRAMBlock_ECU_TEMP_CALIBRATION: start-on-event=RE_WritePRAMBlock, operation=PS_ECU_TEMP_CALIBRATION.WritePRAMBlock
        EV_RestoreBlockDefaults_ECU_TEMP_CALIBRATION: start-on-event=RE_RestoreBlockDefaults, operation=PS_ECU_TEMP_CALIBRATION.RestoreBlockDefaults
        EV_RestorePRAMBlockDefaults_ECU_TEMP_CALIBRATION: start-on-event=RE_RestorePRAMBlockDefaults, operation=PS_ECU_TEMP_CALIBRATION.RestorePRAMBlockDefaults
        EV_EraseBlock_ECU_TEMP_CALIBRATION: start-on-event=RE_EraseBlock, operation=PS_ECU_TEMP_CALIBRATION.EraseBlock
        EV_InvalidateNvBlock_ECU_TEMP_CALIBRATION: start-on-event=RE_InvalidateNvBlock, operation=PS_ECU_TEMP_CALIBRATION.InvalidateNvBlock
        EV_GetErrorStatus_ALV_NVM_VERSION: start-on-event=RE_GetErrorStatus, operation=PS_ALV_NVM_VERSION.GetErrorStatus
        EV_SetDataIndex_ALV_NVM_VERSION: start-on-event=RE_SetDataIndex, operation=PS_ALV_NVM_VERSION.SetDataIndex
        EV_GetDataIndex_ALV_NVM_VERSION: start-on-event=RE_GetDataIndex, operation=PS_ALV_NVM_VERSION.GetDataIndex
        EV_SetRamBlockStatus_ALV_NVM_VERSION: start-on-event=RE_SetRamBlockStatus, operation=PS_ALV_NVM_VERSION.SetRamBlockStatus
        EV_ReadBlock_ALV_NVM_VERSION: start-on-event=RE_ReadBlock, operation=PS_ALV_NVM_VERSION.ReadBlock
        EV_ReadPRAMBlock_ALV_NVM_VERSION: start-on-event=RE_ReadPRAMBlock, operation=PS_ALV_NVM_VERSION.ReadPRAMBlock
        EV_WriteBlock_ALV_NVM_VERSION: start-on-event=RE_WriteBlock, operation=PS_ALV_NVM_VERSION.WriteBlock
        EV_WritePRAMBlock_ALV_NVM_VERSION: start-on-event=RE_WritePRAMBlock, operation=PS_ALV_NVM_VERSION.WritePRAMBlock
        EV_RestoreBlockDefaults_ALV_NVM_VERSION: start-on-event=RE_RestoreBlockDefaults, operation=PS_ALV_NVM_VERSION.RestoreBlockDefaults
        EV_RestorePRAMBlockDefaults_ALV_NVM_VERSION: start-on-event=RE_RestorePRAMBlockDefaults, operation=PS_ALV_NVM_VERSION.RestorePRAMBlockDefaults
        EV_EraseBlock_ALV_NVM_VERSION: start-on-event=RE_EraseBlock, operation=PS_ALV_NVM_VERSION.EraseBlock
        EV_InvalidateNvBlock_ALV_NVM_VERSION: start-on-event=RE_InvalidateNvBlock, operation=PS_ALV_NVM_VERSION.InvalidateNvBlock
        EV_GetErrorStatus_MEAS_FRAME_RAM_ADDR_CFG: start-on-event=RE_GetErrorStatus, operation=PS_MEAS_FRAME_RAM_ADDR_CFG.GetErrorStatus
        EV_SetDataIndex_MEAS_FRAME_RAM_ADDR_CFG: start-on-event=RE_SetDataIndex, operation=PS_MEAS_FRAME_RAM_ADDR_CFG.SetDataIndex
        EV_GetDataIndex_MEAS_FRAME_RAM_ADDR_CFG: start-on-event=RE_GetDataIndex, operation=PS_MEAS_FRAME_RAM_ADDR_CFG.GetDataIndex
        EV_SetRamBlockStatus_MEAS_FRAME_RAM_ADDR_CFG: start-on-event=RE_SetRamBlockStatus, operation=PS_MEAS_FRAME_RAM_ADDR_CFG.SetRamBlockStatus
        EV_ReadBlock_MEAS_FRAME_RAM_ADDR_CFG: start-on-event=RE_ReadBlock, operation=PS_MEAS_FRAME_RAM_ADDR_CFG.ReadBlock
        EV_ReadPRAMBlock_MEAS_FRAME_RAM_ADDR_CFG: start-on-event=RE_ReadPRAMBlock, operation=PS_MEAS_FRAME_RAM_ADDR_CFG.ReadPRAMBlock
        EV_WriteBlock_MEAS_FRAME_RAM_ADDR_CFG: start-on-event=RE_WriteBlock, operation=PS_MEAS_FRAME_RAM_ADDR_CFG.WriteBlock
        EV_WritePRAMBlock_MEAS_FRAME_RAM_ADDR_CFG: start-on-event=RE_WritePRAMBlock, operation=PS_MEAS_FRAME_RAM_ADDR_CFG.WritePRAMBlock
        EV_RestoreBlockDefaults_MEAS_FRAME_RAM_ADDR_CFG: start-on-event=RE_RestoreBlockDefaults, operation=PS_MEAS_FRAME_RAM_ADDR_CFG.RestoreBlockDefaults
        EV_RestorePRAMBlockDefaults_MEAS_FRAME_RAM_ADDR_CFG: start-on-event=RE_RestorePRAMBlockDefaults, operation=PS_MEAS_FRAME_RAM_ADDR_CFG.RestorePRAMBlockDefaults
        EV_EraseBlock_MEAS_FRAME_RAM_ADDR_CFG: start-on-event=RE_EraseBlock, operation=PS_MEAS_FRAME_RAM_ADDR_CFG.EraseBlock
        EV_InvalidateNvBlock_MEAS_FRAME_RAM_ADDR_CFG: start-on-event=RE_InvalidateNvBlock, operation=PS_MEAS_FRAME_RAM_ADDR_CFG.InvalidateNvBlock
        EV_GetErrorStatus_ACC_AXIS_ANGLE_CALIBRATION: start-on-event=RE_GetErrorStatus, operation=PS_ACC_AXIS_ANGLE_CALIBRATION.GetErrorStatus
        EV_SetDataIndex_ACC_AXIS_ANGLE_CALIBRATION: start-on-event=RE_SetDataIndex, operation=PS_ACC_AXIS_ANGLE_CALIBRATION.SetDataIndex
        EV_GetDataIndex_ACC_AXIS_ANGLE_CALIBRATION: start-on-event=RE_GetDataIndex, operation=PS_ACC_AXIS_ANGLE_CALIBRATION.GetDataIndex
        EV_SetRamBlockStatus_ACC_AXIS_ANGLE_CALIBRATION: start-on-event=RE_SetRamBlockStatus, operation=PS_ACC_AXIS_ANGLE_CALIBRATION.SetRamBlockStatus
        EV_ReadBlock_ACC_AXIS_ANGLE_CALIBRATION: start-on-event=RE_ReadBlock, operation=PS_ACC_AXIS_ANGLE_CALIBRATION.ReadBlock
        EV_ReadPRAMBlock_ACC_AXIS_ANGLE_CALIBRATION: start-on-event=RE_ReadPRAMBlock, operation=PS_ACC_AXIS_ANGLE_CALIBRATION.ReadPRAMBlock
        EV_WriteBlock_ACC_AXIS_ANGLE_CALIBRATION: start-on-event=RE_WriteBlock, operation=PS_ACC_AXIS_ANGLE_CALIBRATION.WriteBlock
        EV_WritePRAMBlock_ACC_AXIS_ANGLE_CALIBRATION: start-on-event=RE_WritePRAMBlock, operation=PS_ACC_AXIS_ANGLE_CALIBRATION.WritePRAMBlock
        EV_RestoreBlockDefaults_ACC_AXIS_ANGLE_CALIBRATION: start-on-event=RE_RestoreBlockDefaults, operation=PS_ACC_AXIS_ANGLE_CALIBRATION.RestoreBlockDefaults
        EV_RestorePRAMBlockDefaults_ACC_AXIS_ANGLE_CALIBRATION: start-on-event=RE_RestorePRAMBlockDefaults, operation=PS_ACC_AXIS_ANGLE_CALIBRATION.RestorePRAMBlockDefaults
        EV_EraseBlock_ACC_AXIS_ANGLE_CALIBRATION: start-on-event=RE_EraseBlock, operation=PS_ACC_AXIS_ANGLE_CALIBRATION.EraseBlock
        EV_InvalidateNvBlock_ACC_AXIS_ANGLE_CALIBRATION: start-on-event=RE_InvalidateNvBlock, operation=PS_ACC_AXIS_ANGLE_CALIBRATION.InvalidateNvBlock
        EV_GetErrorStatus_EOL_COUNTERS: start-on-event=RE_GetErrorStatus, operation=PS_EOL_COUNTERS.GetErrorStatus
        EV_SetDataIndex_EOL_COUNTERS: start-on-event=RE_SetDataIndex, operation=PS_EOL_COUNTERS.SetDataIndex
        EV_GetDataIndex_EOL_COUNTERS: start-on-event=RE_GetDataIndex, operation=PS_EOL_COUNTERS.GetDataIndex
        EV_SetRamBlockStatus_EOL_COUNTERS: start-on-event=RE_SetRamBlockStatus, operation=PS_EOL_COUNTERS.SetRamBlockStatus
        EV_ReadBlock_EOL_COUNTERS: start-on-event=RE_ReadBlock, operation=PS_EOL_COUNTERS.ReadBlock
        EV_ReadPRAMBlock_EOL_COUNTERS: start-on-event=RE_ReadPRAMBlock, operation=PS_EOL_COUNTERS.ReadPRAMBlock
        EV_WriteBlock_EOL_COUNTERS: start-on-event=RE_WriteBlock, operation=PS_EOL_COUNTERS.WriteBlock
        EV_WritePRAMBlock_EOL_COUNTERS: start-on-event=RE_WritePRAMBlock, operation=PS_EOL_COUNTERS.WritePRAMBlock
        EV_RestoreBlockDefaults_EOL_COUNTERS: start-on-event=RE_RestoreBlockDefaults, operation=PS_EOL_COUNTERS.RestoreBlockDefaults
        EV_RestorePRAMBlockDefaults_EOL_COUNTERS: start-on-event=RE_RestorePRAMBlockDefaults, operation=PS_EOL_COUNTERS.RestorePRAMBlockDefaults
        EV_EraseBlock_EOL_COUNTERS: start-on-event=RE_EraseBlock, operation=PS_EOL_COUNTERS.EraseBlock
        EV_InvalidateNvBlock_EOL_COUNTERS: start-on-event=RE_InvalidateNvBlock, operation=PS_EOL_COUNTERS.InvalidateNvBlock
        EV_GetErrorStatus_RESERVED_4: start-on-event=RE_GetErrorStatus, operation=PS_RESERVED_4.GetErrorStatus
        EV_SetDataIndex_RESERVED_4: start-on-event=RE_SetDataIndex, operation=PS_RESERVED_4.SetDataIndex
        EV_GetDataIndex_RESERVED_4: start-on-event=RE_GetDataIndex, operation=PS_RESERVED_4.GetDataIndex
        EV_SetRamBlockStatus_RESERVED_4: start-on-event=RE_SetRamBlockStatus, operation=PS_RESERVED_4.SetRamBlockStatus
        EV_ReadBlock_RESERVED_4: start-on-event=RE_ReadBlock, operation=PS_RESERVED_4.ReadBlock
        EV_ReadPRAMBlock_RESERVED_4: start-on-event=RE_ReadPRAMBlock, operation=PS_RESERVED_4.ReadPRAMBlock
        EV_WriteBlock_RESERVED_4: start-on-event=RE_WriteBlock, operation=PS_RESERVED_4.WriteBlock
        EV_WritePRAMBlock_RESERVED_4: start-on-event=RE_WritePRAMBlock, operation=PS_RESERVED_4.WritePRAMBlock
        EV_RestoreBlockDefaults_RESERVED_4: start-on-event=RE_RestoreBlockDefaults, operation=PS_RESERVED_4.RestoreBlockDefaults
        EV_RestorePRAMBlockDefaults_RESERVED_4: start-on-event=RE_RestorePRAMBlockDefaults, operation=PS_RESERVED_4.RestorePRAMBlockDefaults
        EV_EraseBlock_RESERVED_4: start-on-event=RE_EraseBlock, operation=PS_RESERVED_4.EraseBlock
        EV_InvalidateNvBlock_RESERVED_4: start-on-event=RE_InvalidateNvBlock, operation=PS_RESERVED_4.InvalidateNvBlock
        EV_GetErrorStatus_AUTOTEST_PARAM: start-on-event=RE_GetErrorStatus, operation=PS_AUTOTEST_PARAM.GetErrorStatus
        EV_SetDataIndex_AUTOTEST_PARAM: start-on-event=RE_SetDataIndex, operation=PS_AUTOTEST_PARAM.SetDataIndex
        EV_GetDataIndex_AUTOTEST_PARAM: start-on-event=RE_GetDataIndex, operation=PS_AUTOTEST_PARAM.GetDataIndex
        EV_SetRamBlockStatus_AUTOTEST_PARAM: start-on-event=RE_SetRamBlockStatus, operation=PS_AUTOTEST_PARAM.SetRamBlockStatus
        EV_ReadBlock_AUTOTEST_PARAM: start-on-event=RE_ReadBlock, operation=PS_AUTOTEST_PARAM.ReadBlock
        EV_ReadPRAMBlock_AUTOTEST_PARAM: start-on-event=RE_ReadPRAMBlock, operation=PS_AUTOTEST_PARAM.ReadPRAMBlock
        EV_WriteBlock_AUTOTEST_PARAM: start-on-event=RE_WriteBlock, operation=PS_AUTOTEST_PARAM.WriteBlock
        EV_WritePRAMBlock_AUTOTEST_PARAM: start-on-event=RE_WritePRAMBlock, operation=PS_AUTOTEST_PARAM.WritePRAMBlock
        EV_RestoreBlockDefaults_AUTOTEST_PARAM: start-on-event=RE_RestoreBlockDefaults, operation=PS_AUTOTEST_PARAM.RestoreBlockDefaults
        EV_RestorePRAMBlockDefaults_AUTOTEST_PARAM: start-on-event=RE_RestorePRAMBlockDefaults, operation=PS_AUTOTEST_PARAM.RestorePRAMBlockDefaults
        EV_EraseBlock_AUTOTEST_PARAM: start-on-event=RE_EraseBlock, operation=PS_AUTOTEST_PARAM.EraseBlock
        EV_InvalidateNvBlock_AUTOTEST_PARAM: start-on-event=RE_InvalidateNvBlock, operation=PS_AUTOTEST_PARAM.InvalidateNvBlock
        EV_GetErrorStatus_PHYS_MEASUREMENTS: start-on-event=RE_GetErrorStatus, operation=PS_PHYS_MEASUREMENTS.GetErrorStatus
        EV_SetDataIndex_PHYS_MEASUREMENTS: start-on-event=RE_SetDataIndex, operation=PS_PHYS_MEASUREMENTS.SetDataIndex
        EV_GetDataIndex_PHYS_MEASUREMENTS: start-on-event=RE_GetDataIndex, operation=PS_PHYS_MEASUREMENTS.GetDataIndex
        EV_SetRamBlockStatus_PHYS_MEASUREMENTS: start-on-event=RE_SetRamBlockStatus, operation=PS_PHYS_MEASUREMENTS.SetRamBlockStatus
        EV_ReadBlock_PHYS_MEASUREMENTS: start-on-event=RE_ReadBlock, operation=PS_PHYS_MEASUREMENTS.ReadBlock
        EV_ReadPRAMBlock_PHYS_MEASUREMENTS: start-on-event=RE_ReadPRAMBlock, operation=PS_PHYS_MEASUREMENTS.ReadPRAMBlock
        EV_WriteBlock_PHYS_MEASUREMENTS: start-on-event=RE_WriteBlock, operation=PS_PHYS_MEASUREMENTS.WriteBlock
        EV_WritePRAMBlock_PHYS_MEASUREMENTS: start-on-event=RE_WritePRAMBlock, operation=PS_PHYS_MEASUREMENTS.WritePRAMBlock
        EV_RestoreBlockDefaults_PHYS_MEASUREMENTS: start-on-event=RE_RestoreBlockDefaults, operation=PS_PHYS_MEASUREMENTS.RestoreBlockDefaults
        EV_RestorePRAMBlockDefaults_PHYS_MEASUREMENTS: start-on-event=RE_RestorePRAMBlockDefaults, operation=PS_PHYS_MEASUREMENTS.RestorePRAMBlockDefaults
        EV_EraseBlock_PHYS_MEASUREMENTS: start-on-event=RE_EraseBlock, operation=PS_PHYS_MEASUREMENTS.EraseBlock
        EV_InvalidateNvBlock_PHYS_MEASUREMENTS: start-on-event=RE_InvalidateNvBlock, operation=PS_PHYS_MEASUREMENTS.InvalidateNvBlock
        EV_GetErrorStatus_SOLENOID_PARAM: start-on-event=RE_GetErrorStatus, operation=PS_SOLENOID_PARAM.GetErrorStatus
        EV_SetDataIndex_SOLENOID_PARAM: start-on-event=RE_SetDataIndex, operation=PS_SOLENOID_PARAM.SetDataIndex
        EV_GetDataIndex_SOLENOID_PARAM: start-on-event=RE_GetDataIndex, operation=PS_SOLENOID_PARAM.GetDataIndex
        EV_SetRamBlockStatus_SOLENOID_PARAM: start-on-event=RE_SetRamBlockStatus, operation=PS_SOLENOID_PARAM.SetRamBlockStatus
        EV_ReadBlock_SOLENOID_PARAM: start-on-event=RE_ReadBlock, operation=PS_SOLENOID_PARAM.ReadBlock
        EV_ReadPRAMBlock_SOLENOID_PARAM: start-on-event=RE_ReadPRAMBlock, operation=PS_SOLENOID_PARAM.ReadPRAMBlock
        EV_WriteBlock_SOLENOID_PARAM: start-on-event=RE_WriteBlock, operation=PS_SOLENOID_PARAM.WriteBlock
        EV_WritePRAMBlock_SOLENOID_PARAM: start-on-event=RE_WritePRAMBlock, operation=PS_SOLENOID_PARAM.WritePRAMBlock
        EV_RestoreBlockDefaults_SOLENOID_PARAM: start-on-event=RE_RestoreBlockDefaults, operation=PS_SOLENOID_PARAM.RestoreBlockDefaults
        EV_RestorePRAMBlockDefaults_SOLENOID_PARAM: start-on-event=RE_RestorePRAMBlockDefaults, operation=PS_SOLENOID_PARAM.RestorePRAMBlockDefaults
        EV_EraseBlock_SOLENOID_PARAM: start-on-event=RE_EraseBlock, operation=PS_SOLENOID_PARAM.EraseBlock
        EV_InvalidateNvBlock_SOLENOID_PARAM: start-on-event=RE_InvalidateNvBlock, operation=PS_SOLENOID_PARAM.InvalidateNvBlock
        EV_GetErrorStatus_ECS_PROFILES: start-on-event=RE_GetErrorStatus, operation=PS_ECS_PROFILES.GetErrorStatus
        EV_SetDataIndex_ECS_PROFILES: start-on-event=RE_SetDataIndex, operation=PS_ECS_PROFILES.SetDataIndex
        EV_GetDataIndex_ECS_PROFILES: start-on-event=RE_GetDataIndex, operation=PS_ECS_PROFILES.GetDataIndex
        EV_SetRamBlockStatus_ECS_PROFILES: start-on-event=RE_SetRamBlockStatus, operation=PS_ECS_PROFILES.SetRamBlockStatus
        EV_ReadBlock_ECS_PROFILES: start-on-event=RE_ReadBlock, operation=PS_ECS_PROFILES.ReadBlock
        EV_ReadPRAMBlock_ECS_PROFILES: start-on-event=RE_ReadPRAMBlock, operation=PS_ECS_PROFILES.ReadPRAMBlock
        EV_WriteBlock_ECS_PROFILES: start-on-event=RE_WriteBlock, operation=PS_ECS_PROFILES.WriteBlock
        EV_WritePRAMBlock_ECS_PROFILES: start-on-event=RE_WritePRAMBlock, operation=PS_ECS_PROFILES.WritePRAMBlock
        EV_RestoreBlockDefaults_ECS_PROFILES: start-on-event=RE_RestoreBlockDefaults, operation=PS_ECS_PROFILES.RestoreBlockDefaults
        EV_RestorePRAMBlockDefaults_ECS_PROFILES: start-on-event=RE_RestorePRAMBlockDefaults, operation=PS_ECS_PROFILES.RestorePRAMBlockDefaults
        EV_EraseBlock_ECS_PROFILES: start-on-event=RE_EraseBlock, operation=PS_ECS_PROFILES.EraseBlock
        EV_InvalidateNvBlock_ECS_PROFILES: start-on-event=RE_InvalidateNvBlock, operation=PS_ECS_PROFILES.InvalidateNvBlock
        EV_GetErrorStatus_ECU_STATE_TIMING_PARAMETERS: start-on-event=RE_GetErrorStatus, operation=PS_ECU_STATE_TIMING_PARAMETERS.GetErrorStatus
        EV_SetDataIndex_ECU_STATE_TIMING_PARAMETERS: start-on-event=RE_SetDataIndex, operation=PS_ECU_STATE_TIMING_PARAMETERS.SetDataIndex
        EV_GetDataIndex_ECU_STATE_TIMING_PARAMETERS: start-on-event=RE_GetDataIndex, operation=PS_ECU_STATE_TIMING_PARAMETERS.GetDataIndex
        EV_SetRamBlockStatus_ECU_STATE_TIMING_PARAMETERS: start-on-event=RE_SetRamBlockStatus, operation=PS_ECU_STATE_TIMING_PARAMETERS.SetRamBlockStatus
        EV_ReadBlock_ECU_STATE_TIMING_PARAMETERS: start-on-event=RE_ReadBlock, operation=PS_ECU_STATE_TIMING_PARAMETERS.ReadBlock
        EV_ReadPRAMBlock_ECU_STATE_TIMING_PARAMETERS: start-on-event=RE_ReadPRAMBlock, operation=PS_ECU_STATE_TIMING_PARAMETERS.ReadPRAMBlock
        EV_WriteBlock_ECU_STATE_TIMING_PARAMETERS: start-on-event=RE_WriteBlock, operation=PS_ECU_STATE_TIMING_PARAMETERS.WriteBlock
        EV_WritePRAMBlock_ECU_STATE_TIMING_PARAMETERS: start-on-event=RE_WritePRAMBlock, operation=PS_ECU_STATE_TIMING_PARAMETERS.WritePRAMBlock
        EV_RestoreBlockDefaults_ECU_STATE_TIMING_PARAMETERS: start-on-event=RE_RestoreBlockDefaults, operation=PS_ECU_STATE_TIMING_PARAMETERS.RestoreBlockDefaults
        EV_RestorePRAMBlockDefaults_ECU_STATE_TIMING_PARAMETERS: start-on-event=RE_RestorePRAMBlockDefaults, operation=PS_ECU_STATE_TIMING_PARAMETERS.RestorePRAMBlockDefaults
        EV_EraseBlock_ECU_STATE_TIMING_PARAMETERS: start-on-event=RE_EraseBlock, operation=PS_ECU_STATE_TIMING_PARAMETERS.EraseBlock
        EV_InvalidateNvBlock_ECU_STATE_TIMING_PARAMETERS: start-on-event=RE_InvalidateNvBlock, operation=PS_ECU_STATE_TIMING_PARAMETERS.InvalidateNvBlock
        EV_GetErrorStatus_SPARE_PART_NUMBER: start-on-event=RE_GetErrorStatus, operation=PS_SPARE_PART_NUMBER.GetErrorStatus
        EV_SetDataIndex_SPARE_PART_NUMBER: start-on-event=RE_SetDataIndex, operation=PS_SPARE_PART_NUMBER.SetDataIndex
        EV_GetDataIndex_SPARE_PART_NUMBER: start-on-event=RE_GetDataIndex, operation=PS_SPARE_PART_NUMBER.GetDataIndex
        EV_SetRamBlockStatus_SPARE_PART_NUMBER: start-on-event=RE_SetRamBlockStatus, operation=PS_SPARE_PART_NUMBER.SetRamBlockStatus
        EV_ReadBlock_SPARE_PART_NUMBER: start-on-event=RE_ReadBlock, operation=PS_SPARE_PART_NUMBER.ReadBlock
        EV_ReadPRAMBlock_SPARE_PART_NUMBER: start-on-event=RE_ReadPRAMBlock, operation=PS_SPARE_PART_NUMBER.ReadPRAMBlock
        EV_WriteBlock_SPARE_PART_NUMBER: start-on-event=RE_WriteBlock, operation=PS_SPARE_PART_NUMBER.WriteBlock
        EV_WritePRAMBlock_SPARE_PART_NUMBER: start-on-event=RE_WritePRAMBlock, operation=PS_SPARE_PART_NUMBER.WritePRAMBlock
        EV_RestoreBlockDefaults_SPARE_PART_NUMBER: start-on-event=RE_RestoreBlockDefaults, operation=PS_SPARE_PART_NUMBER.RestoreBlockDefaults
        EV_RestorePRAMBlockDefaults_SPARE_PART_NUMBER: start-on-event=RE_RestorePRAMBlockDefaults, operation=PS_SPARE_PART_NUMBER.RestorePRAMBlockDefaults
        EV_EraseBlock_SPARE_PART_NUMBER: start-on-event=RE_EraseBlock, operation=PS_SPARE_PART_NUMBER.EraseBlock
        EV_InvalidateNvBlock_SPARE_PART_NUMBER: start-on-event=RE_InvalidateNvBlock, operation=PS_SPARE_PART_NUMBER.InvalidateNvBlock
        EV_GetErrorStatus_HARDWARE_NUMBER: start-on-event=RE_GetErrorStatus, operation=PS_HARDWARE_NUMBER.GetErrorStatus
        EV_SetDataIndex_HARDWARE_NUMBER: start-on-event=RE_SetDataIndex, operation=PS_HARDWARE_NUMBER.SetDataIndex
        EV_GetDataIndex_HARDWARE_NUMBER: start-on-event=RE_GetDataIndex, operation=PS_HARDWARE_NUMBER.GetDataIndex
        EV_SetRamBlockStatus_HARDWARE_NUMBER: start-on-event=RE_SetRamBlockStatus, operation=PS_HARDWARE_NUMBER.SetRamBlockStatus
        EV_ReadBlock_HARDWARE_NUMBER: start-on-event=RE_ReadBlock, operation=PS_HARDWARE_NUMBER.ReadBlock
        EV_ReadPRAMBlock_HARDWARE_NUMBER: start-on-event=RE_ReadPRAMBlock, operation=PS_HARDWARE_NUMBER.ReadPRAMBlock
        EV_WriteBlock_HARDWARE_NUMBER: start-on-event=RE_WriteBlock, operation=PS_HARDWARE_NUMBER.WriteBlock
        EV_WritePRAMBlock_HARDWARE_NUMBER: start-on-event=RE_WritePRAMBlock, operation=PS_HARDWARE_NUMBER.WritePRAMBlock
        EV_RestoreBlockDefaults_HARDWARE_NUMBER: start-on-event=RE_RestoreBlockDefaults, operation=PS_HARDWARE_NUMBER.RestoreBlockDefaults
        EV_RestorePRAMBlockDefaults_HARDWARE_NUMBER: start-on-event=RE_RestorePRAMBlockDefaults, operation=PS_HARDWARE_NUMBER.RestorePRAMBlockDefaults
        EV_EraseBlock_HARDWARE_NUMBER: start-on-event=RE_EraseBlock, operation=PS_HARDWARE_NUMBER.EraseBlock
        EV_InvalidateNvBlock_HARDWARE_NUMBER: start-on-event=RE_InvalidateNvBlock, operation=PS_HARDWARE_NUMBER.InvalidateNvBlock
        EV_GetErrorStatus_SYSTEM_NAME_OR_ENGINE_TYPE: start-on-event=RE_GetErrorStatus, operation=PS_SYSTEM_NAME_OR_ENGINE_TYPE.GetErrorStatus
        EV_SetDataIndex_SYSTEM_NAME_OR_ENGINE_TYPE: start-on-event=RE_SetDataIndex, operation=PS_SYSTEM_NAME_OR_ENGINE_TYPE.SetDataIndex
        EV_GetDataIndex_SYSTEM_NAME_OR_ENGINE_TYPE: start-on-event=RE_GetDataIndex, operation=PS_SYSTEM_NAME_OR_ENGINE_TYPE.GetDataIndex
        EV_SetRamBlockStatus_SYSTEM_NAME_OR_ENGINE_TYPE: start-on-event=RE_SetRamBlockStatus, operation=PS_SYSTEM_NAME_OR_ENGINE_TYPE.SetRamBlockStatus
        EV_ReadBlock_SYSTEM_NAME_OR_ENGINE_TYPE: start-on-event=RE_ReadBlock, operation=PS_SYSTEM_NAME_OR_ENGINE_TYPE.ReadBlock
        EV_ReadPRAMBlock_SYSTEM_NAME_OR_ENGINE_TYPE: start-on-event=RE_ReadPRAMBlock, operation=PS_SYSTEM_NAME_OR_ENGINE_TYPE.ReadPRAMBlock
        EV_WriteBlock_SYSTEM_NAME_OR_ENGINE_TYPE: start-on-event=RE_WriteBlock, operation=PS_SYSTEM_NAME_OR_ENGINE_TYPE.WriteBlock
        EV_WritePRAMBlock_SYSTEM_NAME_OR_ENGINE_TYPE: start-on-event=RE_WritePRAMBlock, operation=PS_SYSTEM_NAME_OR_ENGINE_TYPE.WritePRAMBlock
        EV_RestoreBlockDefaults_SYSTEM_NAME_OR_ENGINE_TYPE: start-on-event=RE_RestoreBlockDefaults, operation=PS_SYSTEM_NAME_OR_ENGINE_TYPE.RestoreBlockDefaults
        EV_RestorePRAMBlockDefaults_SYSTEM_NAME_OR_ENGINE_TYPE: start-on-event=RE_RestorePRAMBlockDefaults, operation=PS_SYSTEM_NAME_OR_ENGINE_TYPE.RestorePRAMBlockDefaults
        EV_EraseBlock_SYSTEM_NAME_OR_ENGINE_TYPE: start-on-event=RE_EraseBlock, operation=PS_SYSTEM_NAME_OR_ENGINE_TYPE.EraseBlock
        EV_InvalidateNvBlock_SYSTEM_NAME_OR_ENGINE_TYPE: start-on-event=RE_InvalidateNvBlock, operation=PS_SYSTEM_NAME_OR_ENGINE_TYPE.InvalidateNvBlock
        EV_GetErrorStatus_BLOCK_FBL: start-on-event=RE_GetErrorStatus, operation=PS_BLOCK_FBL.GetErrorStatus
        EV_SetDataIndex_BLOCK_FBL: start-on-event=RE_SetDataIndex, operation=PS_BLOCK_FBL.SetDataIndex
        EV_GetDataIndex_BLOCK_FBL: start-on-event=RE_GetDataIndex, operation=PS_BLOCK_FBL.GetDataIndex
        EV_SetRamBlockStatus_BLOCK_FBL: start-on-event=RE_SetRamBlockStatus, operation=PS_BLOCK_FBL.SetRamBlockStatus
        EV_ReadBlock_BLOCK_FBL: start-on-event=RE_ReadBlock, operation=PS_BLOCK_FBL.ReadBlock
        EV_ReadPRAMBlock_BLOCK_FBL: start-on-event=RE_ReadPRAMBlock, operation=PS_BLOCK_FBL.ReadPRAMBlock
        EV_WriteBlock_BLOCK_FBL: start-on-event=RE_WriteBlock, operation=PS_BLOCK_FBL.WriteBlock
        EV_WritePRAMBlock_BLOCK_FBL: start-on-event=RE_WritePRAMBlock, operation=PS_BLOCK_FBL.WritePRAMBlock
        EV_RestoreBlockDefaults_BLOCK_FBL: start-on-event=RE_RestoreBlockDefaults, operation=PS_BLOCK_FBL.RestoreBlockDefaults
        EV_RestorePRAMBlockDefaults_BLOCK_FBL: start-on-event=RE_RestorePRAMBlockDefaults, operation=PS_BLOCK_FBL.RestorePRAMBlockDefaults
        EV_EraseBlock_BLOCK_FBL: start-on-event=RE_EraseBlock, operation=PS_BLOCK_FBL.EraseBlock
        EV_InvalidateNvBlock_BLOCK_FBL: start-on-event=RE_InvalidateNvBlock, operation=PS_BLOCK_FBL.InvalidateNvBlock
        EV_GetErrorStatus_ODX_FILE_IDENTIFIER: start-on-event=RE_GetErrorStatus, operation=PS_ODX_FILE_IDENTIFIER.GetErrorStatus
        EV_SetDataIndex_ODX_FILE_IDENTIFIER: start-on-event=RE_SetDataIndex, operation=PS_ODX_FILE_IDENTIFIER.SetDataIndex
        EV_GetDataIndex_ODX_FILE_IDENTIFIER: start-on-event=RE_GetDataIndex, operation=PS_ODX_FILE_IDENTIFIER.GetDataIndex
        EV_SetRamBlockStatus_ODX_FILE_IDENTIFIER: start-on-event=RE_SetRamBlockStatus, operation=PS_ODX_FILE_IDENTIFIER.SetRamBlockStatus
        EV_ReadBlock_ODX_FILE_IDENTIFIER: start-on-event=RE_ReadBlock, operation=PS_ODX_FILE_IDENTIFIER.ReadBlock
        EV_ReadPRAMBlock_ODX_FILE_IDENTIFIER: start-on-event=RE_ReadPRAMBlock, operation=PS_ODX_FILE_IDENTIFIER.ReadPRAMBlock
        EV_WriteBlock_ODX_FILE_IDENTIFIER: start-on-event=RE_WriteBlock, operation=PS_ODX_FILE_IDENTIFIER.WriteBlock
        EV_WritePRAMBlock_ODX_FILE_IDENTIFIER: start-on-event=RE_WritePRAMBlock, operation=PS_ODX_FILE_IDENTIFIER.WritePRAMBlock
        EV_RestoreBlockDefaults_ODX_FILE_IDENTIFIER: start-on-event=RE_RestoreBlockDefaults, operation=PS_ODX_FILE_IDENTIFIER.RestoreBlockDefaults
        EV_RestorePRAMBlockDefaults_ODX_FILE_IDENTIFIER: start-on-event=RE_RestorePRAMBlockDefaults, operation=PS_ODX_FILE_IDENTIFIER.RestorePRAMBlockDefaults
        EV_EraseBlock_ODX_FILE_IDENTIFIER: start-on-event=RE_EraseBlock, operation=PS_ODX_FILE_IDENTIFIER.EraseBlock
        EV_InvalidateNvBlock_ODX_FILE_IDENTIFIER: start-on-event=RE_InvalidateNvBlock, operation=PS_ODX_FILE_IDENTIFIER.InvalidateNvBlock
        EV_GetErrorStatus_ODX_FILE_VERSION: start-on-event=RE_GetErrorStatus, operation=PS_ODX_FILE_VERSION.GetErrorStatus
        EV_SetDataIndex_ODX_FILE_VERSION: start-on-event=RE_SetDataIndex, operation=PS_ODX_FILE_VERSION.SetDataIndex
        EV_GetDataIndex_ODX_FILE_VERSION: start-on-event=RE_GetDataIndex, operation=PS_ODX_FILE_VERSION.GetDataIndex
        EV_SetRamBlockStatus_ODX_FILE_VERSION: start-on-event=RE_SetRamBlockStatus, operation=PS_ODX_FILE_VERSION.SetRamBlockStatus
        EV_ReadBlock_ODX_FILE_VERSION: start-on-event=RE_ReadBlock, operation=PS_ODX_FILE_VERSION.ReadBlock
        EV_ReadPRAMBlock_ODX_FILE_VERSION: start-on-event=RE_ReadPRAMBlock, operation=PS_ODX_FILE_VERSION.ReadPRAMBlock
        EV_WriteBlock_ODX_FILE_VERSION: start-on-event=RE_WriteBlock, operation=PS_ODX_FILE_VERSION.WriteBlock
        EV_WritePRAMBlock_ODX_FILE_VERSION: start-on-event=RE_WritePRAMBlock, operation=PS_ODX_FILE_VERSION.WritePRAMBlock
        EV_RestoreBlockDefaults_ODX_FILE_VERSION: start-on-event=RE_RestoreBlockDefaults, operation=PS_ODX_FILE_VERSION.RestoreBlockDefaults
        EV_RestorePRAMBlockDefaults_ODX_FILE_VERSION: start-on-event=RE_RestorePRAMBlockDefaults, operation=PS_ODX_FILE_VERSION.RestorePRAMBlockDefaults
        EV_EraseBlock_ODX_FILE_VERSION: start-on-event=RE_EraseBlock, operation=PS_ODX_FILE_VERSION.EraseBlock
        EV_InvalidateNvBlock_ODX_FILE_VERSION: start-on-event=RE_InvalidateNvBlock, operation=PS_ODX_FILE_VERSION.InvalidateNvBlock
        EV_GetErrorStatus_ECU_SERIAL_NUMBER: start-on-event=RE_GetErrorStatus, operation=PS_ECU_SERIAL_NUMBER.GetErrorStatus
        EV_SetDataIndex_ECU_SERIAL_NUMBER: start-on-event=RE_SetDataIndex, operation=PS_ECU_SERIAL_NUMBER.SetDataIndex
        EV_GetDataIndex_ECU_SERIAL_NUMBER: start-on-event=RE_GetDataIndex, operation=PS_ECU_SERIAL_NUMBER.GetDataIndex
        EV_SetRamBlockStatus_ECU_SERIAL_NUMBER: start-on-event=RE_SetRamBlockStatus, operation=PS_ECU_SERIAL_NUMBER.SetRamBlockStatus
        EV_ReadBlock_ECU_SERIAL_NUMBER: start-on-event=RE_ReadBlock, operation=PS_ECU_SERIAL_NUMBER.ReadBlock
        EV_ReadPRAMBlock_ECU_SERIAL_NUMBER: start-on-event=RE_ReadPRAMBlock, operation=PS_ECU_SERIAL_NUMBER.ReadPRAMBlock
        EV_WriteBlock_ECU_SERIAL_NUMBER: start-on-event=RE_WriteBlock, operation=PS_ECU_SERIAL_NUMBER.WriteBlock
        EV_WritePRAMBlock_ECU_SERIAL_NUMBER: start-on-event=RE_WritePRAMBlock, operation=PS_ECU_SERIAL_NUMBER.WritePRAMBlock
        EV_RestoreBlockDefaults_ECU_SERIAL_NUMBER: start-on-event=RE_RestoreBlockDefaults, operation=PS_ECU_SERIAL_NUMBER.RestoreBlockDefaults
        EV_RestorePRAMBlockDefaults_ECU_SERIAL_NUMBER: start-on-event=RE_RestorePRAMBlockDefaults, operation=PS_ECU_SERIAL_NUMBER.RestorePRAMBlockDefaults
        EV_EraseBlock_ECU_SERIAL_NUMBER: start-on-event=RE_EraseBlock, operation=PS_ECU_SERIAL_NUMBER.EraseBlock
        EV_InvalidateNvBlock_ECU_SERIAL_NUMBER: start-on-event=RE_InvalidateNvBlock, operation=PS_ECU_SERIAL_NUMBER.InvalidateNvBlock
        EV_GetErrorStatus_LOGICAL_SW_BLOCK_VERSION: start-on-event=RE_GetErrorStatus, operation=PS_LOGICAL_SW_BLOCK_VERSION.GetErrorStatus
        EV_SetDataIndex_LOGICAL_SW_BLOCK_VERSION: start-on-event=RE_SetDataIndex, operation=PS_LOGICAL_SW_BLOCK_VERSION.SetDataIndex
        EV_GetDataIndex_LOGICAL_SW_BLOCK_VERSION: start-on-event=RE_GetDataIndex, operation=PS_LOGICAL_SW_BLOCK_VERSION.GetDataIndex
        EV_SetRamBlockStatus_LOGICAL_SW_BLOCK_VERSION: start-on-event=RE_SetRamBlockStatus, operation=PS_LOGICAL_SW_BLOCK_VERSION.SetRamBlockStatus
        EV_ReadBlock_LOGICAL_SW_BLOCK_VERSION: start-on-event=RE_ReadBlock, operation=PS_LOGICAL_SW_BLOCK_VERSION.ReadBlock
        EV_ReadPRAMBlock_LOGICAL_SW_BLOCK_VERSION: start-on-event=RE_ReadPRAMBlock, operation=PS_LOGICAL_SW_BLOCK_VERSION.ReadPRAMBlock
        EV_WriteBlock_LOGICAL_SW_BLOCK_VERSION: start-on-event=RE_WriteBlock, operation=PS_LOGICAL_SW_BLOCK_VERSION.WriteBlock
        EV_WritePRAMBlock_LOGICAL_SW_BLOCK_VERSION: start-on-event=RE_WritePRAMBlock, operation=PS_LOGICAL_SW_BLOCK_VERSION.WritePRAMBlock
        EV_RestoreBlockDefaults_LOGICAL_SW_BLOCK_VERSION: start-on-event=RE_RestoreBlockDefaults, operation=PS_LOGICAL_SW_BLOCK_VERSION.RestoreBlockDefaults
        EV_RestorePRAMBlockDefaults_LOGICAL_SW_BLOCK_VERSION: start-on-event=RE_RestorePRAMBlockDefaults, operation=PS_LOGICAL_SW_BLOCK_VERSION.RestorePRAMBlockDefaults
        EV_EraseBlock_LOGICAL_SW_BLOCK_VERSION: start-on-event=RE_EraseBlock, operation=PS_LOGICAL_SW_BLOCK_VERSION.EraseBlock
        EV_InvalidateNvBlock_LOGICAL_SW_BLOCK_VERSION: start-on-event=RE_InvalidateNvBlock, operation=PS_LOGICAL_SW_BLOCK_VERSION.InvalidateNvBlock
        EV_GetErrorStatus_HARDWARE_VERSION_NUMBER: start-on-event=RE_GetErrorStatus, operation=PS_HARDWARE_VERSION_NUMBER.GetErrorStatus
        EV_SetDataIndex_HARDWARE_VERSION_NUMBER: start-on-event=RE_SetDataIndex, operation=PS_HARDWARE_VERSION_NUMBER.SetDataIndex
        EV_GetDataIndex_HARDWARE_VERSION_NUMBER: start-on-event=RE_GetDataIndex, operation=PS_HARDWARE_VERSION_NUMBER.GetDataIndex
        EV_SetRamBlockStatus_HARDWARE_VERSION_NUMBER: start-on-event=RE_SetRamBlockStatus, operation=PS_HARDWARE_VERSION_NUMBER.SetRamBlockStatus
        EV_ReadBlock_HARDWARE_VERSION_NUMBER: start-on-event=RE_ReadBlock, operation=PS_HARDWARE_VERSION_NUMBER.ReadBlock
        EV_ReadPRAMBlock_HARDWARE_VERSION_NUMBER: start-on-event=RE_ReadPRAMBlock, operation=PS_HARDWARE_VERSION_NUMBER.ReadPRAMBlock
        EV_WriteBlock_HARDWARE_VERSION_NUMBER: start-on-event=RE_WriteBlock, operation=PS_HARDWARE_VERSION_NUMBER.WriteBlock
        EV_WritePRAMBlock_HARDWARE_VERSION_NUMBER: start-on-event=RE_WritePRAMBlock, operation=PS_HARDWARE_VERSION_NUMBER.WritePRAMBlock
        EV_RestoreBlockDefaults_HARDWARE_VERSION_NUMBER: start-on-event=RE_RestoreBlockDefaults, operation=PS_HARDWARE_VERSION_NUMBER.RestoreBlockDefaults
        EV_RestorePRAMBlockDefaults_HARDWARE_VERSION_NUMBER: start-on-event=RE_RestorePRAMBlockDefaults, operation=PS_HARDWARE_VERSION_NUMBER.RestorePRAMBlockDefaults
        EV_EraseBlock_HARDWARE_VERSION_NUMBER: start-on-event=RE_EraseBlock, operation=PS_HARDWARE_VERSION_NUMBER.EraseBlock
        EV_InvalidateNvBlock_HARDWARE_VERSION_NUMBER: start-on-event=RE_InvalidateNvBlock, operation=PS_HARDWARE_VERSION_NUMBER.InvalidateNvBlock
        EV_GetErrorStatus_APP_SOFTWARE_VERSION_NUMBER: start-on-event=RE_GetErrorStatus, operation=PS_APP_SOFTWARE_VERSION_NUMBER.GetErrorStatus
        EV_SetDataIndex_APP_SOFTWARE_VERSION_NUMBER: start-on-event=RE_SetDataIndex, operation=PS_APP_SOFTWARE_VERSION_NUMBER.SetDataIndex
        EV_GetDataIndex_APP_SOFTWARE_VERSION_NUMBER: start-on-event=RE_GetDataIndex, operation=PS_APP_SOFTWARE_VERSION_NUMBER.GetDataIndex
        EV_SetRamBlockStatus_APP_SOFTWARE_VERSION_NUMBER: start-on-event=RE_SetRamBlockStatus, operation=PS_APP_SOFTWARE_VERSION_NUMBER.SetRamBlockStatus
        EV_ReadBlock_APP_SOFTWARE_VERSION_NUMBER: start-on-event=RE_ReadBlock, operation=PS_APP_SOFTWARE_VERSION_NUMBER.ReadBlock
        EV_ReadPRAMBlock_APP_SOFTWARE_VERSION_NUMBER: start-on-event=RE_ReadPRAMBlock, operation=PS_APP_SOFTWARE_VERSION_NUMBER.ReadPRAMBlock
        EV_WriteBlock_APP_SOFTWARE_VERSION_NUMBER: start-on-event=RE_WriteBlock, operation=PS_APP_SOFTWARE_VERSION_NUMBER.WriteBlock
        EV_WritePRAMBlock_APP_SOFTWARE_VERSION_NUMBER: start-on-event=RE_WritePRAMBlock, operation=PS_APP_SOFTWARE_VERSION_NUMBER.WritePRAMBlock
        EV_RestoreBlockDefaults_APP_SOFTWARE_VERSION_NUMBER: start-on-event=RE_RestoreBlockDefaults, operation=PS_APP_SOFTWARE_VERSION_NUMBER.RestoreBlockDefaults
        EV_RestorePRAMBlockDefaults_APP_SOFTWARE_VERSION_NUMBER: start-on-event=RE_RestorePRAMBlockDefaults, operation=PS_APP_SOFTWARE_VERSION_NUMBER.RestorePRAMBlockDefaults
        EV_EraseBlock_APP_SOFTWARE_VERSION_NUMBER: start-on-event=RE_EraseBlock, operation=PS_APP_SOFTWARE_VERSION_NUMBER.EraseBlock
        EV_InvalidateNvBlock_APP_SOFTWARE_VERSION_NUMBER: start-on-event=RE_InvalidateNvBlock, operation=PS_APP_SOFTWARE_VERSION_NUMBER.InvalidateNvBlock
        EV_GetErrorStatus_ECS_STEPS: start-on-event=RE_GetErrorStatus, operation=PS_ECS_STEPS.GetErrorStatus
        EV_SetDataIndex_ECS_STEPS: start-on-event=RE_SetDataIndex, operation=PS_ECS_STEPS.SetDataIndex
        EV_GetDataIndex_ECS_STEPS: start-on-event=RE_GetDataIndex, operation=PS_ECS_STEPS.GetDataIndex
        EV_SetRamBlockStatus_ECS_STEPS: start-on-event=RE_SetRamBlockStatus, operation=PS_ECS_STEPS.SetRamBlockStatus
        EV_ReadBlock_ECS_STEPS: start-on-event=RE_ReadBlock, operation=PS_ECS_STEPS.ReadBlock
        EV_ReadPRAMBlock_ECS_STEPS: start-on-event=RE_ReadPRAMBlock, operation=PS_ECS_STEPS.ReadPRAMBlock
        EV_WriteBlock_ECS_STEPS: start-on-event=RE_WriteBlock, operation=PS_ECS_STEPS.WriteBlock
        EV_WritePRAMBlock_ECS_STEPS: start-on-event=RE_WritePRAMBlock, operation=PS_ECS_STEPS.WritePRAMBlock
        EV_RestoreBlockDefaults_ECS_STEPS: start-on-event=RE_RestoreBlockDefaults, operation=PS_ECS_STEPS.RestoreBlockDefaults
        EV_RestorePRAMBlockDefaults_ECS_STEPS: start-on-event=RE_RestorePRAMBlockDefaults, operation=PS_ECS_STEPS.RestorePRAMBlockDefaults
        EV_EraseBlock_ECS_STEPS: start-on-event=RE_EraseBlock, operation=PS_ECS_STEPS.EraseBlock
        EV_InvalidateNvBlock_ECS_STEPS: start-on-event=RE_InvalidateNvBlock, operation=PS_ECS_STEPS.InvalidateNvBlock
        EV_GetErrorStatus_ECS_PARAMETERS: start-on-event=RE_GetErrorStatus, operation=PS_ECS_PARAMETERS.GetErrorStatus
        EV_SetDataIndex_ECS_PARAMETERS: start-on-event=RE_SetDataIndex, operation=PS_ECS_PARAMETERS.SetDataIndex
        EV_GetDataIndex_ECS_PARAMETERS: start-on-event=RE_GetDataIndex, operation=PS_ECS_PARAMETERS.GetDataIndex
        EV_SetRamBlockStatus_ECS_PARAMETERS: start-on-event=RE_SetRamBlockStatus, operation=PS_ECS_PARAMETERS.SetRamBlockStatus
        EV_ReadBlock_ECS_PARAMETERS: start-on-event=RE_ReadBlock, operation=PS_ECS_PARAMETERS.ReadBlock
        EV_ReadPRAMBlock_ECS_PARAMETERS: start-on-event=RE_ReadPRAMBlock, operation=PS_ECS_PARAMETERS.ReadPRAMBlock
        EV_WriteBlock_ECS_PARAMETERS: start-on-event=RE_WriteBlock, operation=PS_ECS_PARAMETERS.WriteBlock
        EV_WritePRAMBlock_ECS_PARAMETERS: start-on-event=RE_WritePRAMBlock, operation=PS_ECS_PARAMETERS.WritePRAMBlock
        EV_RestoreBlockDefaults_ECS_PARAMETERS: start-on-event=RE_RestoreBlockDefaults, operation=PS_ECS_PARAMETERS.RestoreBlockDefaults
        EV_RestorePRAMBlockDefaults_ECS_PARAMETERS: start-on-event=RE_RestorePRAMBlockDefaults, operation=PS_ECS_PARAMETERS.RestorePRAMBlockDefaults
        EV_EraseBlock_ECS_PARAMETERS: start-on-event=RE_EraseBlock, operation=PS_ECS_PARAMETERS.EraseBlock
        EV_InvalidateNvBlock_ECS_PARAMETERS: start-on-event=RE_InvalidateNvBlock, operation=PS_ECS_PARAMETERS.InvalidateNvBlock
      port-api-options:
        {enable-take-address=true, indirect-api=false, port-defined-argument-value{value=2, value-type=NvM_ASR42_BlockIdType}, port=PS_ASR42_NVM_BLOCK_DEM_DEFAULT}
        {enable-take-address=true, indirect-api=false, port-defined-argument-value{value=3, value-type=NvM_ASR42_BlockIdType}, port=PS_ASR42_ECC_COUNTERS}
        {enable-take-address=true, indirect-api=false, port-defined-argument-value{value=4, value-type=NvM_ASR42_BlockIdType}, port=PS_ASR42_WARM_RESET_COUNTERS}
        {enable-take-address=true, indirect-api=false, port-defined-argument-value{value=5, value-type=NvM_ASR42_BlockIdType}, port=PS_ASR42_SOLENOID_UNLOCK_CONF_PARAM}
        {enable-take-address=true, indirect-api=false, port-defined-argument-value{value=6, value-type=NvM_ASR42_BlockIdType}, port=PS_ASR42_AUTOTEST_ENABLE_PARAM}
        {enable-take-address=true, indirect-api=false, port-defined-argument-value{value=7, value-type=NvM_ASR42_BlockIdType}, port=PS_ASR42_LOCK_UNLOCK_ECU}
        {enable-take-address=true, indirect-api=false, port-defined-argument-value{value=8, value-type=NvM_ASR42_BlockIdType}, port=PS_ASR42_MEASUREMENT_FRAME_CONFIG}
        {enable-take-address=true, indirect-api=false, port-defined-argument-value{value=9, value-type=NvM_ASR42_BlockIdType}, port=PS_ASR42_HW_PART_NUMBER}
        {enable-take-address=true, indirect-api=false, port-defined-argument-value{value=10, value-type=NvM_ASR42_BlockIdType}, port=PS_ASR42_AEE_TRACEABILITY_NUMBER}
        {enable-take-address=true, indirect-api=false, port-defined-argument-value{value=11, value-type=NvM_ASR42_BlockIdType}, port=PS_ASR42_ECU_ASSEMBLY_SERIAL_NUMBER}
        {enable-take-address=true, indirect-api=false, port-defined-argument-value{value=12, value-type=NvM_ASR42_BlockIdType}, port=PS_ASR42_PROCESS_MODE}
        {enable-take-address=true, indirect-api=false, port-defined-argument-value{value=13, value-type=NvM_ASR42_BlockIdType}, port=PS_ASR42_ECS_VARIANT}
        {enable-take-address=true, indirect-api=false, port-defined-argument-value{value=14, value-type=NvM_ASR42_BlockIdType}, port=PS_ASR42_RESERVED_1}
        {enable-take-address=true, indirect-api=false, port-defined-argument-value{value=15, value-type=NvM_ASR42_BlockIdType}, port=PS_ASR42_ECS_ACC_OFFSETS}
        {enable-take-address=true, indirect-api=false, port-defined-argument-value{value=16, value-type=NvM_ASR42_BlockIdType}, port=PS_ASR42_ECS_BUCKLE_CONFIG}
        {enable-take-address=true, indirect-api=false, port-defined-argument-value{value=17, value-type=NvM_ASR42_BlockIdType}, port=PS_ASR42_ECS_CODING_VARIANT}
        {enable-take-address=true, indirect-api=false, port-defined-argument-value{value=18, value-type=NvM_ASR42_BlockIdType}, port=PS_ASR42_ECS_ACC_LOWPASS}
        {enable-take-address=true, indirect-api=false, port-defined-argument-value{value=19, value-type=NvM_ASR42_BlockIdType}, port=PS_ASR42_SBS_LAST_STATE}
        {enable-take-address=true, indirect-api=false, port-defined-argument-value{value=20, value-type=NvM_ASR42_BlockIdType}, port=PS_ASR42_ECS_ALGO_OUTPUT_DELAY}
        {enable-take-address=true, indirect-api=false, port-defined-argument-value{value=21, value-type=NvM_ASR42_BlockIdType}, port=PS_ASR42_ECS_SENSITIVITY_LUT}
        {enable-take-address=true, indirect-api=false, port-defined-argument-value{value=22, value-type=NvM_ASR42_BlockIdType}, port=PS_ASR42_ECS_SENSITIVITY_OPT}
        {enable-take-address=true, indirect-api=false, port-defined-argument-value{value=23, value-type=NvM_ASR42_BlockIdType}, port=PS_ASR42_ECU_TEMP_CALIBRATION}
        {enable-take-address=true, indirect-api=false, port-defined-argument-value{value=24, value-type=NvM_ASR42_BlockIdType}, port=PS_ASR42_ALV_NVM_VERSION}
        {enable-take-address=true, indirect-api=false, port-defined-argument-value{value=25, value-type=NvM_ASR42_BlockIdType}, port=PS_ASR42_MEAS_FRAME_RAM_ADDR_CFG}
        {enable-take-address=true, indirect-api=false, port-defined-argument-value{value=26, value-type=NvM_ASR42_BlockIdType}, port=PS_ASR42_ACC_AXIS_ANGLE_CALIBRATION}
        {enable-take-address=true, indirect-api=false, port-defined-argument-value{value=27, value-type=NvM_ASR42_BlockIdType}, port=PS_ASR42_EOL_COUNTERS}
        {enable-take-address=true, indirect-api=false, port-defined-argument-value{value=28, value-type=NvM_ASR42_BlockIdType}, port=PS_ASR42_RESERVED_4}
        {enable-take-address=true, indirect-api=false, port-defined-argument-value{value=29, value-type=NvM_ASR42_BlockIdType}, port=PS_ASR42_AUTOTEST_PARAM}
        {enable-take-address=true, indirect-api=false, port-defined-argument-value{value=30, value-type=NvM_ASR42_BlockIdType}, port=PS_ASR42_PHYS_MEASUREMENTS}
        {enable-take-address=true, indirect-api=false, port-defined-argument-value{value=31, value-type=NvM_ASR42_BlockIdType}, port=PS_ASR42_SOLENOID_PARAM}
        {enable-take-address=true, indirect-api=false, port-defined-argument-value{value=32, value-type=NvM_ASR42_BlockIdType}, port=PS_ASR42_ECS_PROFILES}
        {enable-take-address=true, indirect-api=false, port-defined-argument-value{value=33, value-type=NvM_ASR42_BlockIdType}, port=PS_ASR42_ECU_STATE_TIMING_PARAMETERS}
        {enable-take-address=true, indirect-api=false, port-defined-argument-value{value=34, value-type=NvM_ASR42_BlockIdType}, port=PS_ASR42_SPARE_PART_NUMBER}
        {enable-take-address=true, indirect-api=false, port-defined-argument-value{value=35, value-type=NvM_ASR42_BlockIdType}, port=PS_ASR42_HARDWARE_NUMBER}
        {enable-take-address=true, indirect-api=false, port-defined-argument-value{value=36, value-type=NvM_ASR42_BlockIdType}, port=PS_ASR42_SYSTEM_NAME_OR_ENGINE_TYPE}
        {enable-take-address=true, indirect-api=false, port-defined-argument-value{value=37, value-type=NvM_ASR42_BlockIdType}, port=PS_ASR42_BLOCK_FBL}
        {enable-take-address=true, indirect-api=false, port-defined-argument-value{value=38, value-type=NvM_ASR42_BlockIdType}, port=PS_ASR42_ODX_FILE_IDENTIFIER}
        {enable-take-address=true, indirect-api=false, port-defined-argument-value{value=39, value-type=NvM_ASR42_BlockIdType}, port=PS_ASR42_ODX_FILE_VERSION}
        {enable-take-address=true, indirect-api=false, port-defined-argument-value{value=40, value-type=NvM_ASR42_BlockIdType}, port=PS_ASR42_ECU_SERIAL_NUMBER}
        {enable-take-address=true, indirect-api=false, port-defined-argument-value{value=41, value-type=NvM_ASR42_BlockIdType}, port=PS_ASR42_LOGICAL_SW_BLOCK_VERSION}
        {enable-take-address=true, indirect-api=false, port-defined-argument-value{value=42, value-type=NvM_ASR42_BlockIdType}, port=PS_ASR42_HARDWARE_VERSION_NUMBER}
        {enable-take-address=true, indirect-api=false, port-defined-argument-value{value=43, value-type=NvM_ASR42_BlockIdType}, port=PS_ASR42_APP_SOFTWARE_VERSION_NUMBER}
        {enable-take-address=true, indirect-api=false, port-defined-argument-value{value=44, value-type=NvM_ASR42_BlockIdType}, port=PS_ASR42_ECS_STEPS}
        {enable-take-address=true, indirect-api=false, port-defined-argument-value{value=45, value-type=NvM_ASR42_BlockIdType}, port=PS_ASR42_ECS_PARAMETERS}
        {enable-take-address=true, indirect-api=false, port-defined-argument-value{value=2, value-type=NvM_BlockIdType}, port=PS_NVM_BLOCK_DEM_DEFAULT}
        {enable-take-address=true, indirect-api=false, port-defined-argument-value{value=3, value-type=NvM_BlockIdType}, port=PS_ECC_COUNTERS}
        {enable-take-address=true, indirect-api=false, port-defined-argument-value{value=4, value-type=NvM_BlockIdType}, port=PS_WARM_RESET_COUNTERS}
        {enable-take-address=true, indirect-api=false, port-defined-argument-value{value=5, value-type=NvM_BlockIdType}, port=PS_SOLENOID_UNLOCK_CONF_PARAM}
        {enable-take-address=true, indirect-api=false, port-defined-argument-value{value=6, value-type=NvM_BlockIdType}, port=PS_AUTOTEST_ENABLE_PARAM}
        {enable-take-address=true, indirect-api=false, port-defined-argument-value{value=7, value-type=NvM_BlockIdType}, port=PS_LOCK_UNLOCK_ECU}
        {enable-take-address=true, indirect-api=false, port-defined-argument-value{value=8, value-type=NvM_BlockIdType}, port=PS_MEASUREMENT_FRAME_CONFIG}
        {enable-take-address=true, indirect-api=false, port-defined-argument-value{value=9, value-type=NvM_BlockIdType}, port=PS_HW_PART_NUMBER}
        {enable-take-address=true, indirect-api=false, port-defined-argument-value{value=10, value-type=NvM_BlockIdType}, port=PS_AEE_TRACEABILITY_NUMBER}
        {enable-take-address=true, indirect-api=false, port-defined-argument-value{value=11, value-type=NvM_BlockIdType}, port=PS_ECU_ASSEMBLY_SERIAL_NUMBER}
        {enable-take-address=true, indirect-api=false, port-defined-argument-value{value=12, value-type=NvM_BlockIdType}, port=PS_PROCESS_MODE}
        {enable-take-address=true, indirect-api=false, port-defined-argument-value{value=13, value-type=NvM_BlockIdType}, port=PS_ECS_VARIANT}
        {enable-take-address=true, indirect-api=false, port-defined-argument-value{value=14, value-type=NvM_BlockIdType}, port=PS_RESERVED_1}
        {enable-take-address=true, indirect-api=false, port-defined-argument-value{value=15, value-type=NvM_BlockIdType}, port=PS_ECS_ACC_OFFSETS}
        {enable-take-address=true, indirect-api=false, port-defined-argument-value{value=16, value-type=NvM_BlockIdType}, port=PS_ECS_BUCKLE_CONFIG}
        {enable-take-address=true, indirect-api=false, port-defined-argument-value{value=17, value-type=NvM_BlockIdType}, port=PS_ECS_CODING_VARIANT}
        {enable-take-address=true, indirect-api=false, port-defined-argument-value{value=18, value-type=NvM_BlockIdType}, port=PS_ECS_ACC_LOWPASS}
        {enable-take-address=true, indirect-api=false, port-defined-argument-value{value=19, value-type=NvM_BlockIdType}, port=PS_SBS_LAST_STATE}
        {enable-take-address=true, indirect-api=false, port-defined-argument-value{value=20, value-type=NvM_BlockIdType}, port=PS_ECS_ALGO_OUTPUT_DELAY}
        {enable-take-address=true, indirect-api=false, port-defined-argument-value{value=21, value-type=NvM_BlockIdType}, port=PS_ECS_SENSITIVITY_LUT}
        {enable-take-address=true, indirect-api=false, port-defined-argument-value{value=22, value-type=NvM_BlockIdType}, port=PS_ECS_SENSITIVITY_OPT}
        {enable-take-address=true, indirect-api=false, port-defined-argument-value{value=23, value-type=NvM_BlockIdType}, port=PS_ECU_TEMP_CALIBRATION}
        {enable-take-address=true, indirect-api=false, port-defined-argument-value{value=24, value-type=NvM_BlockIdType}, port=PS_ALV_NVM_VERSION}
        {enable-take-address=true, indirect-api=false, port-defined-argument-value{value=25, value-type=NvM_BlockIdType}, port=PS_MEAS_FRAME_RAM_ADDR_CFG}
        {enable-take-address=true, indirect-api=false, port-defined-argument-value{value=26, value-type=NvM_BlockIdType}, port=PS_ACC_AXIS_ANGLE_CALIBRATION}
        {enable-take-address=true, indirect-api=false, port-defined-argument-value{value=27, value-type=NvM_BlockIdType}, port=PS_EOL_COUNTERS}
        {enable-take-address=true, indirect-api=false, port-defined-argument-value{value=28, value-type=NvM_BlockIdType}, port=PS_RESERVED_4}
        {enable-take-address=true, indirect-api=false, port-defined-argument-value{value=29, value-type=NvM_BlockIdType}, port=PS_AUTOTEST_PARAM}
        {enable-take-address=true, indirect-api=false, port-defined-argument-value{value=30, value-type=NvM_BlockIdType}, port=PS_PHYS_MEASUREMENTS}
        {enable-take-address=true, indirect-api=false, port-defined-argument-value{value=31, value-type=NvM_BlockIdType}, port=PS_SOLENOID_PARAM}
        {enable-take-address=true, indirect-api=false, port-defined-argument-value{value=32, value-type=NvM_BlockIdType}, port=PS_ECS_PROFILES}
        {enable-take-address=true, indirect-api=false, port-defined-argument-value{value=33, value-type=NvM_BlockIdType}, port=PS_ECU_STATE_TIMING_PARAMETERS}
        {enable-take-address=true, indirect-api=false, port-defined-argument-value{value=34, value-type=NvM_BlockIdType}, port=PS_SPARE_PART_NUMBER}
        {enable-take-address=true, indirect-api=false, port-defined-argument-value{value=35, value-type=NvM_BlockIdType}, port=PS_HARDWARE_NUMBER}
        {enable-take-address=true, indirect-api=false, port-defined-argument-value{value=36, value-type=NvM_BlockIdType}, port=PS_SYSTEM_NAME_OR_ENGINE_TYPE}
        {enable-take-address=true, indirect-api=false, port-defined-argument-value{value=37, value-type=NvM_BlockIdType}, port=PS_BLOCK_FBL}
        {enable-take-address=true, indirect-api=false, port-defined-argument-value{value=38, value-type=NvM_BlockIdType}, port=PS_ODX_FILE_IDENTIFIER}
        {enable-take-address=true, indirect-api=false, port-defined-argument-value{value=39, value-type=NvM_BlockIdType}, port=PS_ODX_FILE_VERSION}
        {enable-take-address=true, indirect-api=false, port-defined-argument-value{value=40, value-type=NvM_BlockIdType}, port=PS_ECU_SERIAL_NUMBER}
        {enable-take-address=true, indirect-api=false, port-defined-argument-value{value=41, value-type=NvM_BlockIdType}, port=PS_LOGICAL_SW_BLOCK_VERSION}
        {enable-take-address=true, indirect-api=false, port-defined-argument-value{value=42, value-type=NvM_BlockIdType}, port=PS_HARDWARE_VERSION_NUMBER}
        {enable-take-address=true, indirect-api=false, port-defined-argument-value{value=43, value-type=NvM_BlockIdType}, port=PS_APP_SOFTWARE_VERSION_NUMBER}
        {enable-take-address=true, indirect-api=false, port-defined-argument-value{value=44, value-type=NvM_BlockIdType}, port=PS_ECS_STEPS}
        {enable-take-address=true, indirect-api=false, port-defined-argument-value{value=45, value-type=NvM_BlockIdType}, port=PS_ECS_PARAMETERS}
      25 x runnable, all with can-be-invoked-concurrently=true:
        RE_MainFunction: symbol=NvM_MainFunction
        RE_ASR42_GetErrorStatus: arguments=[symbol=BlockId, symbol=RequestResultPtr], symbol=NvM_ASR42_Rte_GetErrorStatus
        RE_ASR42_SetDataIndex: arguments=[symbol=BlockId, symbol=DataIndex], symbol=NvM_ASR42_Rte_SetDataIndex
        RE_ASR42_GetDataIndex: arguments=[symbol=BlockId, symbol=DataIndex], symbol=NvM_ASR42_Rte_GetDataIndex
        RE_ASR42_SetRamBlockStatus: arguments=[symbol=BlockId, symbol=BlockChanged], symbol=NvM_ASR42_Rte_SetRamBlockStatus
        RE_ASR42_ReadBlock: arguments=[symbol=BlockId, symbol=NvM_DstPtr], symbol=NvM_ASR42_Rte_ReadBlock
        RE_ASR42_ReadPRAMBlock: runnable-entity-argument=symbol=BlockId, symbol=NvM_ASR42_Rte_ReadPRAMBlock
        RE_ASR42_WriteBlock: arguments=[symbol=BlockId, symbol=NvM_SrcPtr], symbol=NvM_ASR42_Rte_WriteBlock
        RE_ASR42_WritePRAMBlock: runnable-entity-argument=symbol=BlockId, symbol=NvM_ASR42_Rte_WritePRAMBlock
        RE_ASR42_RestoreBlockDefaults: arguments=[symbol=BlockId, symbol=NvM_DestPtr], symbol=NvM_ASR42_Rte_RestoreBlockDefaults
        RE_ASR42_RestorePRAMBlockDefaults: runnable-entity-argument=symbol=BlockId, symbol=NvM_ASR42_Rte_RestorePRAMBlockDefaults
        RE_ASR42_EraseBlock: runnable-entity-argument=symbol=BlockId, symbol=NvM_ASR42_Rte_EraseNvBlock
        RE_ASR42_InvalidateNvBlock: runnable-entity-argument=symbol=BlockId, symbol=NvM_ASR42_Rte_InvalidateNvBlock
        RE_GetErrorStatus: arguments=[symbol=BlockId, symbol=RequestResultPtr], symbol=NvM_Rte_GetErrorStatus
        RE_SetDataIndex: arguments=[symbol=BlockId, symbol=DataIndex], symbol=NvM_Rte_SetDataIndex
        RE_GetDataIndex: arguments=[symbol=BlockId, symbol=DataIndex], symbol=NvM_Rte_GetDataIndex
        RE_SetRamBlockStatus: arguments=[symbol=BlockId, symbol=BlockChanged], symbol=NvM_Rte_SetRamBlockStatus
        RE_ReadBlock: arguments=[symbol=BlockId, symbol=NvM_DstPtr], symbol=NvM_Rte_ReadBlock
        RE_ReadPRAMBlock: runnable-entity-argument=symbol=BlockId, symbol=NvM_Rte_ReadPRAMBlock
        RE_WriteBlock: arguments=[symbol=BlockId, symbol=NvM_SrcPtr], symbol=NvM_Rte_WriteBlock
        RE_WritePRAMBlock: runnable-entity-argument=symbol=BlockId, symbol=NvM_Rte_WritePRAMBlock
        RE_RestoreBlockDefaults: arguments=[symbol=BlockId, symbol=NvM_DestPtr], symbol=NvM_Rte_RestoreBlockDefaults
        RE_RestorePRAMBlockDefaults: runnable-entity-argument=symbol=BlockId, symbol=NvM_Rte_RestorePRAMBlockDefaults
        RE_EraseBlock: runnable-entity-argument=symbol=BlockId, symbol=NvM_Rte_EraseNvBlock
        RE_InvalidateNvBlock: runnable-entity-argument=symbol=BlockId, symbol=NvM_Rte_InvalidateNvBlock
package /EB_NvM/SwcImplementations
  swc implementation NvMImpl: programming-language=C, sw-version=1.0.0, vendor-id=1, behavior=NvMIntBeh
    code-descriptors:
      code Code: artifact-descriptors=autosar-engineering-object={short-label=EngObject, category=SWSRC}
    resource consumption Resources
      memory section CODE: sw-addrmethod=CODE
